VERSION ""

NS_ :

BS_:

BU_: SGW RFHM MPAD IPC GNMM EVCU2 ESL ECM DTCM DMSM BSM BCM AGSM ADCAM

BO_ 145 TELEMATIC_FD_19: 64 SGW
 SG_ Creep_Req : 389|1@0+ (1,0) [0|1] "" IPC
 SG_ PlugAndChargeReq : 385|1@0+ (1,0) [0|1] "" EVCU2
 SG_ StopOnTraffic_Req : 379|2@0+ (1,0) [0|2] "" IPC
 SG_ SpeedAdjust_Req : 380|1@0+ (1,0) [0|1] "" IPC
 SG_ RouteGuidance_Req : 383|1@0+ (1,0) [0|1] "" IPC
 SG_ EmergencyCorridorAssist_Req : 376|1@0+ (1,0) [0|1] "" IPC
 SG_ E_Coasting_Req : 399|3@0+ (1,0) [0|7] "" MPAD,EVCU2

BO_ 2654339283 PDC_INFO_FD_NFCD: 12 RFHM
 SG_ WakeupSource_FD09_NFCD : 23|8@0+ (1,0) [0|255] "" SGW
 SG_ StayActiveSource_FD09_NFCD : 31|64@0+ (1,0) [0|18446744073709551615] "" SGW
 SG_ PreviousCanNMState_FD09_NFCD : 11|4@0+ (1,0) [0|15] "" SGW
 SG_ GenericFailSts_FD09_NFCD : 5|1@0+ (1,0) [0|1] "" SGW,BCM
 SG_ EOL_FD09_NFCD : 7|1@0+ (1,0) [0|1] "-"  SGW,BCM
 SG_ DES_FD09_NFCD : 4|2@0+ (1,0) [0|3] "" SGW
 SG_ CurrentFailSts_FD09_NFCD : 6|1@0+ (1,0) [0|1] "" SGW,BCM
 SG_ CurrentCanNMState_FD09_NFCD : 15|4@0+ (1,0) [0|15] "" SGW

BO_ 2654339245 PDC_INFO_FD_MPAD: 12 MPAD
 SG_ WakeupSource_FD03_MPAD : 23|8@0+ (1,0) [0|255] "-"  SGW
 SG_ StayActiveSource_FD03_MPAD : 31|64@0+ (1,0) [0|18446744073709551615] "-"  SGW
 SG_ PreviousCanNMState_FD03_MPAD : 11|4@0+ (1,0) [0|15] "-"  SGW
 SG_ GenericFailSts_FD03_MPAD : 5|1@0+ (1,0) [0|1] "-"  SGW,BCM
 SG_ EOL_FD03_MPAD : 7|1@0+ (1,0) [0|1] "-"  SGW,BCM
 SG_ DES_FD03_MPAD : 4|2@0+ (1,0) [0|3] "-"  SGW
 SG_ CurrentFailSts_FD03_MPAD : 6|1@0+ (1,0) [0|1] "-"  SGW,BCM
 SG_ CurrentCanNMState_FD03_MPAD : 15|4@0+ (1,0) [0|15] "-"  SGW

BO_ 2654339233 PDC_INFO_FD_ADCAM: 12 ADCAM
 SG_ WakeupSource_FD03_ADCAM : 23|8@0+ (1,0) [0|255] "-"  SGW
 SG_ StayActiveSource_FD03_ADCAM : 31|64@0+ (1,0) [0|18446744073709551615] "-"  SGW
 SG_ PreviousCanNMState_FD03_ADCAM : 11|4@0+ (1,0) [0|15] "-"  SGW
 SG_ GenericFailSts_FD03_ADCAM : 5|1@0+ (1,0) [0|1] "-"  SGW,BCM
 SG_ EOL_FD03_ADCAM : 7|1@0+ (1,0) [0|1] "-"  SGW,BCM
 SG_ DES_FD03_ADCAM : 4|2@0+ (1,0) [0|3] "-"  SGW
 SG_ CurrentFailSts_FD03_ADCAM : 6|1@0+ (1,0) [0|1] "-"  SGW,BCM
 SG_ CurrentCanNMState_FD03_ADCAM : 15|4@0+ (1,0) [0|15] "-"  SGW

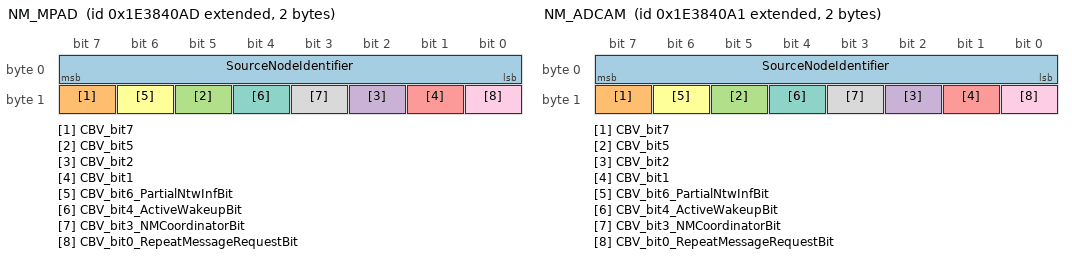
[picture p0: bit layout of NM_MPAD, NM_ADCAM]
BO_ 2654486701 NM_MPAD: 2 MPAD
 SG_ SourceNodeIdentifier : 7|8@0+ (1,0) [0|255] "-"  ADCAM,EVCU2,GNMM,SGW,AGSM,ESL,BCM,BSM,IPC,RFHM,ECM,DTCM
 SG_ CBV_bit7 : 15|1@0+ (1,0) [0|1] "" ADCAM,EVCU2,GNMM,SGW,AGSM,ESL,BCM,BSM,IPC,RFHM,ECM,DTCM
 SG_ CBV_bit5 : 13|1@0+ (1,0) [0|1] "" ADCAM,EVCU2,GNMM,SGW,AGSM,ESL,BCM,BSM,IPC,RFHM,ECM,DTCM
 SG_ CBV_bit2 : 10|1@0+ (1,0) [0|1] "" ADCAM,EVCU2,GNMM,SGW,AGSM,ESL,BCM,BSM,IPC,RFHM,ECM,DTCM
 SG_ CBV_bit1 : 9|1@0+ (1,0) [0|1] "" ADCAM,EVCU2,GNMM,SGW,AGSM,ESL,BCM,BSM,IPC,RFHM,ECM,DTCM
 SG_ CBV_bit6_PartialNtwInfBit : 14|1@0+ (1,0) [0|1] "-"  ADCAM,EVCU2,GNMM,SGW,AGSM,ESL,BCM,BSM,IPC,RFHM,ECM,DTCM
 SG_ CBV_bit4_ActiveWakeupBit : 12|1@0+ (1,0) [0|1] "-"  ADCAM,EVCU2,GNMM,SGW,AGSM,ESL,BCM,BSM,IPC,RFHM,ECM,DTCM
 SG_ CBV_bit3_NMCoordinatorBit : 11|1@0+ (1,0) [0|1] "-"  ADCAM,EVCU2,GNMM,SGW,AGSM,ESL,BCM,BSM,IPC,RFHM,ECM,DTCM
 SG_ CBV_bit0_RepeatMessageRequestBit : 8|1@0+ (1,0) [0|1] "-"  ADCAM,EVCU2,GNMM,SGW,AGSM,ESL,BCM,BSM,IPC,RFHM,ECM,DTCM

BO_ 2654486689 NM_ADCAM: 2 ADCAM
 SG_ SourceNodeIdentifier : 7|8@0+ (1,0) [0|255] "-"  MPAD,EVCU2,GNMM,SGW,AGSM,ESL,BCM,BSM,IPC,RFHM,ECM,DTCM
 SG_ CBV_bit7 : 15|1@0+ (1,0) [0|1] "" MPAD,EVCU2,GNMM,SGW,AGSM,ESL,BCM,BSM,IPC,RFHM,ECM,DTCM
 SG_ CBV_bit5 : 13|1@0+ (1,0) [0|1] "" MPAD,EVCU2,GNMM,SGW,AGSM,ESL,BCM,BSM,IPC,RFHM,ECM,DTCM
 SG_ CBV_bit2 : 10|1@0+ (1,0) [0|1] "" MPAD,EVCU2,GNMM,SGW,AGSM,ESL,BCM,BSM,IPC,RFHM,ECM,DTCM
 SG_ CBV_bit1 : 9|1@0+ (1,0) [0|1] "" MPAD,EVCU2,GNMM,SGW,AGSM,ESL,BCM,BSM,IPC,RFHM,ECM,DTCM
 SG_ CBV_bit6_PartialNtwInfBit : 14|1@0+ (1,0) [0|1] "-"  MPAD,EVCU2,GNMM,SGW,AGSM,ESL,BCM,BSM,IPC,RFHM,ECM,DTCM
 SG_ CBV_bit4_ActiveWakeupBit : 12|1@0+ (1,0) [0|1] "-"  MPAD,EVCU2,GNMM,SGW,AGSM,ESL,BCM,BSM,IPC,RFHM,ECM,DTCM
 SG_ CBV_bit3_NMCoordinatorBit : 11|1@0+ (1,0) [0|1] "-"  MPAD,EVCU2,GNMM,SGW,AGSM,ESL,BCM,BSM,IPC,RFHM,ECM,DTCM
 SG_ CBV_bit0_RepeatMessageRequestBit : 8|1@0+ (1,0) [0|1] "-"  MPAD,EVCU2,GNMM,SGW,AGSM,ESL,BCM,BSM,IPC,RFHM,ECM,DTCM

BO_ 1898 FOTA_RSP_MPAD: 32 MPAD
 SG_ Update_Status_MPAD : 5|2@0+ (1,0) [0|3] "" SGW
 SG_ Download_Status_MPAD : 7|2@0+ (1,0) [0|3] "" SGW
 SG_ Big_ECU_Ready_MPAD : 1|2@0+ (1,0) [0|3] "" SGW

BO_ 1900 FOTA_RSP_ADCAM: 32 ADCAM
 SG_ Update_Status_ADCAM : 5|2@0+ (1,0) [0|3] "" SGW
 SG_ Download_Status_ADCAM : 7|2@0+ (1,0) [0|3] "" SGW
 SG_ Big_ECU_Ready_ADCAM : 1|2@0+ (1,0) [0|3] "" SGW

BO_ 2564682142 DIAGNOSTIC_ROE_NFCD: 8 RFHM
 SG_ N_PDU : 7|64@0+ (1,0) [0|0] "" SGW

BO_ 2564682216 DIAGNOSTIC_ROE_MPAD: 8 MPAD
 SG_ N_PDU : 7|64@0+ (1,0) [0|0] "-"  SGW

BO_ 2564682398 DIAGNOSTIC_ROE_FD_NFCD: 64 RFHM
 SG_ N_PDU : 7|64@0+ (1,0) [0|0] "" SGW

BO_ 2564682472 DIAGNOSTIC_ROE_FD_MPAD: 64 MPAD
 SG_ N_PDU : 7|64@0+ (1,0) [0|0] "-"  SGW

BO_ 2564682306 DIAGNOSTIC_ROE_FD_EVCU2: 64 EVCU2
 SG_ N_PDU : 7|64@0+ (1,0) [0|0] "" SGW

BO_ 2564682279 DIAGNOSTIC_ROE_FD_ADCAM: 64 ADCAM
 SG_ N_PDU : 7|64@0+ (1,0) [0|0] "-"  SGW

BO_ 2564682050 DIAGNOSTIC_ROE_EVCU2: 8 EVCU2
 SG_ N_PDU : 7|64@0+ (1,0) [0|0] "" SGW

BO_ 2564682023 DIAGNOSTIC_ROE_ADCAM: 8 ADCAM
 SG_ N_PDU : 7|64@0+ (1,0) [0|0] "-"  SGW

BO_ 2564485534 DIAGNOSTIC_RESPONSE_NFCD: 8 RFHM
 SG_ N_PDU : 7|64@0+ (1,0) [0|0] "" SGW

BO_ 2564485608 DIAGNOSTIC_RESPONSE_MPAD: 8 MPAD
 SG_ N_PDU : 7|64@0+ (1,0) [0|0] "-"  SGW

BO_ 2564486632 DIAGNOSTIC_RESPONSE_FOTA_MPAD: 64 MPAD
 SG_ N_PDU : 7|64@0+ (1,0) [0|0] "" SGW

BO_ 2564486439 DIAGNOSTIC_RESPONSE_FOTA_ADCAM: 64 ADCAM
 SG_ N_PDU : 7|64@0+ (1,0) [0|0] "-"  SGW

BO_ 2564485790 DIAGNOSTIC_RESPONSE_FD_NFCD: 64 RFHM
 SG_ N_PDU : 7|64@0+ (1,0) [0|0] "" SGW

BO_ 2564485864 DIAGNOSTIC_RESPONSE_FD_MPAD: 64 MPAD
 SG_ N_PDU : 7|64@0+ (1,0) [0|0] "" SGW

BO_ 2564485698 DIAGNOSTIC_RESPONSE_FD_EVCU2: 64 EVCU2
 SG_ N_PDU : 7|64@0+ (1,0) [0|0] "" SGW

BO_ 2564485671 DIAGNOSTIC_RESPONSE_FD_ADCAM: 64 ADCAM
 SG_ N_PDU : 7|64@0+ (1,0) [0|0] "-"  SGW

BO_ 2564485442 DIAGNOSTIC_RESPONSE_EVCU2: 8 EVCU2
 SG_ N_PDU : 7|64@0+ (1,0) [0|0] "" SGW

BO_ 2564485415 DIAGNOSTIC_RESPONSE_ADCAM: 8 ADCAM
 SG_ N_PDU : 7|64@0+ (1,0) [0|0] "-"  SGW

BO_ 2564464369 DIAGNOSTIC_REQUEST_NFCD: 8 SGW
 SG_ N_PDU : 7|64@0+ (1,0) [0|0] "" RFHM

BO_ 2564483313 DIAGNOSTIC_REQUEST_MPAD: 8 SGW
 SG_ N_PDU : 7|64@0+ (1,0) [0|0] "-"  MPAD

BO_ 2564483317 DIAGNOSTIC_REQUEST_FOTA_MPAD: 64 SGW
 SG_ N_PDU : 7|64@0+ (1,0) [0|0] "-"  MPAD

BO_ 2564433909 DIAGNOSTIC_REQUEST_FOTA_ADCAM: 64 SGW
 SG_ N_PDU : 7|64@0+ (1,0) [0|0] "-"  ADCAM

BO_ 2564464370 DIAGNOSTIC_REQUEST_FD_NFCD: 64 SGW
 SG_ N_PDU : 7|64@0+ (1,0) [0|0] "" RFHM

BO_ 2564483314 DIAGNOSTIC_REQUEST_FD_MPAD: 64 SGW
 SG_ N_PDU : 7|64@0+ (1,0) [0|0] "-"  MPAD

BO_ 2564440818 DIAGNOSTIC_REQUEST_FD_EVCU2: 64 SGW
 SG_ N_PDU : 455|64@0+ (1,0) [0|0] "" EVCU2

BO_ 2564433906 DIAGNOSTIC_REQUEST_FD_ADCAM: 64 SGW
 SG_ N_PDU : 7|64@0+ (1,0) [0|0] "-"  ADCAM

BO_ 2564440817 DIAGNOSTIC_REQUEST_EVCU2: 8 SGW
 SG_ N_PDU : 7|64@0+ (1,0) [0|0] "" EVCU2

BO_ 2564433905 DIAGNOSTIC_REQUEST_ADCAM: 8 SGW
 SG_ N_PDU : 7|64@0+ (1,0) [0|0] "-"  ADCAM

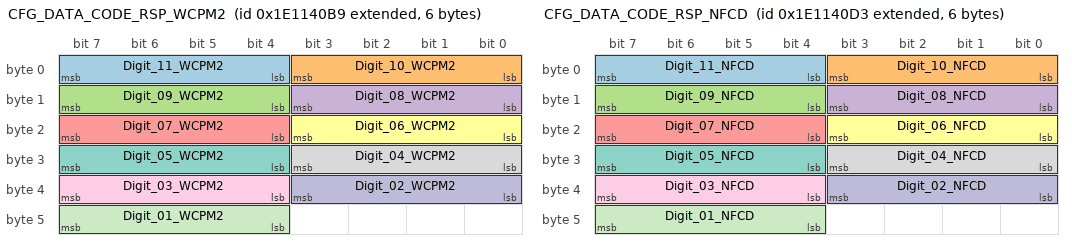
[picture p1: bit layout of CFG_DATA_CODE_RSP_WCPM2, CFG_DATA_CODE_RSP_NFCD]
BO_ 2651930809 CFG_DATA_CODE_RSP_WCPM2: 6 RFHM
 SG_ Digit_11_WCPM2 : 7|4@0+ (1,0) [0|15] "-"  BCM
 SG_ Digit_10_WCPM2 : 3|4@0+ (1,0) [0|15] "-"  BCM
 SG_ Digit_09_WCPM2 : 15|4@0+ (1,0) [0|15] "-"  BCM
 SG_ Digit_08_WCPM2 : 11|4@0+ (1,0) [0|15] "-"  BCM
 SG_ Digit_07_WCPM2 : 23|4@0+ (1,0) [0|15] "-"  BCM
 SG_ Digit_06_WCPM2 : 19|4@0+ (1,0) [0|15] "-"  BCM
 SG_ Digit_05_WCPM2 : 31|4@0+ (1,0) [0|15] "-"  BCM
 SG_ Digit_04_WCPM2 : 27|4@0+ (1,0) [0|15] "-"  BCM
 SG_ Digit_03_WCPM2 : 39|4@0+ (1,0) [0|15] "-"  BCM
 SG_ Digit_02_WCPM2 : 35|4@0+ (1,0) [0|15] "-"  BCM
 SG_ Digit_01_WCPM2 : 47|4@0+ (1,0) [0|15] "-"  BCM

BO_ 2651930835 CFG_DATA_CODE_RSP_NFCD: 6 RFHM
 SG_ Digit_11_NFCD : 7|4@0+ (1,0) [0|15] "-"  BCM
 SG_ Digit_10_NFCD : 3|4@0+ (1,0) [0|15] "-"  BCM
 SG_ Digit_09_NFCD : 15|4@0+ (1,0) [0|15] "-"  BCM
 SG_ Digit_08_NFCD : 11|4@0+ (1,0) [0|15] "-"  BCM
 SG_ Digit_07_NFCD : 23|4@0+ (1,0) [0|15] "-"  BCM
 SG_ Digit_06_NFCD : 19|4@0+ (1,0) [0|15] "-"  BCM
 SG_ Digit_05_NFCD : 31|4@0+ (1,0) [0|15] "-"  BCM
 SG_ Digit_04_NFCD : 27|4@0+ (1,0) [0|15] "-"  BCM
 SG_ Digit_03_NFCD : 39|4@0+ (1,0) [0|15] "-"  BCM
 SG_ Digit_02_NFCD : 35|4@0+ (1,0) [0|15] "-"  BCM
 SG_ Digit_01_NFCD : 47|4@0+ (1,0) [0|15] "-"  BCM

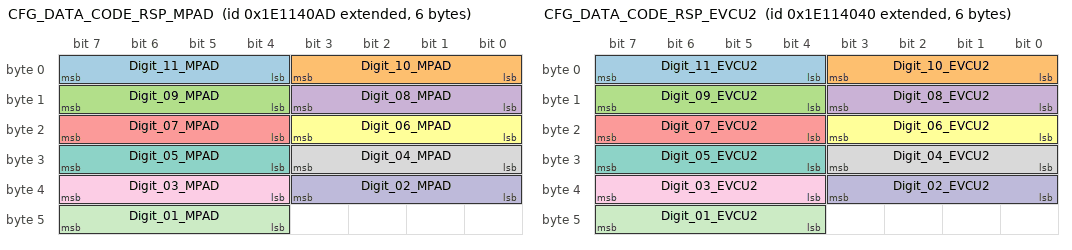
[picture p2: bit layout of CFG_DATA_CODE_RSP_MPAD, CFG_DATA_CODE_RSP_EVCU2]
BO_ 2651930797 CFG_DATA_CODE_RSP_MPAD: 6 MPAD
 SG_ Digit_11_MPAD : 7|4@0+ (1,0) [0|15] "-"  BCM
 SG_ Digit_10_MPAD : 3|4@0+ (1,0) [0|15] "-"  BCM
 SG_ Digit_09_MPAD : 15|4@0+ (1,0) [0|15] "-"  BCM
 SG_ Digit_08_MPAD : 11|4@0+ (1,0) [0|15] "-"  BCM
 SG_ Digit_07_MPAD : 23|4@0+ (1,0) [0|15] "-"  BCM
 SG_ Digit_06_MPAD : 19|4@0+ (1,0) [0|15] "-"  BCM
 SG_ Digit_05_MPAD : 31|4@0+ (1,0) [0|15] "-"  BCM
 SG_ Digit_04_MPAD : 27|4@0+ (1,0) [0|15] "-"  BCM
 SG_ Digit_03_MPAD : 39|4@0+ (1,0) [0|15] "-"  BCM
 SG_ Digit_02_MPAD : 35|4@0+ (1,0) [0|15] "-"  BCM
 SG_ Digit_01_MPAD : 47|4@0+ (1,0) [0|15] "-"  BCM

BO_ 2651930688 CFG_DATA_CODE_RSP_EVCU2: 6 EVCU2
 SG_ Digit_11_EVCU2 : 7|4@0+ (1,0) [0|15] "-"  BCM
 SG_ Digit_10_EVCU2 : 3|4@0+ (1,0) [0|15] "-"  BCM
 SG_ Digit_09_EVCU2 : 15|4@0+ (1,0) [0|15] "-"  BCM
 SG_ Digit_08_EVCU2 : 11|4@0+ (1,0) [0|15] "-"  BCM
 SG_ Digit_07_EVCU2 : 23|4@0+ (1,0) [0|15] "-"  BCM
 SG_ Digit_06_EVCU2 : 19|4@0+ (1,0) [0|15] "-"  BCM
 SG_ Digit_05_EVCU2 : 31|4@0+ (1,0) [0|15] "-"  BCM
 SG_ Digit_04_EVCU2 : 27|4@0+ (1,0) [0|15] "-"  BCM
 SG_ Digit_03_EVCU2 : 39|4@0+ (1,0) [0|15] "-"  BCM
 SG_ Digit_02_EVCU2 : 35|4@0+ (1,0) [0|15] "-"  BCM
 SG_ Digit_01_EVCU2 : 47|4@0+ (1,0) [0|15] "-"  BCM

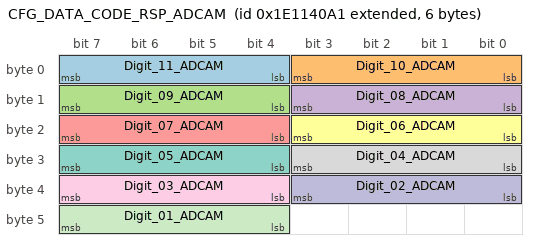
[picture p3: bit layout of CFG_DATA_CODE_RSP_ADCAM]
BO_ 2651930785 CFG_DATA_CODE_RSP_ADCAM: 6 ADCAM
 SG_ Digit_11_ADCAM : 7|4@0+ (1,0) [0|15] "-"  BCM
 SG_ Digit_10_ADCAM : 3|4@0+ (1,0) [0|15] "-"  BCM
 SG_ Digit_09_ADCAM : 15|4@0+ (1,0) [0|15] "-"  BCM
 SG_ Digit_08_ADCAM : 11|4@0+ (1,0) [0|15] "-"  BCM
 SG_ Digit_07_ADCAM : 23|4@0+ (1,0) [0|15] "-"  BCM
 SG_ Digit_06_ADCAM : 19|4@0+ (1,0) [0|15] "-"  BCM
 SG_ Digit_05_ADCAM : 31|4@0+ (1,0) [0|15] "-"  BCM
 SG_ Digit_04_ADCAM : 27|4@0+ (1,0) [0|15] "-"  BCM
 SG_ Digit_03_ADCAM : 39|4@0+ (1,0) [0|15] "-"  BCM
 SG_ Digit_02_ADCAM : 35|4@0+ (1,0) [0|15] "-"  BCM
 SG_ Digit_01_ADCAM : 47|4@0+ (1,0) [0|15] "-"  BCM

BO_ 2654339161 PDC_INFO_FD_MCPB: 32 EVCU2
 SG_ WakeupSource_FD16_MCPB : 95|8@0+ (1,0) [0|255] "" SGW
 SG_ WakeupSource_FD05_MCPB : 23|8@0+ (1,0) [0|255] "" SGW
 SG_ StayActiveSource_FD16_MCPB : 111|64@0+ (1,0) [0|0] "" SGW
 SG_ StayActiveSource_FD05_MCPB : 31|64@0+ (1,0) [0|0] "" SGW
 SG_ PreviousCanNMState_FD16_MCPB : 103|4@0+ (1,0) [0|15] "" SGW
 SG_ PreviousCanNMState_FD05_MCPB : 11|4@0+ (1,0) [0|15] "" SGW
 SG_ GenericFailSts_FD05_MCPB : 5|1@0+ (1,0) [0|1] "" SGW,BCM
 SG_ EOL_FD16_MCPB : 2|1@0+ (1,0) [0|1] "-"  SGW
 SG_ EOL_FD05_MCPB : 7|1@0+ (1,0) [0|1] "-"  SGW,BCM
 SG_ DES_FD05_MCPB : 4|2@0+ (1,0) [0|3] "" SGW
 SG_ CurrentFailSts_FD05_MCPB : 6|1@0+ (1,0) [0|1] "" SGW,BCM
 SG_ CurrentCanNMState_FD16_MCPB : 99|4@0+ (1,0) [0|15] "" SGW
 SG_ CurrentCanNMState_FD05_MCPB : 15|4@0+ (1,0) [0|15] "" SGW
 SG_ GenericFailSts_FD16_MCPB : 172|1@0+ (1,0) [0|1] "" SGW
 SG_ DES_FD16_MCPB : 175|2@0+ (1,0) [0|3] "" SGW
 SG_ CurrentFailSts_FD16_MCPB : 173|1@0+ (1,0) [0|1] "" SGW

BO_ 2654339160 PDC_INFO_FD_MCPA: 32 EVCU2
 SG_ WakeupSource_FD16_MCPA : 95|8@0+ (1,0) [0|255] "" SGW
 SG_ WakeupSource_FD05_MCPA : 23|8@0+ (1,0) [0|255] "" SGW
 SG_ StayActiveSource_FD16_MCPA : 111|64@0+ (1,0) [0|0] "" SGW
 SG_ StayActiveSource_FD05_MCPA : 31|64@0+ (1,0) [0|0] "" SGW
 SG_ PreviousCanNMState_FD16_MCPA : 103|4@0+ (1,0) [0|15] "" SGW
 SG_ PreviousCanNMState_FD05_MCPA : 11|4@0+ (1,0) [0|15] "" SGW
 SG_ GenericFailSts_FD05_MCPA : 5|1@0+ (1,0) [0|1] "" SGW,BCM
 SG_ EOL_FD16_MCPA : 2|1@0+ (1,0) [0|1] "-"  SGW
 SG_ EOL_FD05_MCPA : 7|1@0+ (1,0) [0|1] "-"  SGW,BCM
 SG_ DES_FD05_MCPA : 4|2@0+ (1,0) [0|3] "" SGW
 SG_ CurrentFailSts_FD05_MCPA : 6|1@0+ (1,0) [0|1] "" SGW,BCM
 SG_ CurrentCanNMState_FD16_MCPA : 99|4@0+ (1,0) [0|15] "" SGW
 SG_ CurrentCanNMState_FD05_MCPA : 15|4@0+ (1,0) [0|15] "" SGW
 SG_ GenericFailSts_FD16_MCPA : 172|1@0+ (1,0) [0|1] "" SGW
 SG_ DES_FD16_MCPA : 175|2@0+ (1,0) [0|3] "" SGW
 SG_ CurrentFailSts_FD16_MCPA : 173|1@0+ (1,0) [0|1] "" SGW

CM_ SG_ 145 StopOnTraffic_Req "Customer Setting - Stop on Traffic";
CM_ SG_ 145 SpeedAdjust_Req "Customer Setting - Speed Adjust";
CM_ SG_ 145 RouteGuidance_Req "Customer Setting - Route Guidance";
CM_ SG_ 145 PlugAndChargeReq "HU Activation Request for for Plug & Change";
CM_ SG_ 145 EmergencyCorridorAssist_Req "Customer Setting - Emergency Corridor Assist";
CM_ SG_ 145 E_Coasting_Req "HU request for setting current e-Coasting level";
CM_ SG_ 145 Creep_Req "Customer Setting - Creep feature";
CM_ SG_ 2654339283 CurrentFailSts_FD09_NFCD "Indicates the presence/absence of at least one DTC with DTCStatus = present in the System Memory";
CM_ SG_ 2654339283 DES_FD09_NFCD "Indicates whether the ECU?s CAN cell is in either ErrorActive, or ErrorPassive state OR has just now recovered from a BusOff condition";
CM_ SG_ 2654339283 EOL_FD09_NFCD "Indicates if the ECU requires configuration data at the assembly plant End Of Line";
CM_ SG_ 2654339283 GenericFailSts_FD09_NFCD "Indicates the presence/absent of at least one DTC in the System Memory";
CM_ SG_ 2654339283 PreviousCanNMState_FD09_NFCD "Indicates the last CanNM state that the ECU existed in";
CM_ SG_ 2654339283 StayActiveSource_FD09_NFCD "Indicates the source that requests the ECU to stay active";
CM_ SG_ 2654339283 WakeupSource_FD09_NFCD "Indicates the reason the ECU was most recently awakened";
CM_ SG_ 2654339283 CurrentCanNMState_FD09_NFCD "Indicates that CanNM state the ECU is currently executing";
CM_ SG_ 2654339245 StayActiveSource_FD03_MPAD "Indicates the source that requests the ECU to stay active";
CM_ SG_ 2654339245 PreviousCanNMState_FD03_MPAD "Indicates the last CanNM state that the ECU existed in";
CM_ SG_ 2654339245 GenericFailSts_FD03_MPAD "Indicates the presence/absent of at least one DTC in the System Memory";
CM_ SG_ 2654339245 EOL_FD03_MPAD "Indicates if the ECU requires configuration data at the assembly plant End Of Line";
CM_ SG_ 2654339245 DES_FD03_MPAD "Indicates whether the ECU?s CAN cell is in either ErrorActive, or ErrorPassive state OR has just now recovered from a BusOff condition";
CM_ SG_ 2654339245 CurrentFailSts_FD03_MPAD "Indicates the presence/absence of at least one DTC with DTCStatus = present in the System Memory";
CM_ SG_ 2654339245 WakeupSource_FD03_MPAD "Indicates the reason the ECU was most recently awakened";
CM_ SG_ 2654339245 CurrentCanNMState_FD03_MPAD "Indicates that CanNM state the ECU is currently executing";
CM_ SG_ 2654339233 DES_FD03_ADCAM "Indicates whether the ECU?s CAN cell is in either ErrorActive, or ErrorPassive state OR has just now recovered from a BusOff condition";
CM_ SG_ 2654339233 EOL_FD03_ADCAM "Indicates if the ECU requires configuration data at the assembly plant End Of Line";
CM_ SG_ 2654339233 GenericFailSts_FD03_ADCAM "Indicates the presence/absent of at least one DTC in the System Memory";
CM_ SG_ 2654339233 CurrentCanNMState_FD03_ADCAM "Indicates that CanNM state the ECU is currently executing";
CM_ SG_ 2654339233 CurrentFailSts_FD03_ADCAM "Indicates the presence/absence of at least one DTC with DTCStatus = present in the System Memory";
CM_ SG_ 2654339233 WakeupSource_FD03_ADCAM "Indicates the reason the ECU was most recently awakened";
CM_ SG_ 2654339233 StayActiveSource_FD03_ADCAM "Indicates the source that requests the ECU to stay active";
CM_ SG_ 2654339233 PreviousCanNMState_FD03_ADCAM "Indicates the last CanNM state that the ECU existed in";
CM_ SG_ 2654486701 CBV_bit0_RepeatMessageRequestBit "Repeat Message Request Bit";
CM_ SG_ 2654486701 CBV_bit3_NMCoordinatorBit "NM Coordinator Sleep Bit";
CM_ SG_ 2654486701 CBV_bit4_ActiveWakeupBit "Active Wakeup Bit";
CM_ SG_ 2654486701 CBV_bit6_PartialNtwInfBit "Partial Network Information Bit (PNI)";
CM_ SG_ 2654486701 SourceNodeIdentifier "Source Node Identifier";
CM_ SG_ 2654486689 CBV_bit0_RepeatMessageRequestBit "Repeat Message Request Bit";
CM_ SG_ 2654486689 CBV_bit3_NMCoordinatorBit "NM Coordinator Sleep Bit";
CM_ SG_ 2654486689 CBV_bit4_ActiveWakeupBit "Active Wakeup Bit";
CM_ SG_ 2654486689 CBV_bit6_PartialNtwInfBit "Partial Network Information Bit (PNI)";
CM_ SG_ 2654486689 SourceNodeIdentifier "Source Node Identifier";
CM_ SG_ 1898 Big_ECU_Ready_MPAD "Big_ECU_Ready_TBM";
CM_ SG_ 1898 Download_Status_MPAD "Download_Status_TBM";
CM_ SG_ 1898 Update_Status_MPAD "Update_Status_TBM";
CM_ SG_ 1900 Big_ECU_Ready_ADCAM "Big_ECU_Ready_TBM";
CM_ SG_ 1900 Download_Status_ADCAM "Download_Status_TBM";
CM_ SG_ 1900 Update_Status_ADCAM "Update_Status_TBM";
CM_ SG_ 2564682142 N_PDU "This signal is used for diagnostic purposes";
CM_ SG_ 2564682216 N_PDU "This signal is used for diagnostic purposes";
CM_ SG_ 2564682398 N_PDU "This signal is used for diagnostic purposes";
CM_ SG_ 2564682472 N_PDU "This signal is used for diagnostic purposes";
CM_ SG_ 2564682306 N_PDU "This signal is used for diagnostic purposes";
CM_ SG_ 2564682279 N_PDU "This signal is used for diagnostic purposes";
CM_ SG_ 2564682050 N_PDU "This signal is used for diagnostic purposes";
CM_ SG_ 2564682023 N_PDU "This signal is used for diagnostic purposes";
CM_ SG_ 2564485534 N_PDU "This signal is used for diagnostic purposes";
CM_ SG_ 2564485608 N_PDU "This signal is used for diagnostic purposes";
CM_ SG_ 2564486632 N_PDU "This signal is used for diagnostic purposes";
CM_ SG_ 2564486439 N_PDU "This signal is used for diagnostic purposes";
CM_ SG_ 2564485790 N_PDU "This signal is used for diagnostic purposes";
CM_ SG_ 2564485864 N_PDU "This signal is used for diagnostic purposes";
CM_ SG_ 2564485698 N_PDU "This signal is used for diagnostic purposes";
CM_ SG_ 2564485671 N_PDU "This signal is used for diagnostic purposes";
CM_ SG_ 2564485442 N_PDU "This signal is used for diagnostic purposes";
CM_ SG_ 2564485415 N_PDU "This signal is used for diagnostic purposes";
CM_ SG_ 2564464369 N_PDU "This signal is used for diagnostic purposes";
CM_ SG_ 2564483313 N_PDU "This signal is used for diagnostic purposes";
CM_ SG_ 2564483317 N_PDU "This signal is used for diagnostic purposes";
CM_ SG_ 2564433909 N_PDU "This signal is used for diagnostic purposes";
CM_ SG_ 2564464370 N_PDU "This signal is used for diagnostic purposes";
CM_ SG_ 2564483314 N_PDU "This signal is used for diagnostic purposes";
CM_ SG_ 2564440818 N_PDU "This signal is used for diagnostic purposes";
CM_ SG_ 2564433906 N_PDU "This signal is used for diagnostic purposes";
CM_ SG_ 2564440817 N_PDU "This signal is used for diagnostic purposes";
CM_ SG_ 2564433905 N_PDU "This signal is used for diagnostic purposes";
CM_ SG_ 2654339161 GenericFailSts_FD05_MCPB "Indicates the presence/absent of at least one DTC in the System Memory";
CM_ SG_ 2654339161 GenericFailSts_FD16_MCPB "Indicates the presence/absent of at least one DTC in the System Memory";
CM_ SG_ 2654339161 PreviousCanNMState_FD05_MCPB "Indicates the last CanNM state that the ECU existed in";
CM_ SG_ 2654339161 PreviousCanNMState_FD16_MCPB "Indicates the last CanNM state that the ECU existed in";
CM_ SG_ 2654339161 WakeupSource_FD05_MCPB "Indicates the reason the ECU was most recently awakened";
CM_ SG_ 2654339161 WakeupSource_FD16_MCPB "Indicates the reason the ECU was most recently awakened";
CM_ SG_ 2654339161 StayActiveSource_FD16_MCPB "Indicates the source that requests the ECU to stay active";
CM_ SG_ 2654339161 StayActiveSource_FD05_MCPB "Indicates the source that requests the ECU to stay active";
CM_ SG_ 2654339161 EOL_FD16_MCPB "Indicates if the ECU requires configuration data at the assembly plant End Of Line";
CM_ SG_ 2654339161 DES_FD16_MCPB "Indicates whether the ECU?s CAN cell is in either ErrorActive, or ErrorPassive state OR has just now recovered from a BusOff condition";
CM_ SG_ 2654339161 EOL_FD05_MCPB "Indicates if the ECU requires configuration data at the assembly plant End Of Line";
CM_ SG_ 2654339161 CurrentCanNMState_FD05_MCPB "Indicates that CanNM state the ECU is currently executing";
CM_ SG_ 2654339161 CurrentCanNMState_FD16_MCPB "Indicates that CanNM state the ECU is currently executing";
CM_ SG_ 2654339161 CurrentFailSts_FD05_MCPB "Indicates the presence/absence of at least one DTC with DTCStatus = present in the System Memory";
CM_ SG_ 2654339161 CurrentFailSts_FD16_MCPB "Indicates the presence/absence of at least one DTC with DTCStatus = present in the System Memory";
CM_ SG_ 2654339161 DES_FD05_MCPB "Indicates whether the ECU?s CAN cell is in either ErrorActive, or ErrorPassive state OR has just now recovered from a BusOff condition";
CM_ SG_ 2654339160 DES_FD05_MCPA "Indicates whether the ECU?s CAN cell is in either ErrorActive, or ErrorPassive state OR has just now recovered from a BusOff condition";
CM_ SG_ 2654339160 DES_FD16_MCPA "Indicates whether the ECU?s CAN cell is in either ErrorActive, or ErrorPassive state OR has just now recovered from a BusOff condition";
CM_ SG_ 2654339160 EOL_FD05_MCPA "Indicates if the ECU requires configuration data at the assembly plant End Of Line";
CM_ SG_ 2654339160 EOL_FD16_MCPA "Indicates if the ECU requires configuration data at the assembly plant End Of Line";
CM_ SG_ 2654339160 GenericFailSts_FD05_MCPA "Indicates the presence/absent of at least one DTC in the System Memory";
CM_ SG_ 2654339160 GenericFailSts_FD16_MCPA "Indicates the presence/absent of at least one DTC in the System Memory";
CM_ SG_ 2654339160 PreviousCanNMState_FD05_MCPA "Indicates the last CanNM state that the ECU existed in";
CM_ SG_ 2654339160 StayActiveSource_FD05_MCPA "Indicates the source that requests the ECU to stay active";
CM_ SG_ 2654339160 PreviousCanNMState_FD16_MCPA "Indicates the last CanNM state that the ECU existed in";
CM_ SG_ 2654339160 StayActiveSource_FD16_MCPA "Indicates the source that requests the ECU to stay active";
CM_ SG_ 2654339160 WakeupSource_FD05_MCPA "Indicates the reason the ECU was most recently awakened";
CM_ SG_ 2654339160 WakeupSource_FD16_MCPA "Indicates the reason the ECU was most recently awakened";
CM_ SG_ 2654339160 CurrentCanNMState_FD05_MCPA "Indicates that CanNM state the ECU is currently executing";
CM_ SG_ 2654339160 CurrentCanNMState_FD16_MCPA "Indicates that CanNM state the ECU is currently executing";
CM_ SG_ 2654339160 CurrentFailSts_FD05_MCPA "Indicates the presence/absence of at least one DTC with DTCStatus = present in the System Memory";
CM_ SG_ 2654339160 CurrentFailSts_FD16_MCPA "Indicates the presence/absence of at least one DTC with DTCStatus = present in the System Memory";
BA_DEF_ BO_ "CANFD_BRS" ENUM "0","1";
BA_DEF_ BO_ "VFrameFormat" ENUM "StandardCAN","ExtendedCAN","reserved","reserved","reserved","reserved","reserved","reserved","reserved","reserved","reserved","reserved","reserved","reserved","StandardCAN_FD","ExtendedCAN_FD";
BA_DEF_ BO_ "DiagConnection" HEX 0 65535;
BA_DEF_ BO_ "DiagState" ENUM "No","Yes";
BA_DEF_ BO_ "NmAsrMessage" ENUM "No","Yes";
BA_DEF_ BO_ "GenMsgDelayTime" INT 0 65535;
BA_DEF_ BO_ "GenMsgCycleTime" INT 0 65535;
BA_DEF_ BO_ "GenMsgCycleTimeFast" INT 0 65535;
BA_DEF_ BO_ "GenMsgStartDelayTime" INT 0 65535;
BA_DEF_ BO_ "GenMsgILSupport" ENUM "No","Yes";
BA_DEF_ BO_ "GenMsgNrOfRepetition" INT 0 255;
BA_DEF_ BO_ "GenMsgSendType" ENUM "Cyclic","NotUsed","NotUsed","NotUsed","NotUsed","NotUsed","NotUsed","NotUsed","NoMsgSendType";
BA_DEF_ BO_ "NmMessage" ENUM "No","Yes";
BA_DEF_ BO_ "DiagResponse" ENUM "No","Yes";
BA_DEF_ BO_ "Type" ENUM "P","C","PE","COC","PE_Cntrl","E","E_Cntrl","OC","S","BAF","DC","EM","MM","ISO-TP","-";
BA_DEF_ BO_ "DiagRequest" ENUM "No","Yes";
BA_DEF_ SG_ "GenSigTimeoutTime_SGW" INT 0 65535;
BA_DEF_ SG_ "GenSigTimeoutTime_RFHM" INT 0 65535;
BA_DEF_ SG_ "GenSigTimeoutTime_MPAD" INT 0 65535;
BA_DEF_ SG_ "GenSigTimeoutTime_IPC" INT 0 65535;
BA_DEF_ SG_ "GenSigTimeoutTime_GNMM" INT 0 65535;
BA_DEF_ SG_ "GenSigTimeoutTime_EVCU2" INT 0 65535;
BA_DEF_ SG_ "GenSigTimeoutTime_ESL" INT 0 65535;
BA_DEF_ SG_ "GenSigTimeoutTime_ECM" INT 0 65535;
BA_DEF_ SG_ "GenSigTimeoutTime_DTCM" INT 0 65535;
BA_DEF_ SG_ "GenSigTimeoutTime_DMSM" INT 0 65535;
BA_DEF_ SG_ "GenSigTimeoutTime_BSM" INT 0 65535;
BA_DEF_ SG_ "GenSigTimeoutTime_BCM" INT 0 65535;
BA_DEF_ SG_ "GenSigTimeoutTime_AGSM" INT 0 65535;
BA_DEF_ SG_ "GenSigTimeoutTime_ADCAM" INT 0 65535;
BA_DEF_ SG_ "SystemSignalLongSymbol" STRING ;
BA_DEF_ SG_ "GenSigSendType" ENUM "NotUsed","OnWrite","OnWriteWithRepetition","OnChange","OnChangeWithRepetition","IfActive","IfActiveWithRepetition","NoSigSendType";
BA_DEF_ SG_ "GenSigInactiveValue" INT 0 2147483647;
BA_DEF_ SG_ "GenSigStartValue" INT 0 2147483647;
BA_DEF_DEF_ "CANFD_BRS" "0";
BA_DEF_DEF_ "VFrameFormat" "StandardCAN_FD";
BA_DEF_DEF_ "DiagConnection" 0;
BA_DEF_DEF_ "DiagState" "No";
BA_DEF_DEF_ "NmAsrMessage" "No";
BA_DEF_DEF_ "GenMsgDelayTime" 0;
BA_DEF_DEF_ "GenMsgCycleTime" 0;
BA_DEF_DEF_ "GenMsgCycleTimeFast" 0;
BA_DEF_DEF_ "GenMsgStartDelayTime" 0;
BA_DEF_DEF_ "GenMsgILSupport" "No";
BA_DEF_DEF_ "GenMsgNrOfRepetition" 0;
BA_DEF_DEF_ "GenMsgSendType" "NoMsgSendType";
BA_DEF_DEF_ "NmMessage" "No";
BA_DEF_DEF_ "DiagResponse" "No";
BA_DEF_DEF_ "Type" "-";
BA_DEF_DEF_ "DiagRequest" "No";
BA_DEF_DEF_ "GenSigTimeoutTime_SGW" 2500;
BA_DEF_DEF_ "GenSigTimeoutTime_RFHM" 2500;
BA_DEF_DEF_ "GenSigTimeoutTime_MPAD" 2500;
BA_DEF_DEF_ "GenSigTimeoutTime_IPC" 2500;
BA_DEF_DEF_ "GenSigTimeoutTime_GNMM" 2500;
BA_DEF_DEF_ "GenSigTimeoutTime_EVCU2" 2500;
BA_DEF_DEF_ "GenSigTimeoutTime_ESL" 2500;
BA_DEF_DEF_ "GenSigTimeoutTime_ECM" 2500;
BA_DEF_DEF_ "GenSigTimeoutTime_DTCM" 2500;
BA_DEF_DEF_ "GenSigTimeoutTime_DMSM" 2500;
BA_DEF_DEF_ "GenSigTimeoutTime_BSM" 2500;
BA_DEF_DEF_ "GenSigTimeoutTime_BCM" 2500;
BA_DEF_DEF_ "GenSigTimeoutTime_AGSM" 2500;
BA_DEF_DEF_ "GenSigTimeoutTime_ADCAM" 2500;
BA_DEF_DEF_ "SystemSignalLongSymbol" "";
BA_DEF_DEF_ "GenSigSendType" "NoSigSendType";
BA_DEF_DEF_ "GenSigInactiveValue" 0;
BA_DEF_DEF_ "GenSigStartValue" 0;
BA_ "CANFD_BRS" BO_ 145 1;
BA_ "GenMsgCycleTime" BO_ 145 1000;
BA_ "GenMsgILSupport" BO_ 145 1;
BA_ "GenMsgSendType" BO_ 145 0;
BA_ "Type" BO_ 145 3;
BA_ "CANFD_BRS" BO_ 2654339283 1;
BA_ "VFrameFormat" BO_ 2654339283 15;
BA_ "GenMsgCycleTime" BO_ 2654339283 1000;
BA_ "GenMsgILSupport" BO_ 2654339283 1;
BA_ "GenMsgSendType" BO_ 2654339283 0;
BA_ "Type" BO_ 2654339283 1;
BA_ "CANFD_BRS" BO_ 2654339245 1;
BA_ "VFrameFormat" BO_ 2654339245 15;
BA_ "GenMsgCycleTime" BO_ 2654339245 1000;
BA_ "GenMsgILSupport" BO_ 2654339245 1;
BA_ "GenMsgSendType" BO_ 2654339245 0;
BA_ "Type" BO_ 2654339245 1;
BA_ "CANFD_BRS" BO_ 2654339233 1;
BA_ "VFrameFormat" BO_ 2654339233 15;
BA_ "GenMsgCycleTime" BO_ 2654339233 1000;
BA_ "GenMsgILSupport" BO_ 2654339233 1;
BA_ "GenMsgSendType" BO_ 2654339233 0;
BA_ "Type" BO_ 2654339233 1;
BA_ "CANFD_BRS" BO_ 2654486701 1;
BA_ "VFrameFormat" BO_ 2654486701 15;
BA_ "NmAsrMessage" BO_ 2654486701 1;
BA_ "NmMessage" BO_ 2654486701 1;
BA_ "Type" BO_ 2654486701 8;
BA_ "CANFD_BRS" BO_ 2654486689 1;
BA_ "VFrameFormat" BO_ 2654486689 15;
BA_ "NmAsrMessage" BO_ 2654486689 1;
BA_ "NmMessage" BO_ 2654486689 1;
BA_ "Type" BO_ 2654486689 8;
BA_ "CANFD_BRS" BO_ 1898 1;
BA_ "GenMsgDelayTime" BO_ 1898 20;
BA_ "GenMsgCycleTime" BO_ 1898 1000;
BA_ "GenMsgCycleTimeFast" BO_ 1898 20;
BA_ "GenMsgILSupport" BO_ 1898 1;
BA_ "GenMsgNrOfRepetition" BO_ 1898 2;
BA_ "GenMsgSendType" BO_ 1898 0;
BA_ "Type" BO_ 1898 1;
BA_ "CANFD_BRS" BO_ 1900 1;
BA_ "GenMsgDelayTime" BO_ 1900 20;
BA_ "GenMsgCycleTime" BO_ 1900 1000;
BA_ "GenMsgCycleTimeFast" BO_ 1900 20;
BA_ "GenMsgILSupport" BO_ 1900 1;
BA_ "GenMsgNrOfRepetition" BO_ 1900 2;
BA_ "GenMsgSendType" BO_ 1900 0;
BA_ "Type" BO_ 1900 1;
BA_ "VFrameFormat" BO_ 2564682142 1;
BA_ "DiagConnection" BO_ 2564682142 61854;
BA_ "DiagResponse" BO_ 2564682142 1;
BA_ "Type" BO_ 2564682142 8;
BA_ "VFrameFormat" BO_ 2564682216 1;
BA_ "DiagConnection" BO_ 2564682216 61928;
BA_ "DiagResponse" BO_ 2564682216 1;
BA_ "Type" BO_ 2564682216 8;
BA_ "CANFD_BRS" BO_ 2564682398 1;
BA_ "VFrameFormat" BO_ 2564682398 15;
BA_ "DiagConnection" BO_ 2564682398 62110;
BA_ "DiagResponse" BO_ 2564682398 1;
BA_ "Type" BO_ 2564682398 8;
BA_ "CANFD_BRS" BO_ 2564682472 1;
BA_ "VFrameFormat" BO_ 2564682472 15;
BA_ "DiagConnection" BO_ 2564682472 62184;
BA_ "DiagResponse" BO_ 2564682472 1;
BA_ "Type" BO_ 2564682472 8;
BA_ "CANFD_BRS" BO_ 2564682306 1;
BA_ "VFrameFormat" BO_ 2564682306 15;
BA_ "DiagConnection" BO_ 2564682306 62018;
BA_ "DiagResponse" BO_ 2564682306 1;
BA_ "Type" BO_ 2564682306 8;
BA_ "CANFD_BRS" BO_ 2564682279 1;
BA_ "VFrameFormat" BO_ 2564682279 15;
BA_ "DiagConnection" BO_ 2564682279 61991;
BA_ "DiagResponse" BO_ 2564682279 1;
BA_ "Type" BO_ 2564682279 8;
BA_ "VFrameFormat" BO_ 2564682050 1;
BA_ "DiagConnection" BO_ 2564682050 61762;
BA_ "DiagResponse" BO_ 2564682050 1;
BA_ "Type" BO_ 2564682050 8;
BA_ "VFrameFormat" BO_ 2564682023 1;
BA_ "DiagConnection" BO_ 2564682023 61735;
BA_ "DiagResponse" BO_ 2564682023 1;
BA_ "Type" BO_ 2564682023 8;
BA_ "VFrameFormat" BO_ 2564485534 1;
BA_ "DiagConnection" BO_ 2564485534 61854;
BA_ "DiagResponse" BO_ 2564485534 1;
BA_ "Type" BO_ 2564485534 8;
BA_ "VFrameFormat" BO_ 2564485608 1;
BA_ "DiagConnection" BO_ 2564485608 61928;
BA_ "DiagResponse" BO_ 2564485608 1;
BA_ "Type" BO_ 2564485608 8;
BA_ "DiagResponse" BO_ 2564486632 1;
BA_ "Type" BO_ 2564486632 8;
BA_ "CANFD_BRS" BO_ 2564486632 1;
BA_ "VFrameFormat" BO_ 2564486632 15;
BA_ "DiagConnection" BO_ 2564486632 62952;
BA_ "CANFD_BRS" BO_ 2564486439 1;
BA_ "VFrameFormat" BO_ 2564486439 15;
BA_ "DiagConnection" BO_ 2564486439 62759;
BA_ "DiagResponse" BO_ 2564486439 1;
BA_ "Type" BO_ 2564486439 8;
BA_ "CANFD_BRS" BO_ 2564485790 1;
BA_ "VFrameFormat" BO_ 2564485790 15;
BA_ "DiagConnection" BO_ 2564485790 62110;
BA_ "DiagResponse" BO_ 2564485790 1;
BA_ "Type" BO_ 2564485790 8;
BA_ "CANFD_BRS" BO_ 2564485864 1;
BA_ "VFrameFormat" BO_ 2564485864 15;
BA_ "DiagConnection" BO_ 2564485864 62184;
BA_ "DiagResponse" BO_ 2564485864 1;
BA_ "Type" BO_ 2564485864 8;
BA_ "CANFD_BRS" BO_ 2564485698 1;
BA_ "VFrameFormat" BO_ 2564485698 15;
BA_ "DiagConnection" BO_ 2564485698 62018;
BA_ "DiagResponse" BO_ 2564485698 1;
BA_ "Type" BO_ 2564485698 8;
BA_ "CANFD_BRS" BO_ 2564485671 1;
BA_ "VFrameFormat" BO_ 2564485671 15;
BA_ "DiagConnection" BO_ 2564485671 61991;
BA_ "DiagResponse" BO_ 2564485671 1;
BA_ "Type" BO_ 2564485671 8;
BA_ "DiagResponse" BO_ 2564485442 1;
BA_ "Type" BO_ 2564485442 8;
BA_ "VFrameFormat" BO_ 2564485442 1;
BA_ "DiagConnection" BO_ 2564485442 61762;
BA_ "VFrameFormat" BO_ 2564485415 1;
BA_ "DiagConnection" BO_ 2564485415 61735;
BA_ "DiagResponse" BO_ 2564485415 1;
BA_ "Type" BO_ 2564485415 8;
BA_ "VFrameFormat" BO_ 2564464369 1;
BA_ "DiagConnection" BO_ 2564464369 61854;
BA_ "Type" BO_ 2564464369 8;
BA_ "DiagRequest" BO_ 2564464369 1;
BA_ "VFrameFormat" BO_ 2564483313 1;
BA_ "DiagConnection" BO_ 2564483313 61928;
BA_ "Type" BO_ 2564483313 8;
BA_ "DiagRequest" BO_ 2564483313 1;
BA_ "CANFD_BRS" BO_ 2564483317 1;
BA_ "VFrameFormat" BO_ 2564483317 15;
BA_ "DiagConnection" BO_ 2564483317 62952;
BA_ "Type" BO_ 2564483317 8;
BA_ "DiagRequest" BO_ 2564483317 1;
BA_ "CANFD_BRS" BO_ 2564433909 1;
BA_ "VFrameFormat" BO_ 2564433909 15;
BA_ "DiagConnection" BO_ 2564433909 62759;
BA_ "Type" BO_ 2564433909 8;
BA_ "DiagRequest" BO_ 2564433909 1;
BA_ "CANFD_BRS" BO_ 2564464370 1;
BA_ "VFrameFormat" BO_ 2564464370 15;
BA_ "DiagConnection" BO_ 2564464370 62110;
BA_ "Type" BO_ 2564464370 8;
BA_ "DiagRequest" BO_ 2564464370 1;
BA_ "CANFD_BRS" BO_ 2564483314 1;
BA_ "VFrameFormat" BO_ 2564483314 15;
BA_ "DiagConnection" BO_ 2564483314 62184;
BA_ "Type" BO_ 2564483314 8;
BA_ "DiagRequest" BO_ 2564483314 1;
BA_ "CANFD_BRS" BO_ 2564440818 1;
BA_ "VFrameFormat" BO_ 2564440818 15;
BA_ "DiagConnection" BO_ 2564440818 62018;
BA_ "Type" BO_ 2564440818 8;
BA_ "DiagRequest" BO_ 2564440818 1;
BA_ "CANFD_BRS" BO_ 2564433906 1;
BA_ "VFrameFormat" BO_ 2564433906 15;
BA_ "DiagConnection" BO_ 2564433906 61991;
BA_ "Type" BO_ 2564433906 8;
BA_ "DiagRequest" BO_ 2564433906 1;
BA_ "VFrameFormat" BO_ 2564440817 1;
BA_ "DiagConnection" BO_ 2564440817 61762;
BA_ "Type" BO_ 2564440817 8;
BA_ "DiagRequest" BO_ 2564440817 1;
BA_ "Type" BO_ 2564433905 8;
BA_ "DiagRequest" BO_ 2564433905 1;
BA_ "VFrameFormat" BO_ 2564433905 1;
BA_ "DiagConnection" BO_ 2564433905 61735;
BA_ "CANFD_BRS" BO_ 2651930809 1;
BA_ "VFrameFormat" BO_ 2651930809 15;
BA_ "GenMsgILSupport" BO_ 2651930809 1;
BA_ "Type" BO_ 2651930809 11;
BA_ "CANFD_BRS" BO_ 2651930835 1;
BA_ "VFrameFormat" BO_ 2651930835 15;
BA_ "GenMsgILSupport" BO_ 2651930835 1;
BA_ "Type" BO_ 2651930835 11;
BA_ "CANFD_BRS" BO_ 2651930797 1;
BA_ "VFrameFormat" BO_ 2651930797 15;
BA_ "GenMsgILSupport" BO_ 2651930797 1;
BA_ "Type" BO_ 2651930797 11;
BA_ "CANFD_BRS" BO_ 2651930688 1;
BA_ "VFrameFormat" BO_ 2651930688 15;
BA_ "GenMsgILSupport" BO_ 2651930688 1;
BA_ "Type" BO_ 2651930688 11;
BA_ "CANFD_BRS" BO_ 2651930785 1;
BA_ "VFrameFormat" BO_ 2651930785 15;
BA_ "GenMsgILSupport" BO_ 2651930785 1;
BA_ "Type" BO_ 2651930785 11;
BA_ "CANFD_BRS" BO_ 2654339161 1;
BA_ "VFrameFormat" BO_ 2654339161 15;
BA_ "GenMsgCycleTime" BO_ 2654339161 1000;
BA_ "GenMsgILSupport" BO_ 2654339161 1;
BA_ "GenMsgSendType" BO_ 2654339161 0;
BA_ "Type" BO_ 2654339161 1;
BA_ "CANFD_BRS" BO_ 2654339160 1;
BA_ "VFrameFormat" BO_ 2654339160 15;
BA_ "GenMsgCycleTime" BO_ 2654339160 1000;
BA_ "GenMsgILSupport" BO_ 2654339160 1;
BA_ "GenMsgSendType" BO_ 2654339160 0;
BA_ "Type" BO_ 2654339160 1;
BA_ "GenSigTimeoutTime_SGW" SG_ 2564682142 N_PDU 0;
BA_ "GenSigTimeoutTime_RFHM" SG_ 2564682142 N_PDU 0;
BA_ "GenSigTimeoutTime_MPAD" SG_ 2564682142 N_PDU 0;
BA_ "GenSigTimeoutTime_IPC" SG_ 2564682142 N_PDU 0;
BA_ "GenSigTimeoutTime_GNMM" SG_ 2564682142 N_PDU 0;
BA_ "GenSigTimeoutTime_EVCU2" SG_ 2564682142 N_PDU 0;
BA_ "GenSigTimeoutTime_ESL" SG_ 2564682142 N_PDU 0;
BA_ "GenSigTimeoutTime_ECM" SG_ 2564682142 N_PDU 0;
BA_ "GenSigTimeoutTime_DTCM" SG_ 2564682142 N_PDU 0;
BA_ "GenSigTimeoutTime_DMSM" SG_ 2564682142 N_PDU 0;
BA_ "GenSigTimeoutTime_BSM" SG_ 2564682142 N_PDU 0;
BA_ "GenSigTimeoutTime_BCM" SG_ 2564682142 N_PDU 0;
BA_ "GenSigTimeoutTime_AGSM" SG_ 2564682142 N_PDU 0;
BA_ "GenSigTimeoutTime_ADCAM" SG_ 2564682142 N_PDU 0;
BA_ "GenSigTimeoutTime_SGW" SG_ 2564682398 N_PDU 0;
BA_ "GenSigTimeoutTime_RFHM" SG_ 2564682398 N_PDU 0;
BA_ "GenSigTimeoutTime_MPAD" SG_ 2564682398 N_PDU 0;
BA_ "GenSigTimeoutTime_IPC" SG_ 2564682398 N_PDU 0;
BA_ "GenSigTimeoutTime_GNMM" SG_ 2564682398 N_PDU 0;
BA_ "GenSigTimeoutTime_EVCU2" SG_ 2564682398 N_PDU 0;
BA_ "GenSigTimeoutTime_ESL" SG_ 2564682398 N_PDU 0;
BA_ "GenSigTimeoutTime_ECM" SG_ 2564682398 N_PDU 0;
BA_ "GenSigTimeoutTime_DTCM" SG_ 2564682398 N_PDU 0;
BA_ "GenSigTimeoutTime_DMSM" SG_ 2564682398 N_PDU 0;
BA_ "GenSigTimeoutTime_BSM" SG_ 2564682398 N_PDU 0;
BA_ "GenSigTimeoutTime_BCM" SG_ 2564682398 N_PDU 0;
BA_ "GenSigTimeoutTime_AGSM" SG_ 2564682398 N_PDU 0;
BA_ "GenSigTimeoutTime_ADCAM" SG_ 2564682398 N_PDU 0;
BA_ "GenSigTimeoutTime_SGW" SG_ 2564682306 N_PDU 0;
BA_ "GenSigTimeoutTime_RFHM" SG_ 2564682306 N_PDU 0;
BA_ "GenSigTimeoutTime_MPAD" SG_ 2564682306 N_PDU 0;
BA_ "GenSigTimeoutTime_IPC" SG_ 2564682306 N_PDU 0;
BA_ "GenSigTimeoutTime_GNMM" SG_ 2564682306 N_PDU 0;
BA_ "GenSigTimeoutTime_EVCU2" SG_ 2564682306 N_PDU 0;
BA_ "GenSigTimeoutTime_ESL" SG_ 2564682306 N_PDU 0;
BA_ "GenSigTimeoutTime_ECM" SG_ 2564682306 N_PDU 0;
BA_ "GenSigTimeoutTime_DTCM" SG_ 2564682306 N_PDU 0;
BA_ "GenSigTimeoutTime_DMSM" SG_ 2564682306 N_PDU 0;
BA_ "GenSigTimeoutTime_BSM" SG_ 2564682306 N_PDU 0;
BA_ "GenSigTimeoutTime_BCM" SG_ 2564682306 N_PDU 0;
BA_ "GenSigTimeoutTime_AGSM" SG_ 2564682306 N_PDU 0;
BA_ "GenSigTimeoutTime_ADCAM" SG_ 2564682306 N_PDU 0;
BA_ "GenSigTimeoutTime_SGW" SG_ 2564682216 N_PDU 0;
BA_ "GenSigTimeoutTime_RFHM" SG_ 2564682216 N_PDU 0;
BA_ "GenSigTimeoutTime_MPAD" SG_ 2564682216 N_PDU 0;
BA_ "GenSigTimeoutTime_IPC" SG_ 2564682216 N_PDU 0;
BA_ "GenSigTimeoutTime_GNMM" SG_ 2564682216 N_PDU 0;
BA_ "GenSigTimeoutTime_EVCU2" SG_ 2564682216 N_PDU 0;
BA_ "GenSigTimeoutTime_ESL" SG_ 2564682216 N_PDU 0;
BA_ "GenSigTimeoutTime_ECM" SG_ 2564682216 N_PDU 0;
BA_ "GenSigTimeoutTime_DTCM" SG_ 2564682216 N_PDU 0;
BA_ "GenSigTimeoutTime_DMSM" SG_ 2564682216 N_PDU 0;
BA_ "GenSigTimeoutTime_BSM" SG_ 2564682216 N_PDU 0;
BA_ "GenSigTimeoutTime_BCM" SG_ 2564682216 N_PDU 0;
BA_ "GenSigTimeoutTime_AGSM" SG_ 2564682216 N_PDU 0;
BA_ "GenSigTimeoutTime_ADCAM" SG_ 2564682216 N_PDU 0;
BA_ "GenSigTimeoutTime_SGW" SG_ 2564682472 N_PDU 0;
BA_ "GenSigTimeoutTime_RFHM" SG_ 2564682472 N_PDU 0;
BA_ "GenSigTimeoutTime_MPAD" SG_ 2564682472 N_PDU 0;
BA_ "GenSigTimeoutTime_IPC" SG_ 2564682472 N_PDU 0;
BA_ "GenSigTimeoutTime_GNMM" SG_ 2564682472 N_PDU 0;
BA_ "GenSigTimeoutTime_EVCU2" SG_ 2564682472 N_PDU 0;
BA_ "GenSigTimeoutTime_ESL" SG_ 2564682472 N_PDU 0;
BA_ "GenSigTimeoutTime_ECM" SG_ 2564682472 N_PDU 0;
BA_ "GenSigTimeoutTime_DTCM" SG_ 2564682472 N_PDU 0;
BA_ "GenSigTimeoutTime_DMSM" SG_ 2564682472 N_PDU 0;
BA_ "GenSigTimeoutTime_BSM" SG_ 2564682472 N_PDU 0;
BA_ "GenSigTimeoutTime_BCM" SG_ 2564682472 N_PDU 0;
BA_ "GenSigTimeoutTime_AGSM" SG_ 2564682472 N_PDU 0;
BA_ "GenSigTimeoutTime_ADCAM" SG_ 2564682472 N_PDU 0;
BA_ "GenSigTimeoutTime_SGW" SG_ 2564682279 N_PDU 0;
BA_ "GenSigTimeoutTime_RFHM" SG_ 2564682279 N_PDU 0;
BA_ "GenSigTimeoutTime_MPAD" SG_ 2564682279 N_PDU 0;
BA_ "GenSigTimeoutTime_IPC" SG_ 2564682279 N_PDU 0;
BA_ "GenSigTimeoutTime_GNMM" SG_ 2564682279 N_PDU 0;
BA_ "GenSigTimeoutTime_EVCU2" SG_ 2564682279 N_PDU 0;
BA_ "GenSigTimeoutTime_ESL" SG_ 2564682279 N_PDU 0;
BA_ "GenSigTimeoutTime_ECM" SG_ 2564682279 N_PDU 0;
BA_ "GenSigTimeoutTime_DTCM" SG_ 2564682279 N_PDU 0;
BA_ "GenSigTimeoutTime_DMSM" SG_ 2564682279 N_PDU 0;
BA_ "GenSigTimeoutTime_BSM" SG_ 2564682279 N_PDU 0;
BA_ "GenSigTimeoutTime_BCM" SG_ 2564682279 N_PDU 0;
BA_ "GenSigTimeoutTime_AGSM" SG_ 2564682279 N_PDU 0;
BA_ "GenSigTimeoutTime_ADCAM" SG_ 2564682279 N_PDU 0;
BA_ "GenSigTimeoutTime_SGW" SG_ 2564682023 N_PDU 0;
BA_ "GenSigTimeoutTime_RFHM" SG_ 2564682023 N_PDU 0;
BA_ "GenSigTimeoutTime_MPAD" SG_ 2564682023 N_PDU 0;
BA_ "GenSigTimeoutTime_IPC" SG_ 2564682023 N_PDU 0;
BA_ "GenSigTimeoutTime_GNMM" SG_ 2564682023 N_PDU 0;
BA_ "GenSigTimeoutTime_EVCU2" SG_ 2564682023 N_PDU 0;
BA_ "GenSigTimeoutTime_ESL" SG_ 2564682023 N_PDU 0;
BA_ "GenSigTimeoutTime_ECM" SG_ 2564682023 N_PDU 0;
BA_ "GenSigTimeoutTime_DTCM" SG_ 2564682023 N_PDU 0;
BA_ "GenSigTimeoutTime_DMSM" SG_ 2564682023 N_PDU 0;
BA_ "GenSigTimeoutTime_BSM" SG_ 2564682023 N_PDU 0;
BA_ "GenSigTimeoutTime_BCM" SG_ 2564682023 N_PDU 0;
BA_ "GenSigTimeoutTime_AGSM" SG_ 2564682023 N_PDU 0;
BA_ "GenSigTimeoutTime_ADCAM" SG_ 2564682023 N_PDU 0;
BA_ "GenSigTimeoutTime_SGW" SG_ 2564682050 N_PDU 0;
BA_ "GenSigTimeoutTime_RFHM" SG_ 2564682050 N_PDU 0;
BA_ "GenSigTimeoutTime_MPAD" SG_ 2564682050 N_PDU 0;
BA_ "GenSigTimeoutTime_IPC" SG_ 2564682050 N_PDU 0;
BA_ "GenSigTimeoutTime_GNMM" SG_ 2564682050 N_PDU 0;
BA_ "GenSigTimeoutTime_EVCU2" SG_ 2564682050 N_PDU 0;
BA_ "GenSigTimeoutTime_ESL" SG_ 2564682050 N_PDU 0;
BA_ "GenSigTimeoutTime_ECM" SG_ 2564682050 N_PDU 0;
BA_ "GenSigTimeoutTime_DTCM" SG_ 2564682050 N_PDU 0;
BA_ "GenSigTimeoutTime_DMSM" SG_ 2564682050 N_PDU 0;
BA_ "GenSigTimeoutTime_BSM" SG_ 2564682050 N_PDU 0;
BA_ "GenSigTimeoutTime_BCM" SG_ 2564682050 N_PDU 0;
BA_ "GenSigTimeoutTime_AGSM" SG_ 2564682050 N_PDU 0;
BA_ "GenSigTimeoutTime_ADCAM" SG_ 2564682050 N_PDU 0;
BA_ "GenSigTimeoutTime_SGW" SG_ 2564485534 N_PDU 0;
BA_ "GenSigTimeoutTime_RFHM" SG_ 2564485534 N_PDU 0;
BA_ "GenSigTimeoutTime_MPAD" SG_ 2564485534 N_PDU 0;
BA_ "GenSigTimeoutTime_IPC" SG_ 2564485534 N_PDU 0;
BA_ "GenSigTimeoutTime_GNMM" SG_ 2564485534 N_PDU 0;
BA_ "GenSigTimeoutTime_EVCU2" SG_ 2564485534 N_PDU 0;
BA_ "GenSigTimeoutTime_ESL" SG_ 2564485534 N_PDU 0;
BA_ "GenSigTimeoutTime_ECM" SG_ 2564485534 N_PDU 0;
BA_ "GenSigTimeoutTime_DTCM" SG_ 2564485534 N_PDU 0;
BA_ "GenSigTimeoutTime_DMSM" SG_ 2564485534 N_PDU 0;
BA_ "GenSigTimeoutTime_BSM" SG_ 2564485534 N_PDU 0;
BA_ "GenSigTimeoutTime_BCM" SG_ 2564485534 N_PDU 0;
BA_ "GenSigTimeoutTime_AGSM" SG_ 2564485534 N_PDU 0;
BA_ "GenSigTimeoutTime_ADCAM" SG_ 2564485534 N_PDU 0;
BA_ "GenSigTimeoutTime_SGW" SG_ 2564486632 N_PDU 0;
BA_ "GenSigTimeoutTime_RFHM" SG_ 2564486632 N_PDU 0;
BA_ "GenSigTimeoutTime_MPAD" SG_ 2564486632 N_PDU 0;
BA_ "GenSigTimeoutTime_IPC" SG_ 2564486632 N_PDU 0;
BA_ "GenSigTimeoutTime_GNMM" SG_ 2564486632 N_PDU 0;
BA_ "GenSigTimeoutTime_EVCU2" SG_ 2564486632 N_PDU 0;
BA_ "GenSigTimeoutTime_ESL" SG_ 2564486632 N_PDU 0;
BA_ "GenSigTimeoutTime_ECM" SG_ 2564486632 N_PDU 0;
BA_ "GenSigTimeoutTime_DTCM" SG_ 2564486632 N_PDU 0;
BA_ "GenSigTimeoutTime_DMSM" SG_ 2564486632 N_PDU 0;
BA_ "GenSigTimeoutTime_BSM" SG_ 2564486632 N_PDU 0;
BA_ "GenSigTimeoutTime_BCM" SG_ 2564486632 N_PDU 0;
BA_ "GenSigTimeoutTime_AGSM" SG_ 2564486632 N_PDU 0;
BA_ "GenSigTimeoutTime_ADCAM" SG_ 2564486632 N_PDU 0;
BA_ "GenSigTimeoutTime_SGW" SG_ 2564485790 N_PDU 0;
BA_ "GenSigTimeoutTime_RFHM" SG_ 2564485790 N_PDU 0;
BA_ "GenSigTimeoutTime_MPAD" SG_ 2564485790 N_PDU 0;
BA_ "GenSigTimeoutTime_IPC" SG_ 2564485790 N_PDU 0;
BA_ "GenSigTimeoutTime_GNMM" SG_ 2564485790 N_PDU 0;
BA_ "GenSigTimeoutTime_EVCU2" SG_ 2564485790 N_PDU 0;
BA_ "GenSigTimeoutTime_ESL" SG_ 2564485790 N_PDU 0;
BA_ "GenSigTimeoutTime_ECM" SG_ 2564485790 N_PDU 0;
BA_ "GenSigTimeoutTime_DTCM" SG_ 2564485790 N_PDU 0;
BA_ "GenSigTimeoutTime_DMSM" SG_ 2564485790 N_PDU 0;
BA_ "GenSigTimeoutTime_BSM" SG_ 2564485790 N_PDU 0;
BA_ "GenSigTimeoutTime_BCM" SG_ 2564485790 N_PDU 0;
BA_ "GenSigTimeoutTime_AGSM" SG_ 2564485790 N_PDU 0;
BA_ "GenSigTimeoutTime_ADCAM" SG_ 2564485790 N_PDU 0;
BA_ "GenSigTimeoutTime_SGW" SG_ 2564485864 N_PDU 0;
BA_ "GenSigTimeoutTime_RFHM" SG_ 2564485864 N_PDU 0;
BA_ "GenSigTimeoutTime_MPAD" SG_ 2564485864 N_PDU 0;
BA_ "GenSigTimeoutTime_IPC" SG_ 2564485864 N_PDU 0;
BA_ "GenSigTimeoutTime_SGW" SG_ 2564485608 N_PDU 0;
BA_ "GenSigTimeoutTime_RFHM" SG_ 2564485608 N_PDU 0;
BA_ "GenSigTimeoutTime_MPAD" SG_ 2564485608 N_PDU 0;
BA_ "GenSigTimeoutTime_IPC" SG_ 2564485608 N_PDU 0;
BA_ "GenSigTimeoutTime_GNMM" SG_ 2564485608 N_PDU 0;
BA_ "GenSigTimeoutTime_EVCU2" SG_ 2564485608 N_PDU 0;
BA_ "GenSigTimeoutTime_ESL" SG_ 2564485608 N_PDU 0;
BA_ "GenSigTimeoutTime_ECM" SG_ 2564485608 N_PDU 0;
BA_ "GenSigTimeoutTime_DTCM" SG_ 2564485608 N_PDU 0;
BA_ "GenSigTimeoutTime_DMSM" SG_ 2564485608 N_PDU 0;
BA_ "GenSigTimeoutTime_BSM" SG_ 2564485608 N_PDU 0;
BA_ "GenSigTimeoutTime_BCM" SG_ 2564485608 N_PDU 0;
BA_ "GenSigTimeoutTime_AGSM" SG_ 2564485608 N_PDU 0;
BA_ "GenSigTimeoutTime_ADCAM" SG_ 2564485608 N_PDU 0;
BA_ "GenSigTimeoutTime_SGW" SG_ 2564486439 N_PDU 0;
BA_ "GenSigTimeoutTime_RFHM" SG_ 2564486439 N_PDU 0;
BA_ "GenSigTimeoutTime_MPAD" SG_ 2564486439 N_PDU 0;
BA_ "GenSigTimeoutTime_IPC" SG_ 2564486439 N_PDU 0;
BA_ "GenSigTimeoutTime_GNMM" SG_ 2564486439 N_PDU 0;
BA_ "GenSigTimeoutTime_EVCU2" SG_ 2564486439 N_PDU 0;
BA_ "GenSigTimeoutTime_ESL" SG_ 2564486439 N_PDU 0;
BA_ "GenSigTimeoutTime_ECM" SG_ 2564486439 N_PDU 0;
BA_ "GenSigTimeoutTime_DTCM" SG_ 2564486439 N_PDU 0;
BA_ "GenSigTimeoutTime_DMSM" SG_ 2564486439 N_PDU 0;
BA_ "GenSigTimeoutTime_BSM" SG_ 2564486439 N_PDU 0;
BA_ "GenSigTimeoutTime_BCM" SG_ 2564486439 N_PDU 0;
BA_ "GenSigTimeoutTime_AGSM" SG_ 2564486439 N_PDU 0;
BA_ "GenSigTimeoutTime_ADCAM" SG_ 2564486439 N_PDU 0;
BA_ "GenSigTimeoutTime_SGW" SG_ 2564464369 N_PDU 0;
BA_ "GenSigTimeoutTime_RFHM" SG_ 2564464369 N_PDU 0;
BA_ "GenSigTimeoutTime_MPAD" SG_ 2564464369 N_PDU 0;
BA_ "GenSigTimeoutTime_IPC" SG_ 2564464369 N_PDU 0;
BA_ "GenSigTimeoutTime_GNMM" SG_ 2564464369 N_PDU 0;
BA_ "GenSigTimeoutTime_EVCU2" SG_ 2564464369 N_PDU 0;
BA_ "GenSigTimeoutTime_ESL" SG_ 2564464369 N_PDU 0;
BA_ "GenSigTimeoutTime_ECM" SG_ 2564464369 N_PDU 0;
BA_ "GenSigTimeoutTime_DTCM" SG_ 2564464369 N_PDU 0;
BA_ "GenSigTimeoutTime_DMSM" SG_ 2564464369 N_PDU 0;
BA_ "GenSigTimeoutTime_BSM" SG_ 2564464369 N_PDU 0;
BA_ "GenSigTimeoutTime_BCM" SG_ 2564464369 N_PDU 0;
BA_ "GenSigTimeoutTime_AGSM" SG_ 2564464369 N_PDU 0;
BA_ "GenSigTimeoutTime_ADCAM" SG_ 2564464369 N_PDU 0;
BA_ "GenSigTimeoutTime_SGW" SG_ 2564483313 N_PDU 0;
BA_ "GenSigTimeoutTime_RFHM" SG_ 2564483313 N_PDU 0;
BA_ "GenSigTimeoutTime_MPAD" SG_ 2564483313 N_PDU 0;
BA_ "GenSigTimeoutTime_IPC" SG_ 2564483313 N_PDU 0;
BA_ "GenSigTimeoutTime_GNMM" SG_ 2564483313 N_PDU 0;
BA_ "GenSigTimeoutTime_EVCU2" SG_ 2564483313 N_PDU 0;
BA_ "GenSigTimeoutTime_ESL" SG_ 2564483313 N_PDU 0;
BA_ "GenSigTimeoutTime_ECM" SG_ 2564483313 N_PDU 0;
BA_ "GenSigTimeoutTime_DTCM" SG_ 2564483313 N_PDU 0;
BA_ "GenSigTimeoutTime_DMSM" SG_ 2564483313 N_PDU 0;
BA_ "GenSigTimeoutTime_BSM" SG_ 2564483313 N_PDU 0;
BA_ "GenSigTimeoutTime_BCM" SG_ 2564483313 N_PDU 0;
BA_ "GenSigTimeoutTime_AGSM" SG_ 2564483313 N_PDU 0;
BA_ "GenSigTimeoutTime_ADCAM" SG_ 2564483313 N_PDU 0;
BA_ "GenSigTimeoutTime_SGW" SG_ 2564485415 N_PDU 0;
BA_ "GenSigTimeoutTime_RFHM" SG_ 2564485415 N_PDU 0;
BA_ "GenSigTimeoutTime_MPAD" SG_ 2564485415 N_PDU 0;
BA_ "GenSigTimeoutTime_IPC" SG_ 2564485415 N_PDU 0;
BA_ "GenSigTimeoutTime_GNMM" SG_ 2564485415 N_PDU 0;
BA_ "GenSigTimeoutTime_EVCU2" SG_ 2564485415 N_PDU 0;
BA_ "GenSigTimeoutTime_ESL" SG_ 2564485415 N_PDU 0;
BA_ "GenSigTimeoutTime_ECM" SG_ 2564485415 N_PDU 0;
BA_ "GenSigTimeoutTime_DTCM" SG_ 2564485415 N_PDU 0;
BA_ "GenSigTimeoutTime_DMSM" SG_ 2564485415 N_PDU 0;
BA_ "GenSigTimeoutTime_BSM" SG_ 2564485415 N_PDU 0;
BA_ "GenSigTimeoutTime_BCM" SG_ 2564485415 N_PDU 0;
BA_ "GenSigTimeoutTime_AGSM" SG_ 2564485415 N_PDU 0;
BA_ "GenSigTimeoutTime_ADCAM" SG_ 2564485415 N_PDU 0;
BA_ "GenSigTimeoutTime_SGW" SG_ 2564483317 N_PDU 0;
BA_ "GenSigTimeoutTime_RFHM" SG_ 2564483317 N_PDU 0;
BA_ "GenSigTimeoutTime_MPAD" SG_ 2564483317 N_PDU 0;
BA_ "GenSigTimeoutTime_IPC" SG_ 2564483317 N_PDU 0;
BA_ "GenSigTimeoutTime_GNMM" SG_ 2564483317 N_PDU 0;
BA_ "GenSigTimeoutTime_EVCU2" SG_ 2564483317 N_PDU 0;
BA_ "GenSigTimeoutTime_ESL" SG_ 2564483317 N_PDU 0;
BA_ "GenSigTimeoutTime_ECM" SG_ 2564483317 N_PDU 0;
BA_ "GenSigTimeoutTime_DTCM" SG_ 2564483317 N_PDU 0;
BA_ "GenSigTimeoutTime_DMSM" SG_ 2564483317 N_PDU 0;
BA_ "GenSigTimeoutTime_BSM" SG_ 2564483317 N_PDU 0;
BA_ "GenSigTimeoutTime_BCM" SG_ 2564483317 N_PDU 0;
BA_ "GenSigTimeoutTime_AGSM" SG_ 2564483317 N_PDU 0;
BA_ "GenSigTimeoutTime_ADCAM" SG_ 2564483317 N_PDU 0;
BA_ "GenSigTimeoutTime_SGW" SG_ 2564433909 N_PDU 0;
BA_ "GenSigTimeoutTime_RFHM" SG_ 2564433909 N_PDU 0;
BA_ "GenSigTimeoutTime_MPAD" SG_ 2564433909 N_PDU 0;
BA_ "GenSigTimeoutTime_IPC" SG_ 2564433909 N_PDU 0;
BA_ "GenSigTimeoutTime_GNMM" SG_ 2564433909 N_PDU 0;
BA_ "GenSigTimeoutTime_EVCU2" SG_ 2564433909 N_PDU 0;
BA_ "GenSigTimeoutTime_ESL" SG_ 2564433909 N_PDU 0;
BA_ "GenSigTimeoutTime_ECM" SG_ 2564433909 N_PDU 0;
BA_ "GenSigTimeoutTime_DTCM" SG_ 2564433909 N_PDU 0;
BA_ "GenSigTimeoutTime_DMSM" SG_ 2564433909 N_PDU 0;
BA_ "GenSigTimeoutTime_BSM" SG_ 2564433909 N_PDU 0;
BA_ "GenSigTimeoutTime_BCM" SG_ 2564433909 N_PDU 0;
BA_ "GenSigTimeoutTime_AGSM" SG_ 2564433909 N_PDU 0;
BA_ "GenSigTimeoutTime_ADCAM" SG_ 2564433909 N_PDU 0;
BA_ "GenSigTimeoutTime_SGW" SG_ 2564483314 N_PDU 0;
BA_ "GenSigTimeoutTime_RFHM" SG_ 2564483314 N_PDU 0;
BA_ "GenSigTimeoutTime_MPAD" SG_ 2564483314 N_PDU 0;
BA_ "GenSigTimeoutTime_IPC" SG_ 2564483314 N_PDU 0;
BA_ "GenSigTimeoutTime_GNMM" SG_ 2564483314 N_PDU 0;
BA_ "GenSigTimeoutTime_EVCU2" SG_ 2564483314 N_PDU 0;
BA_ "GenSigTimeoutTime_ESL" SG_ 2564483314 N_PDU 0;
BA_ "GenSigTimeoutTime_ECM" SG_ 2564483314 N_PDU 0;
BA_ "GenSigTimeoutTime_DTCM" SG_ 2564483314 N_PDU 0;
BA_ "GenSigTimeoutTime_DMSM" SG_ 2564483314 N_PDU 0;
BA_ "GenSigTimeoutTime_BSM" SG_ 2564483314 N_PDU 0;
BA_ "GenSigTimeoutTime_BCM" SG_ 2564483314 N_PDU 0;
BA_ "GenSigTimeoutTime_AGSM" SG_ 2564483314 N_PDU 0;
BA_ "GenSigTimeoutTime_ADCAM" SG_ 2564483314 N_PDU 0;
BA_ "GenSigTimeoutTime_SGW" SG_ 2564464370 N_PDU 0;
BA_ "GenSigTimeoutTime_RFHM" SG_ 2564464370 N_PDU 0;
BA_ "GenSigTimeoutTime_MPAD" SG_ 2564464370 N_PDU 0;
BA_ "GenSigTimeoutTime_IPC" SG_ 2564464370 N_PDU 0;
BA_ "GenSigTimeoutTime_GNMM" SG_ 2564464370 N_PDU 0;
BA_ "GenSigTimeoutTime_EVCU2" SG_ 2564464370 N_PDU 0;
BA_ "GenSigTimeoutTime_ESL" SG_ 2564464370 N_PDU 0;
BA_ "GenSigTimeoutTime_ECM" SG_ 2564464370 N_PDU 0;
BA_ "GenSigTimeoutTime_DTCM" SG_ 2564464370 N_PDU 0;
BA_ "GenSigTimeoutTime_DMSM" SG_ 2564464370 N_PDU 0;
BA_ "GenSigTimeoutTime_BSM" SG_ 2564464370 N_PDU 0;
BA_ "GenSigTimeoutTime_BCM" SG_ 2564464370 N_PDU 0;
BA_ "GenSigTimeoutTime_AGSM" SG_ 2564464370 N_PDU 0;
BA_ "GenSigTimeoutTime_ADCAM" SG_ 2564464370 N_PDU 0;
BA_ "GenSigTimeoutTime_SGW" SG_ 2564440818 N_PDU 0;
BA_ "GenSigTimeoutTime_RFHM" SG_ 2564440818 N_PDU 0;
BA_ "GenSigTimeoutTime_MPAD" SG_ 2564440818 N_PDU 0;
BA_ "GenSigTimeoutTime_IPC" SG_ 2564440818 N_PDU 0;
BA_ "GenSigTimeoutTime_GNMM" SG_ 2564440818 N_PDU 0;
BA_ "GenSigTimeoutTime_EVCU2" SG_ 2564440818 N_PDU 0;
BA_ "GenSigTimeoutTime_ESL" SG_ 2564440818 N_PDU 0;
BA_ "GenSigTimeoutTime_ECM" SG_ 2564440818 N_PDU 0;
BA_ "GenSigTimeoutTime_DTCM" SG_ 2564440818 N_PDU 0;
BA_ "GenSigTimeoutTime_DMSM" SG_ 2564440818 N_PDU 0;
BA_ "GenSigTimeoutTime_BSM" SG_ 2564440818 N_PDU 0;
BA_ "GenSigTimeoutTime_BCM" SG_ 2564440818 N_PDU 0;
BA_ "GenSigTimeoutTime_AGSM" SG_ 2564440818 N_PDU 0;
BA_ "GenSigTimeoutTime_ADCAM" SG_ 2564440818 N_PDU 0;
BA_ "GenSigTimeoutTime_SGW" SG_ 2654486689 CBV_bit3_NMCoordinatorBit 0;
BA_ "GenSigTimeoutTime_RFHM" SG_ 2654486689 CBV_bit3_NMCoordinatorBit 0;
BA_ "GenSigTimeoutTime_MPAD" SG_ 2654486689 CBV_bit3_NMCoordinatorBit 0;
BA_ "GenSigTimeoutTime_IPC" SG_ 2654486689 CBV_bit3_NMCoordinatorBit 0;
BA_ "GenSigTimeoutTime_GNMM" SG_ 2654486689 CBV_bit3_NMCoordinatorBit 0;
BA_ "GenSigTimeoutTime_EVCU2" SG_ 2654486689 CBV_bit3_NMCoordinatorBit 0;
BA_ "GenSigTimeoutTime_ESL" SG_ 2654486689 CBV_bit3_NMCoordinatorBit 0;
BA_ "GenSigTimeoutTime_ECM" SG_ 2654486689 CBV_bit3_NMCoordinatorBit 0;
BA_ "GenSigTimeoutTime_DTCM" SG_ 2654486689 CBV_bit3_NMCoordinatorBit 0;
BA_ "GenSigTimeoutTime_DMSM" SG_ 2654486689 CBV_bit3_NMCoordinatorBit 0;
BA_ "GenSigTimeoutTime_BSM" SG_ 2654486689 CBV_bit3_NMCoordinatorBit 0;
BA_ "GenSigTimeoutTime_BCM" SG_ 2654486689 CBV_bit3_NMCoordinatorBit 0;
BA_ "GenSigTimeoutTime_AGSM" SG_ 2654486689 CBV_bit3_NMCoordinatorBit 0;
BA_ "GenSigTimeoutTime_ADCAM" SG_ 2654486689 CBV_bit3_NMCoordinatorBit 0;
BA_ "GenSigTimeoutTime_SGW" SG_ 2654486689 CBV_bit0_RepeatMessageRequestBit 0;
BA_ "GenSigTimeoutTime_RFHM" SG_ 2654486689 CBV_bit0_RepeatMessageRequestBit 0;
BA_ "GenSigTimeoutTime_MPAD" SG_ 2654486689 CBV_bit0_RepeatMessageRequestBit 0;
BA_ "GenSigTimeoutTime_IPC" SG_ 2654486689 CBV_bit0_RepeatMessageRequestBit 0;
BA_ "GenSigTimeoutTime_GNMM" SG_ 2654486689 CBV_bit0_RepeatMessageRequestBit 0;
BA_ "GenSigTimeoutTime_EVCU2" SG_ 2654486689 CBV_bit0_RepeatMessageRequestBit 0;
BA_ "GenSigTimeoutTime_ESL" SG_ 2654486689 CBV_bit0_RepeatMessageRequestBit 0;
BA_ "GenSigTimeoutTime_ECM" SG_ 2654486689 CBV_bit0_RepeatMessageRequestBit 0;
BA_ "GenSigTimeoutTime_DTCM" SG_ 2654486689 CBV_bit0_RepeatMessageRequestBit 0;
BA_ "GenSigTimeoutTime_DMSM" SG_ 2654486689 CBV_bit0_RepeatMessageRequestBit 0;
BA_ "GenSigTimeoutTime_BSM" SG_ 2654486689 CBV_bit0_RepeatMessageRequestBit 0;
BA_ "GenSigTimeoutTime_BCM" SG_ 2654486689 CBV_bit0_RepeatMessageRequestBit 0;
BA_ "GenSigTimeoutTime_AGSM" SG_ 2654486689 CBV_bit0_RepeatMessageRequestBit 0;
BA_ "GenSigTimeoutTime_ADCAM" SG_ 2654486689 CBV_bit0_RepeatMessageRequestBit 0;
BA_ "GenSigTimeoutTime_SGW" SG_ 2654486689 CBV_bit6_PartialNtwInfBit 0;
BA_ "GenSigTimeoutTime_RFHM" SG_ 2654486689 CBV_bit6_PartialNtwInfBit 0;
BA_ "GenSigTimeoutTime_MPAD" SG_ 2654486689 CBV_bit6_PartialNtwInfBit 0;
BA_ "GenSigTimeoutTime_IPC" SG_ 2654486689 CBV_bit6_PartialNtwInfBit 0;
BA_ "GenSigTimeoutTime_GNMM" SG_ 2654486689 CBV_bit6_PartialNtwInfBit 0;
BA_ "GenSigTimeoutTime_EVCU2" SG_ 2654486689 CBV_bit6_PartialNtwInfBit 0;
BA_ "GenSigTimeoutTime_ESL" SG_ 2654486689 CBV_bit6_PartialNtwInfBit 0;
BA_ "GenSigTimeoutTime_ECM" SG_ 2654486689 CBV_bit6_PartialNtwInfBit 0;
BA_ "GenSigTimeoutTime_DTCM" SG_ 2654486689 CBV_bit6_PartialNtwInfBit 0;
BA_ "GenSigTimeoutTime_DMSM" SG_ 2654486689 CBV_bit6_PartialNtwInfBit 0;
BA_ "GenSigTimeoutTime_BSM" SG_ 2654486689 CBV_bit6_PartialNtwInfBit 0;
BA_ "GenSigTimeoutTime_BCM" SG_ 2654486689 CBV_bit6_PartialNtwInfBit 0;
BA_ "GenSigTimeoutTime_AGSM" SG_ 2654486689 CBV_bit6_PartialNtwInfBit 0;
BA_ "GenSigTimeoutTime_ADCAM" SG_ 2654486689 CBV_bit6_PartialNtwInfBit 0;
BA_ "GenSigTimeoutTime_SGW" SG_ 2654486689 CBV_bit4_ActiveWakeupBit 0;
BA_ "GenSigTimeoutTime_RFHM" SG_ 2654486689 CBV_bit4_ActiveWakeupBit 0;
BA_ "GenSigTimeoutTime_MPAD" SG_ 2654486689 CBV_bit4_ActiveWakeupBit 0;
BA_ "GenSigTimeoutTime_IPC" SG_ 2654486689 CBV_bit4_ActiveWakeupBit 0;
BA_ "GenSigTimeoutTime_GNMM" SG_ 2654486689 CBV_bit4_ActiveWakeupBit 0;
BA_ "GenSigTimeoutTime_EVCU2" SG_ 2654486689 CBV_bit4_ActiveWakeupBit 0;
BA_ "GenSigTimeoutTime_ESL" SG_ 2654486689 CBV_bit4_ActiveWakeupBit 0;
BA_ "GenSigTimeoutTime_ECM" SG_ 2654486689 CBV_bit4_ActiveWakeupBit 0;
BA_ "GenSigTimeoutTime_DTCM" SG_ 2654486689 CBV_bit4_ActiveWakeupBit 0;
BA_ "GenSigTimeoutTime_DMSM" SG_ 2654486689 CBV_bit4_ActiveWakeupBit 0;
BA_ "GenSigTimeoutTime_BSM" SG_ 2654486689 CBV_bit4_ActiveWakeupBit 0;
BA_ "GenSigTimeoutTime_BCM" SG_ 2654486689 CBV_bit4_ActiveWakeupBit 0;
BA_ "GenSigTimeoutTime_AGSM" SG_ 2654486689 CBV_bit4_ActiveWakeupBit 0;
BA_ "GenSigTimeoutTime_ADCAM" SG_ 2654486689 CBV_bit4_ActiveWakeupBit 0;
BA_ "GenSigTimeoutTime_SGW" SG_ 2654486689 SourceNodeIdentifier 0;
BA_ "GenSigTimeoutTime_RFHM" SG_ 2654486689 SourceNodeIdentifier 0;
BA_ "GenSigTimeoutTime_MPAD" SG_ 2654486689 SourceNodeIdentifier 0;
BA_ "GenSigTimeoutTime_IPC" SG_ 2654486689 SourceNodeIdentifier 0;
BA_ "GenSigTimeoutTime_GNMM" SG_ 2654486689 SourceNodeIdentifier 0;
BA_ "GenSigTimeoutTime_EVCU2" SG_ 2654486689 SourceNodeIdentifier 0;
BA_ "GenSigTimeoutTime_ESL" SG_ 2654486689 SourceNodeIdentifier 0;
BA_ "GenSigTimeoutTime_ECM" SG_ 2654486689 SourceNodeIdentifier 0;
BA_ "GenSigTimeoutTime_DTCM" SG_ 2654486689 SourceNodeIdentifier 0;
BA_ "GenSigTimeoutTime_DMSM" SG_ 2654486689 SourceNodeIdentifier 0;
BA_ "GenSigTimeoutTime_BSM" SG_ 2654486689 SourceNodeIdentifier 0;
BA_ "GenSigTimeoutTime_BCM" SG_ 2654486689 SourceNodeIdentifier 0;
BA_ "GenSigTimeoutTime_AGSM" SG_ 2654486689 SourceNodeIdentifier 0;
BA_ "GenSigTimeoutTime_ADCAM" SG_ 2654486689 SourceNodeIdentifier 0;
BA_ "GenSigTimeoutTime_SGW" SG_ 2654486689 CBV_bit7 0;
BA_ "GenSigTimeoutTime_RFHM" SG_ 2654486689 CBV_bit7 0;
BA_ "GenSigTimeoutTime_MPAD" SG_ 2654486689 CBV_bit7 0;
BA_ "GenSigTimeoutTime_IPC" SG_ 2654486689 CBV_bit7 0;
BA_ "GenSigTimeoutTime_GNMM" SG_ 2654486689 CBV_bit7 0;
BA_ "GenSigTimeoutTime_EVCU2" SG_ 2654486689 CBV_bit7 0;
BA_ "GenSigTimeoutTime_ESL" SG_ 2654486689 CBV_bit7 0;
BA_ "GenSigTimeoutTime_ECM" SG_ 2654486689 CBV_bit7 0;
BA_ "GenSigTimeoutTime_DTCM" SG_ 2654486689 CBV_bit7 0;
BA_ "GenSigTimeoutTime_DMSM" SG_ 2654486689 CBV_bit7 0;
BA_ "GenSigTimeoutTime_BSM" SG_ 2654486689 CBV_bit7 0;
BA_ "GenSigTimeoutTime_BCM" SG_ 2654486689 CBV_bit7 0;
BA_ "GenSigTimeoutTime_AGSM" SG_ 2654486689 CBV_bit7 0;
BA_ "GenSigTimeoutTime_ADCAM" SG_ 2654486689 CBV_bit7 0;
BA_ "GenSigTimeoutTime_SGW" SG_ 2654486689 CBV_bit5 0;
BA_ "GenSigTimeoutTime_RFHM" SG_ 2654486689 CBV_bit5 0;
BA_ "GenSigTimeoutTime_MPAD" SG_ 2654486689 CBV_bit5 0;
BA_ "GenSigTimeoutTime_IPC" SG_ 2654486689 CBV_bit5 0;
BA_ "GenSigTimeoutTime_GNMM" SG_ 2654486689 CBV_bit5 0;
BA_ "GenSigTimeoutTime_EVCU2" SG_ 2654486689 CBV_bit5 0;
BA_ "GenSigTimeoutTime_ESL" SG_ 2654486689 CBV_bit5 0;
BA_ "GenSigTimeoutTime_ECM" SG_ 2654486689 CBV_bit5 0;
BA_ "GenSigTimeoutTime_DTCM" SG_ 2654486689 CBV_bit5 0;
BA_ "GenSigTimeoutTime_DMSM" SG_ 2654486689 CBV_bit5 0;
BA_ "GenSigTimeoutTime_BSM" SG_ 2654486689 CBV_bit5 0;
BA_ "GenSigTimeoutTime_BCM" SG_ 2654486689 CBV_bit5 0;
BA_ "GenSigTimeoutTime_AGSM" SG_ 2654486689 CBV_bit5 0;
BA_ "GenSigTimeoutTime_ADCAM" SG_ 2654486689 CBV_bit5 0;
BA_ "GenSigTimeoutTime_SGW" SG_ 2654486689 CBV_bit1 0;
BA_ "GenSigTimeoutTime_RFHM" SG_ 2654486689 CBV_bit1 0;
BA_ "GenSigTimeoutTime_MPAD" SG_ 2654486689 CBV_bit1 0;
BA_ "GenSigTimeoutTime_IPC" SG_ 2654486689 CBV_bit1 0;
BA_ "GenSigTimeoutTime_GNMM" SG_ 2654486689 CBV_bit1 0;
BA_ "GenSigTimeoutTime_EVCU2" SG_ 2654486689 CBV_bit1 0;
BA_ "GenSigTimeoutTime_ESL" SG_ 2654486689 CBV_bit1 0;
BA_ "GenSigTimeoutTime_ECM" SG_ 2654486689 CBV_bit1 0;
BA_ "GenSigTimeoutTime_DTCM" SG_ 2654486689 CBV_bit1 0;
BA_ "GenSigTimeoutTime_DMSM" SG_ 2654486689 CBV_bit1 0;
BA_ "GenSigTimeoutTime_BSM" SG_ 2654486689 CBV_bit1 0;
BA_ "GenSigTimeoutTime_BCM" SG_ 2654486689 CBV_bit1 0;
BA_ "GenSigTimeoutTime_AGSM" SG_ 2654486689 CBV_bit1 0;
BA_ "GenSigTimeoutTime_ADCAM" SG_ 2654486689 CBV_bit1 0;
BA_ "GenSigTimeoutTime_SGW" SG_ 2654486689 CBV_bit2 0;
BA_ "GenSigTimeoutTime_RFHM" SG_ 2654486689 CBV_bit2 0;
BA_ "GenSigTimeoutTime_MPAD" SG_ 2654486689 CBV_bit2 0;
BA_ "GenSigTimeoutTime_IPC" SG_ 2654486689 CBV_bit2 0;
BA_ "GenSigTimeoutTime_GNMM" SG_ 2654486689 CBV_bit2 0;
BA_ "GenSigTimeoutTime_EVCU2" SG_ 2654486689 CBV_bit2 0;
BA_ "GenSigTimeoutTime_ESL" SG_ 2654486689 CBV_bit2 0;
BA_ "GenSigTimeoutTime_ECM" SG_ 2654486689 CBV_bit2 0;
BA_ "GenSigTimeoutTime_DTCM" SG_ 2654486689 CBV_bit2 0;
BA_ "GenSigTimeoutTime_DMSM" SG_ 2654486689 CBV_bit2 0;
BA_ "GenSigTimeoutTime_BSM" SG_ 2654486689 CBV_bit2 0;
BA_ "GenSigTimeoutTime_BCM" SG_ 2654486689 CBV_bit2 0;
BA_ "GenSigTimeoutTime_AGSM" SG_ 2654486689 CBV_bit2 0;
BA_ "GenSigTimeoutTime_ADCAM" SG_ 2654486689 CBV_bit2 0;
BA_ "GenSigTimeoutTime_SGW" SG_ 2564440817 N_PDU 0;
BA_ "GenSigTimeoutTime_RFHM" SG_ 2564440817 N_PDU 0;
BA_ "GenSigTimeoutTime_MPAD" SG_ 2564440817 N_PDU 0;
BA_ "GenSigTimeoutTime_IPC" SG_ 2564440817 N_PDU 0;
BA_ "GenSigTimeoutTime_GNMM" SG_ 2564440817 N_PDU 0;
BA_ "GenSigTimeoutTime_EVCU2" SG_ 2564440817 N_PDU 0;
BA_ "GenSigTimeoutTime_ESL" SG_ 2564440817 N_PDU 0;
BA_ "GenSigTimeoutTime_ECM" SG_ 2564440817 N_PDU 0;
BA_ "GenSigTimeoutTime_DTCM" SG_ 2564440817 N_PDU 0;
BA_ "GenSigTimeoutTime_DMSM" SG_ 2564440817 N_PDU 0;
BA_ "GenSigTimeoutTime_BSM" SG_ 2564440817 N_PDU 0;
BA_ "GenSigTimeoutTime_BCM" SG_ 2564440817 N_PDU 0;
BA_ "GenSigTimeoutTime_AGSM" SG_ 2564440817 N_PDU 0;
BA_ "GenSigTimeoutTime_ADCAM" SG_ 2564440817 N_PDU 0;
BA_ "GenSigTimeoutTime_SGW" SG_ 2564433905 N_PDU 0;
BA_ "GenSigTimeoutTime_RFHM" SG_ 2564433905 N_PDU 0;
BA_ "GenSigTimeoutTime_MPAD" SG_ 2564433905 N_PDU 0;
BA_ "GenSigTimeoutTime_IPC" SG_ 2564433905 N_PDU 0;
BA_ "GenSigTimeoutTime_GNMM" SG_ 2564433905 N_PDU 0;
BA_ "GenSigTimeoutTime_EVCU2" SG_ 2564433905 N_PDU 0;
BA_ "GenSigTimeoutTime_ESL" SG_ 2564433905 N_PDU 0;
BA_ "GenSigTimeoutTime_ECM" SG_ 2564433905 N_PDU 0;
BA_ "GenSigTimeoutTime_DTCM" SG_ 2564433905 N_PDU 0;
BA_ "GenSigTimeoutTime_DMSM" SG_ 2564433905 N_PDU 0;
BA_ "GenSigTimeoutTime_BSM" SG_ 2564433905 N_PDU 0;
BA_ "GenSigTimeoutTime_BCM" SG_ 2564433905 N_PDU 0;
BA_ "GenSigTimeoutTime_AGSM" SG_ 2564433905 N_PDU 0;
BA_ "GenSigTimeoutTime_ADCAM" SG_ 2564433905 N_PDU 0;
BA_ "GenSigTimeoutTime_SGW" SG_ 2564433906 N_PDU 0;
BA_ "GenSigTimeoutTime_RFHM" SG_ 2564433906 N_PDU 0;
BA_ "GenSigTimeoutTime_MPAD" SG_ 2564433906 N_PDU 0;
BA_ "GenSigTimeoutTime_IPC" SG_ 2564433906 N_PDU 0;
BA_ "GenSigTimeoutTime_GNMM" SG_ 2564433906 N_PDU 0;
BA_ "GenSigTimeoutTime_EVCU2" SG_ 2564433906 N_PDU 0;
BA_ "GenSigTimeoutTime_ESL" SG_ 2564433906 N_PDU 0;
BA_ "GenSigTimeoutTime_ECM" SG_ 2564433906 N_PDU 0;
BA_ "GenSigTimeoutTime_DTCM" SG_ 2564433906 N_PDU 0;
BA_ "GenSigTimeoutTime_DMSM" SG_ 2564433906 N_PDU 0;
BA_ "GenSigTimeoutTime_BSM" SG_ 2564433906 N_PDU 0;
BA_ "GenSigTimeoutTime_BCM" SG_ 2564433906 N_PDU 0;
BA_ "GenSigTimeoutTime_AGSM" SG_ 2564433906 N_PDU 0;
BA_ "GenSigTimeoutTime_ADCAM" SG_ 2564433906 N_PDU 0;
BA_ "GenSigTimeoutTime_RFHM" SG_ 2654339233 PreviousCanNMState_FD03_ADCAM 0;
BA_ "GenSigTimeoutTime_MPAD" SG_ 2654339233 PreviousCanNMState_FD03_ADCAM 0;
BA_ "GenSigTimeoutTime_IPC" SG_ 2654339233 PreviousCanNMState_FD03_ADCAM 0;
BA_ "GenSigTimeoutTime_GNMM" SG_ 2654339233 PreviousCanNMState_FD03_ADCAM 0;
BA_ "GenSigTimeoutTime_EVCU2" SG_ 2654339233 PreviousCanNMState_FD03_ADCAM 0;
BA_ "GenSigTimeoutTime_ESL" SG_ 2654339233 PreviousCanNMState_FD03_ADCAM 0;
BA_ "GenSigTimeoutTime_ECM" SG_ 2654339233 PreviousCanNMState_FD03_ADCAM 0;
BA_ "GenSigTimeoutTime_DTCM" SG_ 2654339233 PreviousCanNMState_FD03_ADCAM 0;
BA_ "GenSigTimeoutTime_DMSM" SG_ 2654339233 PreviousCanNMState_FD03_ADCAM 0;
BA_ "GenSigTimeoutTime_BSM" SG_ 2654339233 PreviousCanNMState_FD03_ADCAM 0;
BA_ "GenSigTimeoutTime_BCM" SG_ 2654339233 PreviousCanNMState_FD03_ADCAM 0;
BA_ "GenSigTimeoutTime_AGSM" SG_ 2654339233 PreviousCanNMState_FD03_ADCAM 0;
BA_ "GenSigTimeoutTime_ADCAM" SG_ 2654339233 PreviousCanNMState_FD03_ADCAM 0;
BA_ "GenSigTimeoutTime_RFHM" SG_ 2654339233 StayActiveSource_FD03_ADCAM 0;
BA_ "GenSigTimeoutTime_MPAD" SG_ 2654339233 StayActiveSource_FD03_ADCAM 0;
BA_ "GenSigTimeoutTime_IPC" SG_ 2654339233 StayActiveSource_FD03_ADCAM 0;
BA_ "GenSigTimeoutTime_GNMM" SG_ 2654339233 StayActiveSource_FD03_ADCAM 0;
BA_ "GenSigTimeoutTime_EVCU2" SG_ 2654339233 StayActiveSource_FD03_ADCAM 0;
BA_ "GenSigTimeoutTime_ESL" SG_ 2654339233 StayActiveSource_FD03_ADCAM 0;
BA_ "GenSigTimeoutTime_ECM" SG_ 2654339233 StayActiveSource_FD03_ADCAM 0;
BA_ "GenSigTimeoutTime_DTCM" SG_ 2654339233 StayActiveSource_FD03_ADCAM 0;
BA_ "GenSigTimeoutTime_DMSM" SG_ 2654339233 StayActiveSource_FD03_ADCAM 0;
BA_ "GenSigTimeoutTime_BSM" SG_ 2654339233 StayActiveSource_FD03_ADCAM 0;
BA_ "GenSigTimeoutTime_BCM" SG_ 2654339233 StayActiveSource_FD03_ADCAM 0;
BA_ "GenSigTimeoutTime_AGSM" SG_ 2654339233 StayActiveSource_FD03_ADCAM 0;
BA_ "GenSigTimeoutTime_ADCAM" SG_ 2654339233 StayActiveSource_FD03_ADCAM 0;
BA_ "GenSigTimeoutTime_RFHM" SG_ 2654339233 GenericFailSts_FD03_ADCAM 0;
BA_ "GenSigTimeoutTime_MPAD" SG_ 2654339233 GenericFailSts_FD03_ADCAM 0;
BA_ "GenSigTimeoutTime_IPC" SG_ 2654339233 GenericFailSts_FD03_ADCAM 0;
BA_ "GenSigTimeoutTime_GNMM" SG_ 2654339233 GenericFailSts_FD03_ADCAM 0;
BA_ "GenSigTimeoutTime_EVCU2" SG_ 2654339233 GenericFailSts_FD03_ADCAM 0;
BA_ "GenSigTimeoutTime_ESL" SG_ 2654339233 GenericFailSts_FD03_ADCAM 0;
BA_ "GenSigTimeoutTime_ECM" SG_ 2654339233 GenericFailSts_FD03_ADCAM 0;
BA_ "GenSigTimeoutTime_DTCM" SG_ 2654339233 GenericFailSts_FD03_ADCAM 0;
BA_ "GenSigTimeoutTime_DMSM" SG_ 2654339233 GenericFailSts_FD03_ADCAM 0;
BA_ "GenSigTimeoutTime_BSM" SG_ 2654339233 GenericFailSts_FD03_ADCAM 0;
BA_ "GenSigTimeoutTime_AGSM" SG_ 2654339233 GenericFailSts_FD03_ADCAM 0;
BA_ "GenSigTimeoutTime_ADCAM" SG_ 2654339233 GenericFailSts_FD03_ADCAM 0;
BA_ "GenSigTimeoutTime_RFHM" SG_ 2654339233 EOL_FD03_ADCAM 0;
BA_ "GenSigTimeoutTime_MPAD" SG_ 2654339233 EOL_FD03_ADCAM 0;
BA_ "GenSigTimeoutTime_IPC" SG_ 2654339233 EOL_FD03_ADCAM 0;
BA_ "GenSigTimeoutTime_GNMM" SG_ 2654339233 EOL_FD03_ADCAM 0;
BA_ "GenSigTimeoutTime_EVCU2" SG_ 2654339233 EOL_FD03_ADCAM 0;
BA_ "GenSigTimeoutTime_ESL" SG_ 2654339233 EOL_FD03_ADCAM 0;
BA_ "GenSigTimeoutTime_ECM" SG_ 2654339233 EOL_FD03_ADCAM 0;
BA_ "GenSigTimeoutTime_DTCM" SG_ 2654339233 EOL_FD03_ADCAM 0;
BA_ "GenSigTimeoutTime_DMSM" SG_ 2654339233 EOL_FD03_ADCAM 0;
BA_ "GenSigTimeoutTime_BSM" SG_ 2654339233 EOL_FD03_ADCAM 0;
BA_ "GenSigTimeoutTime_AGSM" SG_ 2654339233 EOL_FD03_ADCAM 0;
BA_ "GenSigTimeoutTime_ADCAM" SG_ 2654339233 EOL_FD03_ADCAM 0;
BA_ "GenSigTimeoutTime_RFHM" SG_ 2654339233 WakeupSource_FD03_ADCAM 0;
BA_ "GenSigTimeoutTime_MPAD" SG_ 2654339233 WakeupSource_FD03_ADCAM 0;
BA_ "GenSigTimeoutTime_IPC" SG_ 2654339233 WakeupSource_FD03_ADCAM 0;
BA_ "GenSigTimeoutTime_GNMM" SG_ 2654339233 WakeupSource_FD03_ADCAM 0;
BA_ "GenSigTimeoutTime_EVCU2" SG_ 2654339233 WakeupSource_FD03_ADCAM 0;
BA_ "GenSigTimeoutTime_ESL" SG_ 2654339233 WakeupSource_FD03_ADCAM 0;
BA_ "GenSigTimeoutTime_ECM" SG_ 2654339233 WakeupSource_FD03_ADCAM 0;
BA_ "GenSigTimeoutTime_DTCM" SG_ 2654339233 WakeupSource_FD03_ADCAM 0;
BA_ "GenSigTimeoutTime_DMSM" SG_ 2654339233 WakeupSource_FD03_ADCAM 0;
BA_ "GenSigTimeoutTime_BSM" SG_ 2654339233 WakeupSource_FD03_ADCAM 0;
BA_ "GenSigTimeoutTime_BCM" SG_ 2654339233 WakeupSource_FD03_ADCAM 0;
BA_ "GenSigTimeoutTime_AGSM" SG_ 2654339233 WakeupSource_FD03_ADCAM 0;
BA_ "GenSigTimeoutTime_ADCAM" SG_ 2654339233 WakeupSource_FD03_ADCAM 0;
BA_ "GenSigTimeoutTime_SGW" SG_ 2564485698 N_PDU 0;
BA_ "GenSigTimeoutTime_RFHM" SG_ 2564485698 N_PDU 0;
BA_ "GenSigTimeoutTime_MPAD" SG_ 2564485698 N_PDU 0;
BA_ "GenSigTimeoutTime_IPC" SG_ 2564485698 N_PDU 0;
BA_ "GenSigTimeoutTime_GNMM" SG_ 2564485698 N_PDU 0;
BA_ "GenSigTimeoutTime_EVCU2" SG_ 2564485698 N_PDU 0;
BA_ "GenSigTimeoutTime_ESL" SG_ 2564485698 N_PDU 0;
BA_ "GenSigTimeoutTime_ECM" SG_ 2564485698 N_PDU 0;
BA_ "GenSigTimeoutTime_DTCM" SG_ 2564485698 N_PDU 0;
BA_ "GenSigTimeoutTime_DMSM" SG_ 2564485698 N_PDU 0;
BA_ "GenSigTimeoutTime_BSM" SG_ 2564485698 N_PDU 0;
BA_ "GenSigTimeoutTime_BCM" SG_ 2564485698 N_PDU 0;
BA_ "GenSigTimeoutTime_AGSM" SG_ 2564485698 N_PDU 0;
BA_ "GenSigTimeoutTime_ADCAM" SG_ 2564485698 N_PDU 0;
BA_ "GenSigTimeoutTime_GNMM" SG_ 2564485864 N_PDU 0;
BA_ "GenSigTimeoutTime_EVCU2" SG_ 2564485864 N_PDU 0;
BA_ "GenSigTimeoutTime_ESL" SG_ 2564485864 N_PDU 0;
BA_ "GenSigTimeoutTime_ECM" SG_ 2564485864 N_PDU 0;
BA_ "GenSigTimeoutTime_DTCM" SG_ 2564485864 N_PDU 0;
BA_ "GenSigTimeoutTime_DMSM" SG_ 2564485864 N_PDU 0;
BA_ "GenSigTimeoutTime_BSM" SG_ 2564485864 N_PDU 0;
BA_ "GenSigTimeoutTime_BCM" SG_ 2564485864 N_PDU 0;
BA_ "GenSigTimeoutTime_AGSM" SG_ 2564485864 N_PDU 0;
BA_ "GenSigTimeoutTime_ADCAM" SG_ 2564485864 N_PDU 0;
BA_ "GenSigTimeoutTime_SGW" SG_ 2564485671 N_PDU 0;
BA_ "GenSigTimeoutTime_RFHM" SG_ 2564485671 N_PDU 0;
BA_ "GenSigTimeoutTime_MPAD" SG_ 2564485671 N_PDU 0;
BA_ "GenSigTimeoutTime_IPC" SG_ 2564485671 N_PDU 0;
BA_ "GenSigTimeoutTime_GNMM" SG_ 2564485671 N_PDU 0;
BA_ "GenSigTimeoutTime_EVCU2" SG_ 2564485671 N_PDU 0;
BA_ "GenSigTimeoutTime_ESL" SG_ 2564485671 N_PDU 0;
BA_ "GenSigTimeoutTime_ECM" SG_ 2564485671 N_PDU 0;
BA_ "GenSigTimeoutTime_DTCM" SG_ 2564485671 N_PDU 0;
BA_ "GenSigTimeoutTime_DMSM" SG_ 2564485671 N_PDU 0;
BA_ "GenSigTimeoutTime_BSM" SG_ 2564485671 N_PDU 0;
BA_ "GenSigTimeoutTime_BCM" SG_ 2564485671 N_PDU 0;
BA_ "GenSigTimeoutTime_AGSM" SG_ 2564485671 N_PDU 0;
BA_ "GenSigTimeoutTime_ADCAM" SG_ 2564485671 N_PDU 0;
BA_ "GenSigTimeoutTime_SGW" SG_ 2564485442 N_PDU 0;
BA_ "GenSigTimeoutTime_RFHM" SG_ 2564485442 N_PDU 0;
BA_ "GenSigTimeoutTime_MPAD" SG_ 2564485442 N_PDU 0;
BA_ "GenSigTimeoutTime_IPC" SG_ 2564485442 N_PDU 0;
BA_ "GenSigTimeoutTime_GNMM" SG_ 2564485442 N_PDU 0;
BA_ "GenSigTimeoutTime_EVCU2" SG_ 2564485442 N_PDU 0;
BA_ "GenSigTimeoutTime_ESL" SG_ 2564485442 N_PDU 0;
BA_ "GenSigTimeoutTime_ECM" SG_ 2564485442 N_PDU 0;
BA_ "GenSigTimeoutTime_DTCM" SG_ 2564485442 N_PDU 0;
BA_ "GenSigTimeoutTime_DMSM" SG_ 2564485442 N_PDU 0;
BA_ "GenSigTimeoutTime_BSM" SG_ 2564485442 N_PDU 0;
BA_ "GenSigTimeoutTime_BCM" SG_ 2564485442 N_PDU 0;
BA_ "GenSigTimeoutTime_AGSM" SG_ 2564485442 N_PDU 0;
BA_ "GenSigTimeoutTime_ADCAM" SG_ 2564485442 N_PDU 0;
BA_ "GenSigTimeoutTime_ADCAM" SG_ 2654339161 WakeupSource_FD05_MCPB 0;
BA_ "GenSigTimeoutTime_RFHM" SG_ 2654339161 StayActiveSource_FD16_MCPB 0;
BA_ "GenSigTimeoutTime_MPAD" SG_ 2654339161 StayActiveSource_FD16_MCPB 0;
BA_ "GenSigTimeoutTime_IPC" SG_ 2654339161 StayActiveSource_FD16_MCPB 0;
BA_ "GenSigTimeoutTime_GNMM" SG_ 2654339161 StayActiveSource_FD16_MCPB 0;
BA_ "GenSigTimeoutTime_EVCU2" SG_ 2654339161 StayActiveSource_FD16_MCPB 0;
BA_ "GenSigTimeoutTime_ESL" SG_ 2654339161 StayActiveSource_FD16_MCPB 0;
BA_ "GenSigTimeoutTime_ECM" SG_ 2654339161 StayActiveSource_FD16_MCPB 0;
BA_ "GenSigTimeoutTime_DTCM" SG_ 2654339161 StayActiveSource_FD16_MCPB 0;
BA_ "GenSigTimeoutTime_DMSM" SG_ 2654339161 StayActiveSource_FD16_MCPB 0;
BA_ "GenSigTimeoutTime_BSM" SG_ 2654339161 StayActiveSource_FD16_MCPB 0;
BA_ "GenSigTimeoutTime_BCM" SG_ 2654339161 StayActiveSource_FD16_MCPB 0;
BA_ "GenSigTimeoutTime_AGSM" SG_ 2654339161 StayActiveSource_FD16_MCPB 0;
BA_ "GenSigTimeoutTime_ADCAM" SG_ 2654339161 StayActiveSource_FD16_MCPB 0;
BA_ "GenSigTimeoutTime_RFHM" SG_ 2654339161 StayActiveSource_FD05_MCPB 0;
BA_ "GenSigTimeoutTime_MPAD" SG_ 2654339161 StayActiveSource_FD05_MCPB 0;
BA_ "GenSigTimeoutTime_IPC" SG_ 2654339161 StayActiveSource_FD05_MCPB 0;
BA_ "GenSigTimeoutTime_GNMM" SG_ 2654339161 StayActiveSource_FD05_MCPB 0;
BA_ "GenSigTimeoutTime_EVCU2" SG_ 2654339161 StayActiveSource_FD05_MCPB 0;
BA_ "GenSigTimeoutTime_ESL" SG_ 2654339161 StayActiveSource_FD05_MCPB 0;
BA_ "GenSigTimeoutTime_ECM" SG_ 2654339161 StayActiveSource_FD05_MCPB 0;
BA_ "GenSigTimeoutTime_DTCM" SG_ 2654339161 StayActiveSource_FD05_MCPB 0;
BA_ "GenSigTimeoutTime_DMSM" SG_ 2654339161 StayActiveSource_FD05_MCPB 0;
BA_ "GenSigTimeoutTime_BSM" SG_ 2654339161 StayActiveSource_FD05_MCPB 0;
BA_ "GenSigTimeoutTime_BCM" SG_ 2654339161 StayActiveSource_FD05_MCPB 0;
BA_ "GenSigTimeoutTime_AGSM" SG_ 2654339161 StayActiveSource_FD05_MCPB 0;
BA_ "GenSigTimeoutTime_ADCAM" SG_ 2654339161 StayActiveSource_FD05_MCPB 0;
BA_ "GenSigTimeoutTime_RFHM" SG_ 2654339161 PreviousCanNMState_FD16_MCPB 0;
BA_ "GenSigTimeoutTime_MPAD" SG_ 2654339161 PreviousCanNMState_FD16_MCPB 0;
BA_ "GenSigTimeoutTime_IPC" SG_ 2654339161 PreviousCanNMState_FD16_MCPB 0;
BA_ "GenSigTimeoutTime_GNMM" SG_ 2654339161 PreviousCanNMState_FD16_MCPB 0;
BA_ "GenSigTimeoutTime_EVCU2" SG_ 2654339161 PreviousCanNMState_FD16_MCPB 0;
BA_ "GenSigTimeoutTime_ESL" SG_ 2654339161 PreviousCanNMState_FD16_MCPB 0;
BA_ "GenSigTimeoutTime_ECM" SG_ 2654339161 PreviousCanNMState_FD16_MCPB 0;
BA_ "GenSigTimeoutTime_DTCM" SG_ 2654339161 PreviousCanNMState_FD16_MCPB 0;
BA_ "GenSigTimeoutTime_DMSM" SG_ 2654339161 PreviousCanNMState_FD16_MCPB 0;
BA_ "GenSigTimeoutTime_BSM" SG_ 2654339161 PreviousCanNMState_FD16_MCPB 0;
BA_ "GenSigTimeoutTime_BCM" SG_ 2654339161 PreviousCanNMState_FD16_MCPB 0;
BA_ "GenSigTimeoutTime_AGSM" SG_ 2654339161 PreviousCanNMState_FD16_MCPB 0;
BA_ "GenSigTimeoutTime_ADCAM" SG_ 2654339161 PreviousCanNMState_FD16_MCPB 0;
BA_ "GenSigTimeoutTime_RFHM" SG_ 2654339161 PreviousCanNMState_FD05_MCPB 0;
BA_ "GenSigTimeoutTime_MPAD" SG_ 2654339161 PreviousCanNMState_FD05_MCPB 0;
BA_ "GenSigTimeoutTime_IPC" SG_ 2654339161 PreviousCanNMState_FD05_MCPB 0;
BA_ "GenSigTimeoutTime_GNMM" SG_ 2654339161 PreviousCanNMState_FD05_MCPB 0;
BA_ "GenSigTimeoutTime_EVCU2" SG_ 2654339161 PreviousCanNMState_FD05_MCPB 0;
BA_ "GenSigTimeoutTime_ESL" SG_ 2654339161 PreviousCanNMState_FD05_MCPB 0;
BA_ "GenSigTimeoutTime_ECM" SG_ 2654339161 PreviousCanNMState_FD05_MCPB 0;
BA_ "GenSigTimeoutTime_DTCM" SG_ 2654339161 PreviousCanNMState_FD05_MCPB 0;
BA_ "GenSigTimeoutTime_DMSM" SG_ 2654339161 PreviousCanNMState_FD05_MCPB 0;
BA_ "GenSigTimeoutTime_BSM" SG_ 2654339161 PreviousCanNMState_FD05_MCPB 0;
BA_ "GenSigTimeoutTime_BCM" SG_ 2654339161 PreviousCanNMState_FD05_MCPB 0;
BA_ "GenSigTimeoutTime_AGSM" SG_ 2654339161 PreviousCanNMState_FD05_MCPB 0;
BA_ "GenSigTimeoutTime_ADCAM" SG_ 2654339161 PreviousCanNMState_FD05_MCPB 0;
BA_ "GenSigTimeoutTime_RFHM" SG_ 2654339161 GenericFailSts_FD16_MCPB 0;
BA_ "GenSigTimeoutTime_MPAD" SG_ 2654339161 GenericFailSts_FD16_MCPB 0;
BA_ "GenSigTimeoutTime_IPC" SG_ 2654339161 GenericFailSts_FD16_MCPB 0;
BA_ "GenSigTimeoutTime_GNMM" SG_ 2654339161 GenericFailSts_FD16_MCPB 0;
BA_ "GenSigTimeoutTime_EVCU2" SG_ 2654339161 GenericFailSts_FD16_MCPB 0;
BA_ "GenSigTimeoutTime_ESL" SG_ 2654339161 GenericFailSts_FD16_MCPB 0;
BA_ "GenSigTimeoutTime_ECM" SG_ 2654339161 GenericFailSts_FD16_MCPB 0;
BA_ "GenSigTimeoutTime_DTCM" SG_ 2654339161 GenericFailSts_FD16_MCPB 0;
BA_ "GenSigTimeoutTime_DMSM" SG_ 2654339161 GenericFailSts_FD16_MCPB 0;
BA_ "GenSigTimeoutTime_BSM" SG_ 2654339161 GenericFailSts_FD16_MCPB 0;
BA_ "GenSigTimeoutTime_BCM" SG_ 2654339161 GenericFailSts_FD16_MCPB 0;
BA_ "GenSigTimeoutTime_AGSM" SG_ 2654339161 GenericFailSts_FD16_MCPB 0;
BA_ "GenSigTimeoutTime_ADCAM" SG_ 2654339161 GenericFailSts_FD16_MCPB 0;
BA_ "GenSigTimeoutTime_RFHM" SG_ 2654339161 GenericFailSts_FD05_MCPB 0;
BA_ "GenSigTimeoutTime_MPAD" SG_ 2654339161 GenericFailSts_FD05_MCPB 0;
BA_ "GenSigTimeoutTime_IPC" SG_ 2654339161 GenericFailSts_FD05_MCPB 0;
BA_ "GenSigTimeoutTime_GNMM" SG_ 2654339161 GenericFailSts_FD05_MCPB 0;
BA_ "GenSigTimeoutTime_EVCU2" SG_ 2654339161 GenericFailSts_FD05_MCPB 0;
BA_ "GenSigTimeoutTime_ESL" SG_ 2654339161 GenericFailSts_FD05_MCPB 0;
BA_ "GenSigTimeoutTime_ECM" SG_ 2654339161 GenericFailSts_FD05_MCPB 0;
BA_ "GenSigTimeoutTime_DTCM" SG_ 2654339161 GenericFailSts_FD05_MCPB 0;
BA_ "GenSigTimeoutTime_DMSM" SG_ 2654339161 GenericFailSts_FD05_MCPB 0;
BA_ "GenSigTimeoutTime_BSM" SG_ 2654339161 GenericFailSts_FD05_MCPB 0;
BA_ "GenSigTimeoutTime_AGSM" SG_ 2654339161 GenericFailSts_FD05_MCPB 0;
BA_ "GenSigTimeoutTime_ADCAM" SG_ 2654339161 GenericFailSts_FD05_MCPB 0;
BA_ "GenSigTimeoutTime_RFHM" SG_ 2654339161 EOL_FD16_MCPB 0;
BA_ "GenSigTimeoutTime_MPAD" SG_ 2654339161 EOL_FD16_MCPB 0;
BA_ "GenSigTimeoutTime_IPC" SG_ 2654339161 EOL_FD16_MCPB 0;
BA_ "GenSigTimeoutTime_GNMM" SG_ 2654339161 EOL_FD16_MCPB 0;
BA_ "GenSigTimeoutTime_EVCU2" SG_ 2654339161 EOL_FD16_MCPB 0;
BA_ "GenSigTimeoutTime_ESL" SG_ 2654339161 EOL_FD16_MCPB 0;
BA_ "GenSigTimeoutTime_ECM" SG_ 2654339161 EOL_FD16_MCPB 0;
BA_ "GenSigTimeoutTime_DTCM" SG_ 2654339161 EOL_FD16_MCPB 0;
BA_ "GenSigTimeoutTime_DMSM" SG_ 2654339161 EOL_FD16_MCPB 0;
BA_ "GenSigTimeoutTime_BSM" SG_ 2654339161 EOL_FD16_MCPB 0;
BA_ "GenSigTimeoutTime_BCM" SG_ 2654339161 EOL_FD16_MCPB 0;
BA_ "GenSigTimeoutTime_AGSM" SG_ 2654339161 EOL_FD16_MCPB 0;
BA_ "GenSigTimeoutTime_ADCAM" SG_ 2654339161 EOL_FD16_MCPB 0;
BA_ "GenSigTimeoutTime_RFHM" SG_ 2654339161 EOL_FD05_MCPB 0;
BA_ "GenSigTimeoutTime_MPAD" SG_ 2654339161 EOL_FD05_MCPB 0;
BA_ "GenSigTimeoutTime_IPC" SG_ 2654339161 EOL_FD05_MCPB 0;
BA_ "GenSigTimeoutTime_GNMM" SG_ 2654339161 EOL_FD05_MCPB 0;
BA_ "GenSigTimeoutTime_EVCU2" SG_ 2654339161 EOL_FD05_MCPB 0;
BA_ "GenSigTimeoutTime_ESL" SG_ 2654339161 EOL_FD05_MCPB 0;
BA_ "GenSigTimeoutTime_ECM" SG_ 2654339161 EOL_FD05_MCPB 0;
BA_ "GenSigTimeoutTime_DTCM" SG_ 2654339161 EOL_FD05_MCPB 0;
BA_ "GenSigTimeoutTime_DMSM" SG_ 2654339161 EOL_FD05_MCPB 0;
BA_ "GenSigTimeoutTime_BSM" SG_ 2654339161 EOL_FD05_MCPB 0;
BA_ "GenSigTimeoutTime_AGSM" SG_ 2654339161 EOL_FD05_MCPB 0;
BA_ "GenSigTimeoutTime_ADCAM" SG_ 2654339161 EOL_FD05_MCPB 0;
BA_ "GenSigTimeoutTime_RFHM" SG_ 2654339161 DES_FD16_MCPB 0;
BA_ "GenSigTimeoutTime_MPAD" SG_ 2654339161 DES_FD16_MCPB 0;
BA_ "GenSigTimeoutTime_IPC" SG_ 2654339161 DES_FD16_MCPB 0;
BA_ "GenSigTimeoutTime_GNMM" SG_ 2654339161 DES_FD16_MCPB 0;
BA_ "GenSigTimeoutTime_EVCU2" SG_ 2654339161 DES_FD16_MCPB 0;
BA_ "GenSigTimeoutTime_ESL" SG_ 2654339161 DES_FD16_MCPB 0;
BA_ "GenSigTimeoutTime_ECM" SG_ 2654339161 DES_FD16_MCPB 0;
BA_ "GenSigTimeoutTime_DTCM" SG_ 2654339161 DES_FD16_MCPB 0;
BA_ "GenSigTimeoutTime_DMSM" SG_ 2654339161 DES_FD16_MCPB 0;
BA_ "GenSigTimeoutTime_BSM" SG_ 2654339161 DES_FD16_MCPB 0;
BA_ "GenSigTimeoutTime_BCM" SG_ 2654339161 DES_FD16_MCPB 0;
BA_ "GenSigTimeoutTime_AGSM" SG_ 2654339161 DES_FD16_MCPB 0;
BA_ "GenSigTimeoutTime_ADCAM" SG_ 2654339161 DES_FD16_MCPB 0;
BA_ "GenSigTimeoutTime_RFHM" SG_ 2654339161 DES_FD05_MCPB 0;
BA_ "GenSigTimeoutTime_MPAD" SG_ 2654339161 DES_FD05_MCPB 0;
BA_ "GenSigTimeoutTime_IPC" SG_ 2654339161 DES_FD05_MCPB 0;
BA_ "GenSigTimeoutTime_GNMM" SG_ 2654339161 DES_FD05_MCPB 0;
BA_ "GenSigTimeoutTime_EVCU2" SG_ 2654339161 DES_FD05_MCPB 0;
BA_ "GenSigTimeoutTime_ESL" SG_ 2654339161 DES_FD05_MCPB 0;
BA_ "GenSigTimeoutTime_ECM" SG_ 2654339161 DES_FD05_MCPB 0;
BA_ "GenSigTimeoutTime_DTCM" SG_ 2654339161 DES_FD05_MCPB 0;
BA_ "GenSigTimeoutTime_DMSM" SG_ 2654339161 DES_FD05_MCPB 0;
BA_ "GenSigTimeoutTime_BSM" SG_ 2654339161 DES_FD05_MCPB 0;
BA_ "GenSigTimeoutTime_BCM" SG_ 2654339161 DES_FD05_MCPB 0;
BA_ "GenSigTimeoutTime_AGSM" SG_ 2654339161 DES_FD05_MCPB 0;
BA_ "GenSigTimeoutTime_ADCAM" SG_ 2654339161 DES_FD05_MCPB 0;
BA_ "GenSigTimeoutTime_RFHM" SG_ 2654339161 CurrentFailSts_FD16_MCPB 0;
BA_ "GenSigTimeoutTime_MPAD" SG_ 2654339161 CurrentFailSts_FD16_MCPB 0;
BA_ "GenSigTimeoutTime_IPC" SG_ 2654339161 CurrentFailSts_FD16_MCPB 0;
BA_ "GenSigTimeoutTime_GNMM" SG_ 2654339161 CurrentFailSts_FD16_MCPB 0;
BA_ "GenSigTimeoutTime_EVCU2" SG_ 2654339161 CurrentFailSts_FD16_MCPB 0;
BA_ "GenSigTimeoutTime_ESL" SG_ 2654339161 CurrentFailSts_FD16_MCPB 0;
BA_ "GenSigTimeoutTime_ECM" SG_ 2654339161 CurrentFailSts_FD16_MCPB 0;
BA_ "GenSigTimeoutTime_DTCM" SG_ 2654339161 CurrentFailSts_FD16_MCPB 0;
BA_ "GenSigTimeoutTime_DMSM" SG_ 2654339161 CurrentFailSts_FD16_MCPB 0;
BA_ "GenSigTimeoutTime_BSM" SG_ 2654339161 CurrentFailSts_FD16_MCPB 0;
BA_ "GenSigTimeoutTime_BCM" SG_ 2654339161 CurrentFailSts_FD16_MCPB 0;
BA_ "GenSigTimeoutTime_AGSM" SG_ 2654339161 CurrentFailSts_FD16_MCPB 0;
BA_ "GenSigTimeoutTime_ADCAM" SG_ 2654339161 CurrentFailSts_FD16_MCPB 0;
BA_ "GenSigTimeoutTime_RFHM" SG_ 2654339161 CurrentFailSts_FD05_MCPB 0;
BA_ "GenSigTimeoutTime_MPAD" SG_ 2654339161 CurrentFailSts_FD05_MCPB 0;
BA_ "GenSigTimeoutTime_IPC" SG_ 2654339161 CurrentFailSts_FD05_MCPB 0;
BA_ "GenSigTimeoutTime_GNMM" SG_ 2654339161 CurrentFailSts_FD05_MCPB 0;
BA_ "GenSigTimeoutTime_EVCU2" SG_ 2654339161 CurrentFailSts_FD05_MCPB 0;
BA_ "GenSigTimeoutTime_ESL" SG_ 2654339161 CurrentFailSts_FD05_MCPB 0;
BA_ "GenSigTimeoutTime_ECM" SG_ 2654339161 CurrentFailSts_FD05_MCPB 0;
BA_ "GenSigTimeoutTime_DTCM" SG_ 2654339161 CurrentFailSts_FD05_MCPB 0;
BA_ "GenSigTimeoutTime_DMSM" SG_ 2654339161 CurrentFailSts_FD05_MCPB 0;
BA_ "GenSigTimeoutTime_BSM" SG_ 2654339161 CurrentFailSts_FD05_MCPB 0;
BA_ "GenSigTimeoutTime_AGSM" SG_ 2654339161 CurrentFailSts_FD05_MCPB 0;
BA_ "GenSigTimeoutTime_ADCAM" SG_ 2654339161 CurrentFailSts_FD05_MCPB 0;
BA_ "GenSigTimeoutTime_RFHM" SG_ 2654339161 CurrentCanNMState_FD16_MCPB 0;
BA_ "GenSigTimeoutTime_MPAD" SG_ 2654339161 CurrentCanNMState_FD16_MCPB 0;
BA_ "GenSigTimeoutTime_IPC" SG_ 2654339161 CurrentCanNMState_FD16_MCPB 0;
BA_ "GenSigTimeoutTime_GNMM" SG_ 2654339161 CurrentCanNMState_FD16_MCPB 0;
BA_ "GenSigTimeoutTime_EVCU2" SG_ 2654339161 CurrentCanNMState_FD16_MCPB 0;
BA_ "GenSigTimeoutTime_ESL" SG_ 2654339161 CurrentCanNMState_FD16_MCPB 0;
BA_ "GenSigTimeoutTime_ECM" SG_ 2654339161 CurrentCanNMState_FD16_MCPB 0;
BA_ "GenSigTimeoutTime_DTCM" SG_ 2654339161 CurrentCanNMState_FD16_MCPB 0;
BA_ "GenSigTimeoutTime_DMSM" SG_ 2654339161 CurrentCanNMState_FD16_MCPB 0;
BA_ "GenSigTimeoutTime_BSM" SG_ 2654339161 CurrentCanNMState_FD16_MCPB 0;
BA_ "GenSigTimeoutTime_BCM" SG_ 2654339161 CurrentCanNMState_FD16_MCPB 0;
BA_ "GenSigTimeoutTime_AGSM" SG_ 2654339161 CurrentCanNMState_FD16_MCPB 0;
BA_ "GenSigTimeoutTime_ADCAM" SG_ 2654339161 CurrentCanNMState_FD16_MCPB 0;
BA_ "GenSigTimeoutTime_RFHM" SG_ 2654339161 CurrentCanNMState_FD05_MCPB 0;
BA_ "GenSigTimeoutTime_MPAD" SG_ 2654339161 CurrentCanNMState_FD05_MCPB 0;
BA_ "GenSigTimeoutTime_IPC" SG_ 2654339161 CurrentCanNMState_FD05_MCPB 0;
BA_ "GenSigTimeoutTime_GNMM" SG_ 2654339161 CurrentCanNMState_FD05_MCPB 0;
BA_ "GenSigTimeoutTime_EVCU2" SG_ 2654339161 CurrentCanNMState_FD05_MCPB 0;
BA_ "GenSigTimeoutTime_ESL" SG_ 2654339161 CurrentCanNMState_FD05_MCPB 0;
BA_ "GenSigTimeoutTime_ECM" SG_ 2654339161 CurrentCanNMState_FD05_MCPB 0;
BA_ "GenSigTimeoutTime_DTCM" SG_ 2654339161 CurrentCanNMState_FD05_MCPB 0;
BA_ "GenSigTimeoutTime_DMSM" SG_ 2654339161 CurrentCanNMState_FD05_MCPB 0;
BA_ "GenSigTimeoutTime_BSM" SG_ 2654339161 CurrentCanNMState_FD05_MCPB 0;
BA_ "GenSigTimeoutTime_BCM" SG_ 2654339161 CurrentCanNMState_FD05_MCPB 0;
BA_ "GenSigTimeoutTime_AGSM" SG_ 2654339161 CurrentCanNMState_FD05_MCPB 0;
BA_ "GenSigTimeoutTime_ADCAM" SG_ 2654339161 CurrentCanNMState_FD05_MCPB 0;
BA_ "GenSigTimeoutTime_RFHM" SG_ 2654339160 WakeupSource_FD16_MCPA 0;
BA_ "GenSigTimeoutTime_MPAD" SG_ 2654339160 WakeupSource_FD16_MCPA 0;
BA_ "GenSigTimeoutTime_IPC" SG_ 2654339160 WakeupSource_FD16_MCPA 0;
BA_ "GenSigTimeoutTime_GNMM" SG_ 2654339160 WakeupSource_FD16_MCPA 0;
BA_ "GenSigTimeoutTime_EVCU2" SG_ 2654339160 WakeupSource_FD16_MCPA 0;
BA_ "GenSigTimeoutTime_ESL" SG_ 2654339160 WakeupSource_FD16_MCPA 0;
BA_ "GenSigTimeoutTime_ECM" SG_ 2654339160 WakeupSource_FD16_MCPA 0;
BA_ "GenSigTimeoutTime_DTCM" SG_ 2654339160 WakeupSource_FD16_MCPA 0;
BA_ "GenSigTimeoutTime_DMSM" SG_ 2654339160 WakeupSource_FD16_MCPA 0;
BA_ "GenSigTimeoutTime_BSM" SG_ 2654339160 WakeupSource_FD16_MCPA 0;
BA_ "GenSigTimeoutTime_BCM" SG_ 2654339160 WakeupSource_FD16_MCPA 0;
BA_ "GenSigTimeoutTime_AGSM" SG_ 2654339160 WakeupSource_FD16_MCPA 0;
BA_ "GenSigTimeoutTime_ADCAM" SG_ 2654339160 WakeupSource_FD16_MCPA 0;
BA_ "GenSigTimeoutTime_DTCM" SG_ 2654339160 WakeupSource_FD05_MCPA 0;
BA_ "GenSigTimeoutTime_DMSM" SG_ 2654339160 WakeupSource_FD05_MCPA 0;
BA_ "GenSigTimeoutTime_BSM" SG_ 2654339160 WakeupSource_FD05_MCPA 0;
BA_ "GenSigTimeoutTime_BCM" SG_ 2654339160 WakeupSource_FD05_MCPA 0;
BA_ "GenSigTimeoutTime_AGSM" SG_ 2654339160 WakeupSource_FD05_MCPA 0;
BA_ "GenSigTimeoutTime_ADCAM" SG_ 2654339160 WakeupSource_FD05_MCPA 0;
BA_ "GenSigTimeoutTime_RFHM" SG_ 2654339160 WakeupSource_FD05_MCPA 0;
BA_ "GenSigTimeoutTime_MPAD" SG_ 2654339160 WakeupSource_FD05_MCPA 0;
BA_ "GenSigTimeoutTime_IPC" SG_ 2654339160 WakeupSource_FD05_MCPA 0;
BA_ "GenSigTimeoutTime_GNMM" SG_ 2654339160 WakeupSource_FD05_MCPA 0;
BA_ "GenSigTimeoutTime_EVCU2" SG_ 2654339160 WakeupSource_FD05_MCPA 0;
BA_ "GenSigTimeoutTime_ESL" SG_ 2654339160 WakeupSource_FD05_MCPA 0;
BA_ "GenSigTimeoutTime_ECM" SG_ 2654339160 WakeupSource_FD05_MCPA 0;
BA_ "GenSigTimeoutTime_RFHM" SG_ 2654339160 StayActiveSource_FD16_MCPA 0;
BA_ "GenSigTimeoutTime_MPAD" SG_ 2654339160 StayActiveSource_FD16_MCPA 0;
BA_ "GenSigTimeoutTime_IPC" SG_ 2654339160 StayActiveSource_FD16_MCPA 0;
BA_ "GenSigTimeoutTime_GNMM" SG_ 2654339160 StayActiveSource_FD16_MCPA 0;
BA_ "GenSigTimeoutTime_EVCU2" SG_ 2654339160 StayActiveSource_FD16_MCPA 0;
BA_ "GenSigTimeoutTime_ESL" SG_ 2654339160 StayActiveSource_FD16_MCPA 0;
BA_ "GenSigTimeoutTime_ECM" SG_ 2654339160 StayActiveSource_FD16_MCPA 0;
BA_ "GenSigTimeoutTime_DTCM" SG_ 2654339160 StayActiveSource_FD16_MCPA 0;
BA_ "GenSigTimeoutTime_DMSM" SG_ 2654339160 StayActiveSource_FD16_MCPA 0;
BA_ "GenSigTimeoutTime_BSM" SG_ 2654339160 StayActiveSource_FD16_MCPA 0;
BA_ "GenSigTimeoutTime_BCM" SG_ 2654339160 StayActiveSource_FD16_MCPA 0;
BA_ "GenSigTimeoutTime_AGSM" SG_ 2654339160 StayActiveSource_FD16_MCPA 0;
BA_ "GenSigTimeoutTime_ADCAM" SG_ 2654339160 StayActiveSource_FD16_MCPA 0;
BA_ "GenSigTimeoutTime_SGW" SG_ 2651930809 Digit_11_WCPM2 0;
BA_ "GenSigTimeoutTime_RFHM" SG_ 2651930809 Digit_11_WCPM2 0;
BA_ "GenSigTimeoutTime_MPAD" SG_ 2651930809 Digit_11_WCPM2 0;
BA_ "GenSigTimeoutTime_IPC" SG_ 2651930809 Digit_11_WCPM2 0;
BA_ "GenSigTimeoutTime_GNMM" SG_ 2651930809 Digit_11_WCPM2 0;
BA_ "GenSigTimeoutTime_EVCU2" SG_ 2651930809 Digit_11_WCPM2 0;
BA_ "GenSigTimeoutTime_ESL" SG_ 2651930809 Digit_11_WCPM2 0;
BA_ "GenSigTimeoutTime_ECM" SG_ 2651930809 Digit_11_WCPM2 0;
BA_ "GenSigTimeoutTime_DTCM" SG_ 2651930809 Digit_11_WCPM2 0;
BA_ "GenSigTimeoutTime_DMSM" SG_ 2651930809 Digit_11_WCPM2 0;
BA_ "GenSigTimeoutTime_BSM" SG_ 2651930809 Digit_11_WCPM2 0;
BA_ "GenSigTimeoutTime_AGSM" SG_ 2651930809 Digit_11_WCPM2 0;
BA_ "GenSigTimeoutTime_ADCAM" SG_ 2651930809 Digit_11_WCPM2 0;
BA_ "GenSigTimeoutTime_SGW" SG_ 2651930809 Digit_10_WCPM2 0;
BA_ "GenSigTimeoutTime_RFHM" SG_ 2651930809 Digit_10_WCPM2 0;
BA_ "GenSigTimeoutTime_MPAD" SG_ 2651930809 Digit_10_WCPM2 0;
BA_ "GenSigTimeoutTime_IPC" SG_ 2651930809 Digit_10_WCPM2 0;
BA_ "GenSigTimeoutTime_GNMM" SG_ 2651930809 Digit_10_WCPM2 0;
BA_ "GenSigTimeoutTime_EVCU2" SG_ 2651930809 Digit_10_WCPM2 0;
BA_ "GenSigTimeoutTime_ESL" SG_ 2651930809 Digit_10_WCPM2 0;
BA_ "GenSigTimeoutTime_ECM" SG_ 2651930809 Digit_10_WCPM2 0;
BA_ "GenSigTimeoutTime_DTCM" SG_ 2651930809 Digit_10_WCPM2 0;
BA_ "GenSigTimeoutTime_DMSM" SG_ 2651930809 Digit_10_WCPM2 0;
BA_ "GenSigTimeoutTime_BSM" SG_ 2651930809 Digit_10_WCPM2 0;
BA_ "GenSigTimeoutTime_AGSM" SG_ 2651930809 Digit_10_WCPM2 0;
BA_ "GenSigTimeoutTime_ADCAM" SG_ 2651930809 Digit_10_WCPM2 0;
BA_ "GenSigTimeoutTime_SGW" SG_ 2651930809 Digit_09_WCPM2 0;
BA_ "GenSigTimeoutTime_RFHM" SG_ 2651930809 Digit_09_WCPM2 0;
BA_ "GenSigTimeoutTime_MPAD" SG_ 2651930809 Digit_09_WCPM2 0;
BA_ "GenSigTimeoutTime_IPC" SG_ 2651930809 Digit_09_WCPM2 0;
BA_ "GenSigTimeoutTime_GNMM" SG_ 2651930809 Digit_09_WCPM2 0;
BA_ "GenSigTimeoutTime_EVCU2" SG_ 2651930809 Digit_09_WCPM2 0;
BA_ "GenSigTimeoutTime_ESL" SG_ 2651930809 Digit_09_WCPM2 0;
BA_ "GenSigTimeoutTime_ECM" SG_ 2651930809 Digit_09_WCPM2 0;
BA_ "GenSigTimeoutTime_DTCM" SG_ 2651930809 Digit_09_WCPM2 0;
BA_ "GenSigTimeoutTime_DMSM" SG_ 2651930809 Digit_09_WCPM2 0;
BA_ "GenSigTimeoutTime_BSM" SG_ 2651930809 Digit_09_WCPM2 0;
BA_ "GenSigTimeoutTime_AGSM" SG_ 2651930809 Digit_09_WCPM2 0;
BA_ "GenSigTimeoutTime_ADCAM" SG_ 2651930809 Digit_09_WCPM2 0;
BA_ "GenSigTimeoutTime_ADCAM" SG_ 2651930809 Digit_08_WCPM2 0;
BA_ "GenSigTimeoutTime_SGW" SG_ 2651930809 Digit_08_WCPM2 0;
BA_ "GenSigTimeoutTime_RFHM" SG_ 2651930809 Digit_08_WCPM2 0;
BA_ "GenSigTimeoutTime_MPAD" SG_ 2651930809 Digit_08_WCPM2 0;
BA_ "GenSigTimeoutTime_IPC" SG_ 2651930809 Digit_08_WCPM2 0;
BA_ "GenSigTimeoutTime_GNMM" SG_ 2651930809 Digit_08_WCPM2 0;
BA_ "GenSigTimeoutTime_EVCU2" SG_ 2651930809 Digit_08_WCPM2 0;
BA_ "GenSigTimeoutTime_ESL" SG_ 2651930809 Digit_08_WCPM2 0;
BA_ "GenSigTimeoutTime_ECM" SG_ 2651930809 Digit_08_WCPM2 0;
BA_ "GenSigTimeoutTime_DTCM" SG_ 2651930809 Digit_08_WCPM2 0;
BA_ "GenSigTimeoutTime_DMSM" SG_ 2651930809 Digit_08_WCPM2 0;
BA_ "GenSigTimeoutTime_BSM" SG_ 2651930809 Digit_08_WCPM2 0;
BA_ "GenSigTimeoutTime_AGSM" SG_ 2651930809 Digit_08_WCPM2 0;
BA_ "GenSigTimeoutTime_SGW" SG_ 2651930809 Digit_07_WCPM2 0;
BA_ "GenSigTimeoutTime_RFHM" SG_ 2651930809 Digit_07_WCPM2 0;
BA_ "GenSigTimeoutTime_MPAD" SG_ 2651930809 Digit_07_WCPM2 0;
BA_ "GenSigTimeoutTime_IPC" SG_ 2651930809 Digit_07_WCPM2 0;
BA_ "GenSigTimeoutTime_GNMM" SG_ 2651930809 Digit_07_WCPM2 0;
BA_ "GenSigTimeoutTime_EVCU2" SG_ 2651930809 Digit_07_WCPM2 0;
BA_ "GenSigTimeoutTime_ESL" SG_ 2651930809 Digit_07_WCPM2 0;
BA_ "GenSigTimeoutTime_ECM" SG_ 2651930809 Digit_07_WCPM2 0;
BA_ "GenSigTimeoutTime_DTCM" SG_ 2651930809 Digit_07_WCPM2 0;
BA_ "GenSigTimeoutTime_DMSM" SG_ 2651930809 Digit_07_WCPM2 0;
BA_ "GenSigTimeoutTime_BSM" SG_ 2651930809 Digit_07_WCPM2 0;
BA_ "GenSigTimeoutTime_AGSM" SG_ 2651930809 Digit_07_WCPM2 0;
BA_ "GenSigTimeoutTime_ADCAM" SG_ 2651930809 Digit_07_WCPM2 0;
BA_ "GenSigTimeoutTime_SGW" SG_ 2651930809 Digit_06_WCPM2 0;
BA_ "GenSigTimeoutTime_RFHM" SG_ 2651930809 Digit_06_WCPM2 0;
BA_ "GenSigTimeoutTime_MPAD" SG_ 2651930809 Digit_06_WCPM2 0;
BA_ "GenSigTimeoutTime_IPC" SG_ 2651930809 Digit_06_WCPM2 0;
BA_ "GenSigTimeoutTime_GNMM" SG_ 2651930809 Digit_06_WCPM2 0;
BA_ "GenSigTimeoutTime_EVCU2" SG_ 2651930809 Digit_06_WCPM2 0;
BA_ "GenSigTimeoutTime_ESL" SG_ 2651930809 Digit_06_WCPM2 0;
BA_ "GenSigTimeoutTime_ECM" SG_ 2651930809 Digit_06_WCPM2 0;
BA_ "GenSigTimeoutTime_DTCM" SG_ 2651930809 Digit_06_WCPM2 0;
BA_ "GenSigTimeoutTime_DMSM" SG_ 2651930809 Digit_06_WCPM2 0;
BA_ "GenSigTimeoutTime_BSM" SG_ 2651930809 Digit_06_WCPM2 0;
BA_ "GenSigTimeoutTime_AGSM" SG_ 2651930809 Digit_06_WCPM2 0;
BA_ "GenSigTimeoutTime_ADCAM" SG_ 2651930809 Digit_06_WCPM2 0;
BA_ "GenSigTimeoutTime_SGW" SG_ 2651930809 Digit_05_WCPM2 0;
BA_ "GenSigTimeoutTime_RFHM" SG_ 2651930809 Digit_05_WCPM2 0;
BA_ "GenSigTimeoutTime_MPAD" SG_ 2651930809 Digit_05_WCPM2 0;
BA_ "GenSigTimeoutTime_IPC" SG_ 2651930809 Digit_05_WCPM2 0;
BA_ "GenSigTimeoutTime_GNMM" SG_ 2651930809 Digit_05_WCPM2 0;
BA_ "GenSigTimeoutTime_EVCU2" SG_ 2651930809 Digit_05_WCPM2 0;
BA_ "GenSigTimeoutTime_ESL" SG_ 2651930809 Digit_05_WCPM2 0;
BA_ "GenSigTimeoutTime_ECM" SG_ 2651930809 Digit_05_WCPM2 0;
BA_ "GenSigTimeoutTime_DTCM" SG_ 2651930809 Digit_05_WCPM2 0;
BA_ "GenSigTimeoutTime_DMSM" SG_ 2651930809 Digit_05_WCPM2 0;
BA_ "GenSigTimeoutTime_BSM" SG_ 2651930809 Digit_05_WCPM2 0;
BA_ "GenSigTimeoutTime_AGSM" SG_ 2651930809 Digit_05_WCPM2 0;
BA_ "GenSigTimeoutTime_ADCAM" SG_ 2651930809 Digit_05_WCPM2 0;
BA_ "GenSigTimeoutTime_SGW" SG_ 2651930809 Digit_04_WCPM2 0;
BA_ "GenSigTimeoutTime_RFHM" SG_ 2651930809 Digit_04_WCPM2 0;
BA_ "GenSigTimeoutTime_MPAD" SG_ 2651930809 Digit_04_WCPM2 0;
BA_ "GenSigTimeoutTime_IPC" SG_ 2651930809 Digit_04_WCPM2 0;
BA_ "GenSigTimeoutTime_GNMM" SG_ 2651930809 Digit_04_WCPM2 0;
BA_ "GenSigTimeoutTime_EVCU2" SG_ 2651930809 Digit_04_WCPM2 0;
BA_ "GenSigTimeoutTime_ESL" SG_ 2651930809 Digit_04_WCPM2 0;
BA_ "GenSigTimeoutTime_ECM" SG_ 2651930809 Digit_04_WCPM2 0;
BA_ "GenSigTimeoutTime_DTCM" SG_ 2651930809 Digit_04_WCPM2 0;
BA_ "GenSigTimeoutTime_DMSM" SG_ 2651930809 Digit_04_WCPM2 0;
BA_ "GenSigTimeoutTime_BSM" SG_ 2651930809 Digit_04_WCPM2 0;
BA_ "GenSigTimeoutTime_AGSM" SG_ 2651930809 Digit_04_WCPM2 0;
BA_ "GenSigTimeoutTime_ADCAM" SG_ 2651930809 Digit_04_WCPM2 0;
BA_ "GenSigTimeoutTime_SGW" SG_ 2651930809 Digit_03_WCPM2 0;
BA_ "GenSigTimeoutTime_RFHM" SG_ 2651930809 Digit_03_WCPM2 0;
BA_ "GenSigTimeoutTime_MPAD" SG_ 2651930809 Digit_03_WCPM2 0;
BA_ "GenSigTimeoutTime_IPC" SG_ 2651930809 Digit_03_WCPM2 0;
BA_ "GenSigTimeoutTime_GNMM" SG_ 2651930809 Digit_03_WCPM2 0;
BA_ "GenSigTimeoutTime_EVCU2" SG_ 2651930809 Digit_03_WCPM2 0;
BA_ "GenSigTimeoutTime_ESL" SG_ 2651930809 Digit_03_WCPM2 0;
BA_ "GenSigTimeoutTime_ECM" SG_ 2651930809 Digit_03_WCPM2 0;
BA_ "GenSigTimeoutTime_DTCM" SG_ 2651930809 Digit_03_WCPM2 0;
BA_ "GenSigTimeoutTime_DMSM" SG_ 2651930809 Digit_03_WCPM2 0;
BA_ "GenSigTimeoutTime_BSM" SG_ 2651930809 Digit_03_WCPM2 0;
BA_ "GenSigTimeoutTime_AGSM" SG_ 2651930809 Digit_03_WCPM2 0;
BA_ "GenSigTimeoutTime_ADCAM" SG_ 2651930809 Digit_03_WCPM2 0;
BA_ "GenSigTimeoutTime_SGW" SG_ 2651930809 Digit_02_WCPM2 0;
BA_ "GenSigTimeoutTime_RFHM" SG_ 2651930809 Digit_02_WCPM2 0;
BA_ "GenSigTimeoutTime_MPAD" SG_ 2651930809 Digit_02_WCPM2 0;
BA_ "GenSigTimeoutTime_IPC" SG_ 2651930809 Digit_02_WCPM2 0;
BA_ "GenSigTimeoutTime_GNMM" SG_ 2651930809 Digit_02_WCPM2 0;
BA_ "GenSigTimeoutTime_EVCU2" SG_ 2651930809 Digit_02_WCPM2 0;
BA_ "GenSigTimeoutTime_ESL" SG_ 2651930809 Digit_02_WCPM2 0;
BA_ "GenSigTimeoutTime_ECM" SG_ 2651930809 Digit_02_WCPM2 0;
BA_ "GenSigTimeoutTime_DTCM" SG_ 2651930809 Digit_02_WCPM2 0;
BA_ "GenSigTimeoutTime_DMSM" SG_ 2651930809 Digit_02_WCPM2 0;
BA_ "GenSigTimeoutTime_BSM" SG_ 2651930809 Digit_02_WCPM2 0;
BA_ "GenSigTimeoutTime_AGSM" SG_ 2651930809 Digit_02_WCPM2 0;
BA_ "GenSigTimeoutTime_ADCAM" SG_ 2651930809 Digit_02_WCPM2 0;
BA_ "GenSigTimeoutTime_SGW" SG_ 2651930809 Digit_01_WCPM2 0;
BA_ "GenSigTimeoutTime_RFHM" SG_ 2651930809 Digit_01_WCPM2 0;
BA_ "GenSigTimeoutTime_MPAD" SG_ 2651930809 Digit_01_WCPM2 0;
BA_ "GenSigTimeoutTime_IPC" SG_ 2651930809 Digit_01_WCPM2 0;
BA_ "GenSigTimeoutTime_GNMM" SG_ 2651930809 Digit_01_WCPM2 0;
BA_ "GenSigTimeoutTime_EVCU2" SG_ 2651930809 Digit_01_WCPM2 0;
BA_ "GenSigTimeoutTime_ESL" SG_ 2651930809 Digit_01_WCPM2 0;
BA_ "GenSigTimeoutTime_ECM" SG_ 2651930809 Digit_01_WCPM2 0;
BA_ "GenSigTimeoutTime_DTCM" SG_ 2651930809 Digit_01_WCPM2 0;
BA_ "GenSigTimeoutTime_DMSM" SG_ 2651930809 Digit_01_WCPM2 0;
BA_ "GenSigTimeoutTime_BSM" SG_ 2651930809 Digit_01_WCPM2 0;
BA_ "GenSigTimeoutTime_AGSM" SG_ 2651930809 Digit_01_WCPM2 0;
BA_ "GenSigTimeoutTime_ADCAM" SG_ 2651930809 Digit_01_WCPM2 0;
BA_ "GenSigSendType" SG_ 2651930809 Digit_01_WCPM2 1;
BA_ "GenSigTimeoutTime_ADCAM" SG_ 2651930835 Digit_05_NFCD 0;
BA_ "GenSigTimeoutTime_SGW" SG_ 2651930835 Digit_04_NFCD 0;
BA_ "GenSigTimeoutTime_RFHM" SG_ 2651930835 Digit_04_NFCD 0;
BA_ "GenSigTimeoutTime_MPAD" SG_ 2651930835 Digit_04_NFCD 0;
BA_ "GenSigTimeoutTime_IPC" SG_ 2651930835 Digit_04_NFCD 0;
BA_ "GenSigTimeoutTime_GNMM" SG_ 2651930835 Digit_04_NFCD 0;
BA_ "GenSigTimeoutTime_EVCU2" SG_ 2651930835 Digit_04_NFCD 0;
BA_ "GenSigTimeoutTime_ESL" SG_ 2651930835 Digit_04_NFCD 0;
BA_ "GenSigTimeoutTime_ECM" SG_ 2651930835 Digit_04_NFCD 0;
BA_ "GenSigTimeoutTime_DTCM" SG_ 2651930835 Digit_04_NFCD 0;
BA_ "GenSigTimeoutTime_DMSM" SG_ 2651930835 Digit_04_NFCD 0;
BA_ "GenSigTimeoutTime_BSM" SG_ 2651930835 Digit_04_NFCD 0;
BA_ "GenSigTimeoutTime_AGSM" SG_ 2651930835 Digit_04_NFCD 0;
BA_ "GenSigTimeoutTime_ADCAM" SG_ 2651930835 Digit_04_NFCD 0;
BA_ "GenSigTimeoutTime_SGW" SG_ 2651930835 Digit_02_NFCD 0;
BA_ "GenSigTimeoutTime_RFHM" SG_ 2651930835 Digit_02_NFCD 0;
BA_ "GenSigTimeoutTime_MPAD" SG_ 2651930835 Digit_02_NFCD 0;
BA_ "GenSigTimeoutTime_IPC" SG_ 2651930835 Digit_02_NFCD 0;
BA_ "GenSigTimeoutTime_GNMM" SG_ 2651930835 Digit_02_NFCD 0;
BA_ "GenSigTimeoutTime_EVCU2" SG_ 2651930835 Digit_02_NFCD 0;
BA_ "GenSigTimeoutTime_ESL" SG_ 2651930835 Digit_02_NFCD 0;
BA_ "GenSigTimeoutTime_ECM" SG_ 2651930835 Digit_02_NFCD 0;
BA_ "GenSigTimeoutTime_DTCM" SG_ 2651930835 Digit_02_NFCD 0;
BA_ "GenSigTimeoutTime_DMSM" SG_ 2651930835 Digit_02_NFCD 0;
BA_ "GenSigTimeoutTime_BSM" SG_ 2651930835 Digit_02_NFCD 0;
BA_ "GenSigTimeoutTime_AGSM" SG_ 2651930835 Digit_02_NFCD 0;
BA_ "GenSigTimeoutTime_ADCAM" SG_ 2651930835 Digit_02_NFCD 0;
BA_ "GenSigTimeoutTime_SGW" SG_ 2651930835 Digit_03_NFCD 0;
BA_ "GenSigTimeoutTime_RFHM" SG_ 2651930835 Digit_03_NFCD 0;
BA_ "GenSigTimeoutTime_MPAD" SG_ 2651930835 Digit_03_NFCD 0;
BA_ "GenSigTimeoutTime_IPC" SG_ 2651930835 Digit_03_NFCD 0;
BA_ "GenSigTimeoutTime_GNMM" SG_ 2651930835 Digit_03_NFCD 0;
BA_ "GenSigTimeoutTime_EVCU2" SG_ 2651930835 Digit_03_NFCD 0;
BA_ "GenSigTimeoutTime_ESL" SG_ 2651930835 Digit_03_NFCD 0;
BA_ "GenSigTimeoutTime_ECM" SG_ 2651930835 Digit_03_NFCD 0;
BA_ "GenSigTimeoutTime_DTCM" SG_ 2651930835 Digit_03_NFCD 0;
BA_ "GenSigTimeoutTime_DMSM" SG_ 2651930835 Digit_03_NFCD 0;
BA_ "GenSigTimeoutTime_BSM" SG_ 2651930835 Digit_03_NFCD 0;
BA_ "GenSigTimeoutTime_AGSM" SG_ 2651930835 Digit_03_NFCD 0;
BA_ "GenSigTimeoutTime_ADCAM" SG_ 2651930835 Digit_03_NFCD 0;
BA_ "GenSigTimeoutTime_SGW" SG_ 2651930797 Digit_01_MPAD 0;
BA_ "GenSigTimeoutTime_RFHM" SG_ 2651930797 Digit_01_MPAD 0;
BA_ "GenSigTimeoutTime_MPAD" SG_ 2651930797 Digit_01_MPAD 0;
BA_ "GenSigTimeoutTime_IPC" SG_ 2651930797 Digit_01_MPAD 0;
BA_ "GenSigTimeoutTime_GNMM" SG_ 2651930797 Digit_01_MPAD 0;
BA_ "GenSigTimeoutTime_EVCU2" SG_ 2651930797 Digit_01_MPAD 0;
BA_ "GenSigTimeoutTime_ESL" SG_ 2651930797 Digit_01_MPAD 0;
BA_ "GenSigTimeoutTime_ECM" SG_ 2651930797 Digit_01_MPAD 0;
BA_ "GenSigTimeoutTime_DTCM" SG_ 2651930797 Digit_01_MPAD 0;
BA_ "GenSigTimeoutTime_DMSM" SG_ 2651930797 Digit_01_MPAD 0;
BA_ "GenSigTimeoutTime_BSM" SG_ 2651930797 Digit_01_MPAD 0;
BA_ "GenSigTimeoutTime_AGSM" SG_ 2651930797 Digit_01_MPAD 0;
BA_ "GenSigTimeoutTime_ADCAM" SG_ 2651930797 Digit_01_MPAD 0;
BA_ "GenSigSendType" SG_ 2651930797 Digit_01_MPAD 1;
BA_ "GenSigTimeoutTime_SGW" SG_ 2651930797 Digit_02_MPAD 0;
BA_ "GenSigTimeoutTime_RFHM" SG_ 2651930797 Digit_02_MPAD 0;
BA_ "GenSigTimeoutTime_MPAD" SG_ 2651930797 Digit_02_MPAD 0;
BA_ "GenSigTimeoutTime_IPC" SG_ 2651930797 Digit_02_MPAD 0;
BA_ "GenSigTimeoutTime_GNMM" SG_ 2651930797 Digit_02_MPAD 0;
BA_ "GenSigTimeoutTime_EVCU2" SG_ 2651930797 Digit_02_MPAD 0;
BA_ "GenSigTimeoutTime_ESL" SG_ 2651930797 Digit_02_MPAD 0;
BA_ "GenSigTimeoutTime_ECM" SG_ 2651930797 Digit_02_MPAD 0;
BA_ "GenSigTimeoutTime_DTCM" SG_ 2651930797 Digit_02_MPAD 0;
BA_ "GenSigTimeoutTime_DMSM" SG_ 2651930797 Digit_02_MPAD 0;
BA_ "GenSigTimeoutTime_BSM" SG_ 2651930797 Digit_02_MPAD 0;
BA_ "GenSigTimeoutTime_AGSM" SG_ 2651930797 Digit_02_MPAD 0;
BA_ "GenSigTimeoutTime_ADCAM" SG_ 2651930797 Digit_02_MPAD 0;
BA_ "GenSigTimeoutTime_SGW" SG_ 2651930797 Digit_03_MPAD 0;
BA_ "GenSigTimeoutTime_RFHM" SG_ 2651930797 Digit_03_MPAD 0;
BA_ "GenSigTimeoutTime_MPAD" SG_ 2651930797 Digit_03_MPAD 0;
BA_ "GenSigTimeoutTime_IPC" SG_ 2651930797 Digit_03_MPAD 0;
BA_ "GenSigTimeoutTime_GNMM" SG_ 2651930797 Digit_03_MPAD 0;
BA_ "GenSigTimeoutTime_EVCU2" SG_ 2651930797 Digit_03_MPAD 0;
BA_ "GenSigTimeoutTime_ESL" SG_ 2651930797 Digit_03_MPAD 0;
BA_ "GenSigTimeoutTime_ECM" SG_ 2651930797 Digit_03_MPAD 0;
BA_ "GenSigTimeoutTime_DTCM" SG_ 2651930797 Digit_03_MPAD 0;
BA_ "GenSigTimeoutTime_DMSM" SG_ 2651930797 Digit_03_MPAD 0;
BA_ "GenSigTimeoutTime_BSM" SG_ 2651930797 Digit_03_MPAD 0;
BA_ "GenSigTimeoutTime_AGSM" SG_ 2651930797 Digit_03_MPAD 0;
BA_ "GenSigTimeoutTime_ADCAM" SG_ 2651930797 Digit_03_MPAD 0;
BA_ "GenSigTimeoutTime_SGW" SG_ 2651930797 Digit_04_MPAD 0;
BA_ "GenSigTimeoutTime_RFHM" SG_ 2651930797 Digit_04_MPAD 0;
BA_ "GenSigTimeoutTime_MPAD" SG_ 2651930797 Digit_04_MPAD 0;
BA_ "GenSigTimeoutTime_IPC" SG_ 2651930797 Digit_04_MPAD 0;
BA_ "GenSigTimeoutTime_GNMM" SG_ 2651930797 Digit_04_MPAD 0;
BA_ "GenSigTimeoutTime_EVCU2" SG_ 2651930797 Digit_04_MPAD 0;
BA_ "GenSigTimeoutTime_ESL" SG_ 2651930797 Digit_04_MPAD 0;
BA_ "GenSigTimeoutTime_ECM" SG_ 2651930797 Digit_04_MPAD 0;
BA_ "GenSigTimeoutTime_DTCM" SG_ 2651930797 Digit_04_MPAD 0;
BA_ "GenSigTimeoutTime_DMSM" SG_ 2651930797 Digit_04_MPAD 0;
BA_ "GenSigTimeoutTime_BSM" SG_ 2651930797 Digit_04_MPAD 0;
BA_ "GenSigTimeoutTime_AGSM" SG_ 2651930797 Digit_04_MPAD 0;
BA_ "GenSigTimeoutTime_ADCAM" SG_ 2651930797 Digit_04_MPAD 0;
BA_ "GenSigTimeoutTime_SGW" SG_ 2651930797 Digit_05_MPAD 0;
BA_ "GenSigTimeoutTime_RFHM" SG_ 2651930797 Digit_05_MPAD 0;
BA_ "GenSigTimeoutTime_MPAD" SG_ 2651930797 Digit_05_MPAD 0;
BA_ "GenSigTimeoutTime_IPC" SG_ 2651930797 Digit_05_MPAD 0;
BA_ "GenSigTimeoutTime_GNMM" SG_ 2651930797 Digit_05_MPAD 0;
BA_ "GenSigTimeoutTime_EVCU2" SG_ 2651930797 Digit_05_MPAD 0;
BA_ "GenSigTimeoutTime_ESL" SG_ 2651930797 Digit_05_MPAD 0;
BA_ "GenSigTimeoutTime_ECM" SG_ 2651930797 Digit_05_MPAD 0;
BA_ "GenSigTimeoutTime_DTCM" SG_ 2651930797 Digit_05_MPAD 0;
BA_ "GenSigTimeoutTime_DMSM" SG_ 2651930797 Digit_05_MPAD 0;
BA_ "GenSigTimeoutTime_BSM" SG_ 2651930797 Digit_05_MPAD 0;
BA_ "GenSigTimeoutTime_AGSM" SG_ 2651930797 Digit_05_MPAD 0;
BA_ "GenSigTimeoutTime_ADCAM" SG_ 2651930797 Digit_05_MPAD 0;
BA_ "GenSigTimeoutTime_SGW" SG_ 2651930797 Digit_06_MPAD 0;
BA_ "GenSigTimeoutTime_RFHM" SG_ 2651930797 Digit_06_MPAD 0;
BA_ "GenSigTimeoutTime_MPAD" SG_ 2651930797 Digit_06_MPAD 0;
BA_ "GenSigTimeoutTime_IPC" SG_ 2651930797 Digit_06_MPAD 0;
BA_ "GenSigTimeoutTime_GNMM" SG_ 2651930797 Digit_06_MPAD 0;
BA_ "GenSigTimeoutTime_EVCU2" SG_ 2651930797 Digit_06_MPAD 0;
BA_ "GenSigTimeoutTime_ESL" SG_ 2651930797 Digit_06_MPAD 0;
BA_ "GenSigTimeoutTime_ECM" SG_ 2651930797 Digit_06_MPAD 0;
BA_ "GenSigTimeoutTime_DTCM" SG_ 2651930797 Digit_06_MPAD 0;
BA_ "GenSigTimeoutTime_DMSM" SG_ 2651930797 Digit_06_MPAD 0;
BA_ "GenSigTimeoutTime_BSM" SG_ 2651930797 Digit_06_MPAD 0;
BA_ "GenSigTimeoutTime_AGSM" SG_ 2651930797 Digit_06_MPAD 0;
BA_ "GenSigTimeoutTime_ADCAM" SG_ 2651930797 Digit_06_MPAD 0;
BA_ "GenSigTimeoutTime_SGW" SG_ 2651930797 Digit_07_MPAD 0;
BA_ "GenSigTimeoutTime_RFHM" SG_ 2651930797 Digit_07_MPAD 0;
BA_ "GenSigTimeoutTime_MPAD" SG_ 2651930797 Digit_07_MPAD 0;
BA_ "GenSigTimeoutTime_IPC" SG_ 2651930797 Digit_07_MPAD 0;
BA_ "GenSigTimeoutTime_GNMM" SG_ 2651930797 Digit_07_MPAD 0;
BA_ "GenSigTimeoutTime_EVCU2" SG_ 2651930797 Digit_07_MPAD 0;
BA_ "GenSigTimeoutTime_ESL" SG_ 2651930797 Digit_07_MPAD 0;
BA_ "GenSigTimeoutTime_ECM" SG_ 2651930797 Digit_07_MPAD 0;
BA_ "GenSigTimeoutTime_DTCM" SG_ 2651930797 Digit_07_MPAD 0;
BA_ "GenSigTimeoutTime_DMSM" SG_ 2651930797 Digit_07_MPAD 0;
BA_ "GenSigTimeoutTime_BSM" SG_ 2651930797 Digit_07_MPAD 0;
BA_ "GenSigTimeoutTime_AGSM" SG_ 2651930797 Digit_07_MPAD 0;
BA_ "GenSigTimeoutTime_ADCAM" SG_ 2651930797 Digit_07_MPAD 0;
BA_ "GenSigTimeoutTime_SGW" SG_ 2651930797 Digit_08_MPAD 0;
BA_ "GenSigTimeoutTime_RFHM" SG_ 2651930797 Digit_08_MPAD 0;
BA_ "GenSigTimeoutTime_MPAD" SG_ 2651930797 Digit_08_MPAD 0;
BA_ "GenSigTimeoutTime_IPC" SG_ 2651930797 Digit_08_MPAD 0;
BA_ "GenSigTimeoutTime_GNMM" SG_ 2651930797 Digit_08_MPAD 0;
BA_ "GenSigTimeoutTime_EVCU2" SG_ 2651930797 Digit_08_MPAD 0;
BA_ "GenSigTimeoutTime_ESL" SG_ 2651930797 Digit_08_MPAD 0;
BA_ "GenSigTimeoutTime_ECM" SG_ 2651930797 Digit_08_MPAD 0;
BA_ "GenSigTimeoutTime_DTCM" SG_ 2651930797 Digit_08_MPAD 0;
BA_ "GenSigTimeoutTime_DMSM" SG_ 2651930797 Digit_08_MPAD 0;
BA_ "GenSigTimeoutTime_BSM" SG_ 2651930797 Digit_08_MPAD 0;
BA_ "GenSigTimeoutTime_AGSM" SG_ 2651930797 Digit_08_MPAD 0;
BA_ "GenSigTimeoutTime_ADCAM" SG_ 2651930797 Digit_08_MPAD 0;
BA_ "GenSigTimeoutTime_SGW" SG_ 2651930797 Digit_09_MPAD 0;
BA_ "GenSigTimeoutTime_RFHM" SG_ 2651930797 Digit_09_MPAD 0;
BA_ "GenSigTimeoutTime_MPAD" SG_ 2651930797 Digit_09_MPAD 0;
BA_ "GenSigTimeoutTime_IPC" SG_ 2651930797 Digit_09_MPAD 0;
BA_ "GenSigTimeoutTime_GNMM" SG_ 2651930797 Digit_09_MPAD 0;
BA_ "GenSigTimeoutTime_EVCU2" SG_ 2651930797 Digit_09_MPAD 0;
BA_ "GenSigTimeoutTime_ESL" SG_ 2651930797 Digit_09_MPAD 0;
BA_ "GenSigTimeoutTime_ECM" SG_ 2651930797 Digit_09_MPAD 0;
BA_ "GenSigTimeoutTime_DTCM" SG_ 2651930797 Digit_09_MPAD 0;
BA_ "GenSigTimeoutTime_DMSM" SG_ 2651930797 Digit_09_MPAD 0;
BA_ "GenSigTimeoutTime_BSM" SG_ 2651930797 Digit_09_MPAD 0;
BA_ "GenSigTimeoutTime_AGSM" SG_ 2651930797 Digit_09_MPAD 0;
BA_ "GenSigTimeoutTime_ADCAM" SG_ 2651930797 Digit_09_MPAD 0;
BA_ "GenSigTimeoutTime_SGW" SG_ 2651930797 Digit_10_MPAD 0;
BA_ "GenSigTimeoutTime_RFHM" SG_ 2651930797 Digit_10_MPAD 0;
BA_ "GenSigTimeoutTime_MPAD" SG_ 2651930797 Digit_10_MPAD 0;
BA_ "GenSigTimeoutTime_IPC" SG_ 2651930797 Digit_10_MPAD 0;
BA_ "GenSigTimeoutTime_GNMM" SG_ 2651930797 Digit_10_MPAD 0;
BA_ "GenSigTimeoutTime_EVCU2" SG_ 2651930797 Digit_10_MPAD 0;
BA_ "GenSigTimeoutTime_ESL" SG_ 2651930797 Digit_10_MPAD 0;
BA_ "GenSigTimeoutTime_ECM" SG_ 2651930797 Digit_10_MPAD 0;
BA_ "GenSigTimeoutTime_DTCM" SG_ 2651930797 Digit_10_MPAD 0;
BA_ "GenSigTimeoutTime_DMSM" SG_ 2651930797 Digit_10_MPAD 0;
BA_ "GenSigTimeoutTime_BSM" SG_ 2651930797 Digit_10_MPAD 0;
BA_ "GenSigTimeoutTime_AGSM" SG_ 2651930797 Digit_10_MPAD 0;
BA_ "GenSigTimeoutTime_ADCAM" SG_ 2651930797 Digit_10_MPAD 0;
BA_ "GenSigTimeoutTime_SGW" SG_ 2651930797 Digit_11_MPAD 0;
BA_ "GenSigTimeoutTime_RFHM" SG_ 2651930797 Digit_11_MPAD 0;
BA_ "GenSigTimeoutTime_MPAD" SG_ 2651930797 Digit_11_MPAD 0;
BA_ "GenSigTimeoutTime_IPC" SG_ 2651930797 Digit_11_MPAD 0;
BA_ "GenSigTimeoutTime_GNMM" SG_ 2651930797 Digit_11_MPAD 0;
BA_ "GenSigTimeoutTime_EVCU2" SG_ 2651930797 Digit_11_MPAD 0;
BA_ "GenSigTimeoutTime_ESL" SG_ 2651930797 Digit_11_MPAD 0;
BA_ "GenSigTimeoutTime_ECM" SG_ 2651930797 Digit_11_MPAD 0;
BA_ "GenSigTimeoutTime_DTCM" SG_ 2651930797 Digit_11_MPAD 0;
BA_ "GenSigTimeoutTime_DMSM" SG_ 2651930797 Digit_11_MPAD 0;
BA_ "GenSigTimeoutTime_BSM" SG_ 2651930797 Digit_11_MPAD 0;
BA_ "GenSigTimeoutTime_AGSM" SG_ 2651930797 Digit_11_MPAD 0;
BA_ "GenSigTimeoutTime_ADCAM" SG_ 2651930797 Digit_11_MPAD 0;
BA_ "GenSigTimeoutTime_SGW" SG_ 2651930835 Digit_01_NFCD 0;
BA_ "GenSigTimeoutTime_RFHM" SG_ 2651930835 Digit_01_NFCD 0;
BA_ "GenSigTimeoutTime_MPAD" SG_ 2651930835 Digit_01_NFCD 0;
BA_ "GenSigTimeoutTime_IPC" SG_ 2651930835 Digit_01_NFCD 0;
BA_ "GenSigTimeoutTime_GNMM" SG_ 2651930835 Digit_01_NFCD 0;
BA_ "GenSigTimeoutTime_EVCU2" SG_ 2651930835 Digit_01_NFCD 0;
BA_ "GenSigTimeoutTime_ESL" SG_ 2651930835 Digit_01_NFCD 0;
BA_ "GenSigTimeoutTime_ECM" SG_ 2651930835 Digit_01_NFCD 0;
BA_ "GenSigTimeoutTime_DTCM" SG_ 2651930835 Digit_01_NFCD 0;
BA_ "GenSigTimeoutTime_DMSM" SG_ 2651930835 Digit_01_NFCD 0;
BA_ "GenSigTimeoutTime_BSM" SG_ 2651930835 Digit_01_NFCD 0;
BA_ "GenSigTimeoutTime_AGSM" SG_ 2651930835 Digit_01_NFCD 0;
BA_ "GenSigTimeoutTime_ADCAM" SG_ 2651930835 Digit_01_NFCD 0;
BA_ "GenSigSendType" SG_ 2651930835 Digit_01_NFCD 1;
BA_ "GenSigTimeoutTime_SGW" SG_ 2651930688 Digit_08_EVCU2 0;
BA_ "GenSigTimeoutTime_RFHM" SG_ 2651930688 Digit_08_EVCU2 0;
BA_ "GenSigTimeoutTime_MPAD" SG_ 2651930688 Digit_08_EVCU2 0;
BA_ "GenSigTimeoutTime_IPC" SG_ 2651930688 Digit_08_EVCU2 0;
BA_ "GenSigTimeoutTime_GNMM" SG_ 2651930688 Digit_08_EVCU2 0;
BA_ "GenSigTimeoutTime_EVCU2" SG_ 2651930688 Digit_08_EVCU2 0;
BA_ "GenSigTimeoutTime_ESL" SG_ 2651930688 Digit_08_EVCU2 0;
BA_ "GenSigTimeoutTime_ECM" SG_ 2651930688 Digit_08_EVCU2 0;
BA_ "GenSigTimeoutTime_DTCM" SG_ 2651930688 Digit_08_EVCU2 0;
BA_ "GenSigTimeoutTime_DMSM" SG_ 2651930688 Digit_08_EVCU2 0;
BA_ "GenSigTimeoutTime_BSM" SG_ 2651930688 Digit_08_EVCU2 0;
BA_ "GenSigTimeoutTime_AGSM" SG_ 2651930688 Digit_08_EVCU2 0;
BA_ "GenSigTimeoutTime_SGW" SG_ 2651930688 Digit_09_EVCU2 0;
BA_ "GenSigTimeoutTime_RFHM" SG_ 2651930688 Digit_09_EVCU2 0;
BA_ "GenSigTimeoutTime_MPAD" SG_ 2651930688 Digit_09_EVCU2 0;
BA_ "GenSigTimeoutTime_IPC" SG_ 2651930688 Digit_09_EVCU2 0;
BA_ "GenSigTimeoutTime_GNMM" SG_ 2651930688 Digit_09_EVCU2 0;
BA_ "GenSigTimeoutTime_EVCU2" SG_ 2651930688 Digit_09_EVCU2 0;
BA_ "GenSigTimeoutTime_ESL" SG_ 2651930688 Digit_09_EVCU2 0;
BA_ "GenSigTimeoutTime_ECM" SG_ 2651930688 Digit_09_EVCU2 0;
BA_ "GenSigTimeoutTime_DTCM" SG_ 2651930688 Digit_09_EVCU2 0;
BA_ "GenSigTimeoutTime_DMSM" SG_ 2651930688 Digit_09_EVCU2 0;
BA_ "GenSigTimeoutTime_BSM" SG_ 2651930688 Digit_09_EVCU2 0;
BA_ "GenSigTimeoutTime_AGSM" SG_ 2651930688 Digit_09_EVCU2 0;
BA_ "GenSigTimeoutTime_ADCAM" SG_ 2651930688 Digit_09_EVCU2 0;
BA_ "GenSigTimeoutTime_GNMM" SG_ 2651930688 Digit_10_EVCU2 0;
BA_ "GenSigTimeoutTime_EVCU2" SG_ 2651930688 Digit_10_EVCU2 0;
BA_ "GenSigTimeoutTime_ESL" SG_ 2651930688 Digit_10_EVCU2 0;
BA_ "GenSigTimeoutTime_ECM" SG_ 2651930688 Digit_10_EVCU2 0;
BA_ "GenSigTimeoutTime_DTCM" SG_ 2651930688 Digit_10_EVCU2 0;
BA_ "GenSigTimeoutTime_DMSM" SG_ 2651930688 Digit_10_EVCU2 0;
BA_ "GenSigTimeoutTime_BSM" SG_ 2651930688 Digit_10_EVCU2 0;
BA_ "GenSigTimeoutTime_AGSM" SG_ 2651930688 Digit_10_EVCU2 0;
BA_ "GenSigTimeoutTime_ADCAM" SG_ 2651930688 Digit_10_EVCU2 0;
BA_ "GenSigTimeoutTime_SGW" SG_ 2651930688 Digit_10_EVCU2 0;
BA_ "GenSigTimeoutTime_RFHM" SG_ 2651930688 Digit_10_EVCU2 0;
BA_ "GenSigTimeoutTime_MPAD" SG_ 2651930688 Digit_10_EVCU2 0;
BA_ "GenSigTimeoutTime_IPC" SG_ 2651930688 Digit_10_EVCU2 0;
BA_ "GenSigTimeoutTime_SGW" SG_ 2651930688 Digit_11_EVCU2 0;
BA_ "GenSigTimeoutTime_RFHM" SG_ 2651930688 Digit_11_EVCU2 0;
BA_ "GenSigTimeoutTime_MPAD" SG_ 2651930688 Digit_11_EVCU2 0;
BA_ "GenSigTimeoutTime_IPC" SG_ 2651930688 Digit_11_EVCU2 0;
BA_ "GenSigTimeoutTime_GNMM" SG_ 2651930688 Digit_11_EVCU2 0;
BA_ "GenSigTimeoutTime_EVCU2" SG_ 2651930688 Digit_11_EVCU2 0;
BA_ "GenSigTimeoutTime_ESL" SG_ 2651930688 Digit_11_EVCU2 0;
BA_ "GenSigTimeoutTime_ECM" SG_ 2651930688 Digit_11_EVCU2 0;
BA_ "GenSigTimeoutTime_DTCM" SG_ 2651930688 Digit_11_EVCU2 0;
BA_ "GenSigTimeoutTime_DMSM" SG_ 2651930688 Digit_11_EVCU2 0;
BA_ "GenSigTimeoutTime_BSM" SG_ 2651930688 Digit_11_EVCU2 0;
BA_ "GenSigTimeoutTime_AGSM" SG_ 2651930688 Digit_11_EVCU2 0;
BA_ "GenSigTimeoutTime_ADCAM" SG_ 2651930688 Digit_11_EVCU2 0;
BA_ "GenSigTimeoutTime_ADCAM" SG_ 2651930688 Digit_08_EVCU2 0;
BA_ "GenSigTimeoutTime_SGW" SG_ 2651930688 Digit_03_EVCU2 0;
BA_ "GenSigTimeoutTime_RFHM" SG_ 2651930688 Digit_03_EVCU2 0;
BA_ "GenSigTimeoutTime_MPAD" SG_ 2651930688 Digit_03_EVCU2 0;
BA_ "GenSigTimeoutTime_IPC" SG_ 2651930688 Digit_03_EVCU2 0;
BA_ "GenSigTimeoutTime_GNMM" SG_ 2651930688 Digit_03_EVCU2 0;
BA_ "GenSigTimeoutTime_EVCU2" SG_ 2651930688 Digit_03_EVCU2 0;
BA_ "GenSigTimeoutTime_ESL" SG_ 2651930688 Digit_03_EVCU2 0;
BA_ "GenSigTimeoutTime_ECM" SG_ 2651930688 Digit_03_EVCU2 0;
BA_ "GenSigTimeoutTime_DTCM" SG_ 2651930688 Digit_03_EVCU2 0;
BA_ "GenSigTimeoutTime_DMSM" SG_ 2651930688 Digit_03_EVCU2 0;
BA_ "GenSigTimeoutTime_BSM" SG_ 2651930688 Digit_03_EVCU2 0;
BA_ "GenSigTimeoutTime_AGSM" SG_ 2651930688 Digit_03_EVCU2 0;
BA_ "GenSigTimeoutTime_ADCAM" SG_ 2651930688 Digit_03_EVCU2 0;
BA_ "GenSigTimeoutTime_SGW" SG_ 2651930688 Digit_04_EVCU2 0;
BA_ "GenSigTimeoutTime_RFHM" SG_ 2651930688 Digit_04_EVCU2 0;
BA_ "GenSigTimeoutTime_MPAD" SG_ 2651930688 Digit_04_EVCU2 0;
BA_ "GenSigTimeoutTime_IPC" SG_ 2651930688 Digit_04_EVCU2 0;
BA_ "GenSigTimeoutTime_GNMM" SG_ 2651930688 Digit_04_EVCU2 0;
BA_ "GenSigTimeoutTime_EVCU2" SG_ 2651930688 Digit_04_EVCU2 0;
BA_ "GenSigTimeoutTime_ESL" SG_ 2651930688 Digit_04_EVCU2 0;
BA_ "GenSigTimeoutTime_ECM" SG_ 2651930688 Digit_04_EVCU2 0;
BA_ "GenSigTimeoutTime_DTCM" SG_ 2651930688 Digit_04_EVCU2 0;
BA_ "GenSigTimeoutTime_DMSM" SG_ 2651930688 Digit_04_EVCU2 0;
BA_ "GenSigTimeoutTime_BSM" SG_ 2651930688 Digit_04_EVCU2 0;
BA_ "GenSigTimeoutTime_AGSM" SG_ 2651930688 Digit_04_EVCU2 0;
BA_ "GenSigTimeoutTime_ADCAM" SG_ 2651930688 Digit_04_EVCU2 0;
BA_ "GenSigTimeoutTime_SGW" SG_ 2651930688 Digit_05_EVCU2 0;
BA_ "GenSigTimeoutTime_RFHM" SG_ 2651930688 Digit_05_EVCU2 0;
BA_ "GenSigTimeoutTime_MPAD" SG_ 2651930688 Digit_05_EVCU2 0;
BA_ "GenSigTimeoutTime_IPC" SG_ 2651930688 Digit_05_EVCU2 0;
BA_ "GenSigTimeoutTime_GNMM" SG_ 2651930688 Digit_05_EVCU2 0;
BA_ "GenSigTimeoutTime_EVCU2" SG_ 2651930688 Digit_05_EVCU2 0;
BA_ "GenSigTimeoutTime_ESL" SG_ 2651930688 Digit_05_EVCU2 0;
BA_ "GenSigTimeoutTime_ECM" SG_ 2651930688 Digit_05_EVCU2 0;
BA_ "GenSigTimeoutTime_DTCM" SG_ 2651930688 Digit_05_EVCU2 0;
BA_ "GenSigTimeoutTime_DMSM" SG_ 2651930688 Digit_05_EVCU2 0;
BA_ "GenSigTimeoutTime_BSM" SG_ 2651930688 Digit_05_EVCU2 0;
BA_ "GenSigTimeoutTime_AGSM" SG_ 2651930688 Digit_05_EVCU2 0;
BA_ "GenSigTimeoutTime_ADCAM" SG_ 2651930688 Digit_05_EVCU2 0;
BA_ "GenSigTimeoutTime_SGW" SG_ 2651930688 Digit_06_EVCU2 0;
BA_ "GenSigTimeoutTime_RFHM" SG_ 2651930688 Digit_06_EVCU2 0;
BA_ "GenSigTimeoutTime_MPAD" SG_ 2651930688 Digit_06_EVCU2 0;
BA_ "GenSigTimeoutTime_IPC" SG_ 2651930688 Digit_06_EVCU2 0;
BA_ "GenSigTimeoutTime_GNMM" SG_ 2651930688 Digit_06_EVCU2 0;
BA_ "GenSigTimeoutTime_EVCU2" SG_ 2651930688 Digit_06_EVCU2 0;
BA_ "GenSigTimeoutTime_ESL" SG_ 2651930688 Digit_06_EVCU2 0;
BA_ "GenSigTimeoutTime_ECM" SG_ 2651930688 Digit_06_EVCU2 0;
BA_ "GenSigTimeoutTime_DTCM" SG_ 2651930688 Digit_06_EVCU2 0;
BA_ "GenSigTimeoutTime_DMSM" SG_ 2651930688 Digit_06_EVCU2 0;
BA_ "GenSigTimeoutTime_BSM" SG_ 2651930688 Digit_06_EVCU2 0;
BA_ "GenSigTimeoutTime_AGSM" SG_ 2651930688 Digit_06_EVCU2 0;
BA_ "GenSigTimeoutTime_ADCAM" SG_ 2651930688 Digit_06_EVCU2 0;
BA_ "GenSigTimeoutTime_SGW" SG_ 2651930688 Digit_07_EVCU2 0;
BA_ "GenSigTimeoutTime_RFHM" SG_ 2651930688 Digit_07_EVCU2 0;
BA_ "GenSigTimeoutTime_MPAD" SG_ 2651930688 Digit_07_EVCU2 0;
BA_ "GenSigTimeoutTime_IPC" SG_ 2651930688 Digit_07_EVCU2 0;
BA_ "GenSigTimeoutTime_GNMM" SG_ 2651930688 Digit_07_EVCU2 0;
BA_ "GenSigTimeoutTime_EVCU2" SG_ 2651930688 Digit_07_EVCU2 0;
BA_ "GenSigTimeoutTime_ESL" SG_ 2651930688 Digit_07_EVCU2 0;
BA_ "GenSigTimeoutTime_ECM" SG_ 2651930688 Digit_07_EVCU2 0;
BA_ "GenSigTimeoutTime_DTCM" SG_ 2651930688 Digit_07_EVCU2 0;
BA_ "GenSigTimeoutTime_DMSM" SG_ 2651930688 Digit_07_EVCU2 0;
BA_ "GenSigTimeoutTime_BSM" SG_ 2651930688 Digit_07_EVCU2 0;
BA_ "GenSigTimeoutTime_AGSM" SG_ 2651930688 Digit_07_EVCU2 0;
BA_ "GenSigTimeoutTime_ADCAM" SG_ 2651930688 Digit_07_EVCU2 0;
BA_ "GenSigTimeoutTime_SGW" SG_ 2651930688 Digit_01_EVCU2 0;
BA_ "GenSigTimeoutTime_RFHM" SG_ 2651930688 Digit_01_EVCU2 0;
BA_ "GenSigTimeoutTime_MPAD" SG_ 2651930688 Digit_01_EVCU2 0;
BA_ "GenSigTimeoutTime_IPC" SG_ 2651930688 Digit_01_EVCU2 0;
BA_ "GenSigTimeoutTime_GNMM" SG_ 2651930688 Digit_01_EVCU2 0;
BA_ "GenSigTimeoutTime_EVCU2" SG_ 2651930688 Digit_01_EVCU2 0;
BA_ "GenSigTimeoutTime_ESL" SG_ 2651930688 Digit_01_EVCU2 0;
BA_ "GenSigTimeoutTime_ECM" SG_ 2651930688 Digit_01_EVCU2 0;
BA_ "GenSigTimeoutTime_DTCM" SG_ 2651930688 Digit_01_EVCU2 0;
BA_ "GenSigTimeoutTime_DMSM" SG_ 2651930688 Digit_01_EVCU2 0;
BA_ "GenSigTimeoutTime_BSM" SG_ 2651930688 Digit_01_EVCU2 0;
BA_ "GenSigTimeoutTime_AGSM" SG_ 2651930688 Digit_01_EVCU2 0;
BA_ "GenSigTimeoutTime_ADCAM" SG_ 2651930688 Digit_01_EVCU2 0;
BA_ "GenSigSendType" SG_ 2651930688 Digit_01_EVCU2 1;
BA_ "GenSigTimeoutTime_SGW" SG_ 2651930688 Digit_02_EVCU2 0;
BA_ "GenSigTimeoutTime_RFHM" SG_ 2651930688 Digit_02_EVCU2 0;
BA_ "GenSigTimeoutTime_MPAD" SG_ 2651930688 Digit_02_EVCU2 0;
BA_ "GenSigTimeoutTime_IPC" SG_ 2651930688 Digit_02_EVCU2 0;
BA_ "GenSigTimeoutTime_GNMM" SG_ 2651930688 Digit_02_EVCU2 0;
BA_ "GenSigTimeoutTime_EVCU2" SG_ 2651930688 Digit_02_EVCU2 0;
BA_ "GenSigTimeoutTime_ESL" SG_ 2651930688 Digit_02_EVCU2 0;
BA_ "GenSigTimeoutTime_ECM" SG_ 2651930688 Digit_02_EVCU2 0;
BA_ "GenSigTimeoutTime_DTCM" SG_ 2651930688 Digit_02_EVCU2 0;
BA_ "GenSigTimeoutTime_DMSM" SG_ 2651930688 Digit_02_EVCU2 0;
BA_ "GenSigTimeoutTime_BSM" SG_ 2651930688 Digit_02_EVCU2 0;
BA_ "GenSigTimeoutTime_AGSM" SG_ 2651930688 Digit_02_EVCU2 0;
BA_ "GenSigTimeoutTime_ADCAM" SG_ 2651930688 Digit_02_EVCU2 0;
BA_ "GenSigTimeoutTime_SGW" SG_ 145 EmergencyCorridorAssist_Req 0;
BA_ "GenSigTimeoutTime_RFHM" SG_ 145 EmergencyCorridorAssist_Req 0;
BA_ "GenSigTimeoutTime_MPAD" SG_ 145 EmergencyCorridorAssist_Req 0;
BA_ "GenSigTimeoutTime_GNMM" SG_ 145 EmergencyCorridorAssist_Req 0;
BA_ "GenSigTimeoutTime_EVCU2" SG_ 145 EmergencyCorridorAssist_Req 0;
BA_ "GenSigTimeoutTime_ESL" SG_ 145 EmergencyCorridorAssist_Req 0;
BA_ "GenSigTimeoutTime_ECM" SG_ 145 EmergencyCorridorAssist_Req 0;
BA_ "GenSigTimeoutTime_DTCM" SG_ 145 EmergencyCorridorAssist_Req 0;
BA_ "GenSigTimeoutTime_DMSM" SG_ 145 EmergencyCorridorAssist_Req 0;
BA_ "GenSigTimeoutTime_BSM" SG_ 145 EmergencyCorridorAssist_Req 0;
BA_ "GenSigTimeoutTime_BCM" SG_ 145 EmergencyCorridorAssist_Req 0;
BA_ "GenSigTimeoutTime_AGSM" SG_ 145 EmergencyCorridorAssist_Req 0;
BA_ "GenSigTimeoutTime_ADCAM" SG_ 145 EmergencyCorridorAssist_Req 0;
BA_ "GenSigSendType" SG_ 145 EmergencyCorridorAssist_Req 3;
BA_ "GenSigStartValue" SG_ 145 EmergencyCorridorAssist_Req 1;
BA_ "GenSigTimeoutTime_SGW" SG_ 145 PlugAndChargeReq 0;
BA_ "GenSigTimeoutTime_RFHM" SG_ 145 PlugAndChargeReq 0;
BA_ "GenSigTimeoutTime_MPAD" SG_ 145 PlugAndChargeReq 0;
BA_ "GenSigTimeoutTime_IPC" SG_ 145 PlugAndChargeReq 0;
BA_ "GenSigTimeoutTime_GNMM" SG_ 145 PlugAndChargeReq 0;
BA_ "GenSigTimeoutTime_ESL" SG_ 145 PlugAndChargeReq 0;
BA_ "GenSigTimeoutTime_ECM" SG_ 145 PlugAndChargeReq 0;
BA_ "GenSigTimeoutTime_DTCM" SG_ 145 PlugAndChargeReq 0;
BA_ "GenSigTimeoutTime_DMSM" SG_ 145 PlugAndChargeReq 0;
BA_ "GenSigTimeoutTime_BSM" SG_ 145 PlugAndChargeReq 0;
BA_ "GenSigTimeoutTime_BCM" SG_ 145 PlugAndChargeReq 0;
BA_ "GenSigTimeoutTime_AGSM" SG_ 145 PlugAndChargeReq 0;
BA_ "GenSigTimeoutTime_ADCAM" SG_ 145 PlugAndChargeReq 0;
BA_ "GenSigSendType" SG_ 145 PlugAndChargeReq 3;
BA_ "GenSigTimeoutTime_SGW" SG_ 145 StopOnTraffic_Req 0;
BA_ "GenSigTimeoutTime_RFHM" SG_ 145 StopOnTraffic_Req 0;
BA_ "GenSigTimeoutTime_MPAD" SG_ 145 StopOnTraffic_Req 0;
BA_ "GenSigTimeoutTime_GNMM" SG_ 145 StopOnTraffic_Req 0;
BA_ "GenSigTimeoutTime_EVCU2" SG_ 145 StopOnTraffic_Req 0;
BA_ "GenSigTimeoutTime_ESL" SG_ 145 StopOnTraffic_Req 0;
BA_ "GenSigTimeoutTime_ECM" SG_ 145 StopOnTraffic_Req 0;
BA_ "GenSigTimeoutTime_DTCM" SG_ 145 StopOnTraffic_Req 0;
BA_ "GenSigTimeoutTime_DMSM" SG_ 145 StopOnTraffic_Req 0;
BA_ "GenSigTimeoutTime_BSM" SG_ 145 StopOnTraffic_Req 0;
BA_ "GenSigTimeoutTime_BCM" SG_ 145 StopOnTraffic_Req 0;
BA_ "GenSigTimeoutTime_AGSM" SG_ 145 StopOnTraffic_Req 0;
BA_ "GenSigTimeoutTime_ADCAM" SG_ 145 StopOnTraffic_Req 0;
BA_ "GenSigSendType" SG_ 145 StopOnTraffic_Req 3;
BA_ "GenSigStartValue" SG_ 145 StopOnTraffic_Req 2;
BA_ "GenSigTimeoutTime_SGW" SG_ 145 RouteGuidance_Req 0;
BA_ "GenSigTimeoutTime_RFHM" SG_ 145 RouteGuidance_Req 0;
BA_ "GenSigTimeoutTime_MPAD" SG_ 145 RouteGuidance_Req 0;
BA_ "GenSigTimeoutTime_GNMM" SG_ 145 RouteGuidance_Req 0;
BA_ "GenSigTimeoutTime_EVCU2" SG_ 145 RouteGuidance_Req 0;
BA_ "GenSigTimeoutTime_ESL" SG_ 145 RouteGuidance_Req 0;
BA_ "GenSigTimeoutTime_ECM" SG_ 145 RouteGuidance_Req 0;
BA_ "GenSigTimeoutTime_DTCM" SG_ 145 RouteGuidance_Req 0;
BA_ "GenSigTimeoutTime_DMSM" SG_ 145 RouteGuidance_Req 0;
BA_ "GenSigTimeoutTime_BSM" SG_ 145 RouteGuidance_Req 0;
BA_ "GenSigTimeoutTime_BCM" SG_ 145 RouteGuidance_Req 0;
BA_ "GenSigTimeoutTime_AGSM" SG_ 145 RouteGuidance_Req 0;
BA_ "GenSigTimeoutTime_ADCAM" SG_ 145 RouteGuidance_Req 0;
BA_ "GenSigSendType" SG_ 145 RouteGuidance_Req 3;
BA_ "GenSigStartValue" SG_ 145 RouteGuidance_Req 1;
BA_ "GenSigTimeoutTime_SGW" SG_ 145 SpeedAdjust_Req 0;
BA_ "GenSigTimeoutTime_RFHM" SG_ 145 SpeedAdjust_Req 0;
BA_ "GenSigTimeoutTime_MPAD" SG_ 145 SpeedAdjust_Req 0;
BA_ "GenSigTimeoutTime_GNMM" SG_ 145 SpeedAdjust_Req 0;
BA_ "GenSigTimeoutTime_EVCU2" SG_ 145 SpeedAdjust_Req 0;
BA_ "GenSigTimeoutTime_ESL" SG_ 145 SpeedAdjust_Req 0;
BA_ "GenSigTimeoutTime_ECM" SG_ 145 SpeedAdjust_Req 0;
BA_ "GenSigTimeoutTime_DTCM" SG_ 145 SpeedAdjust_Req 0;
BA_ "GenSigTimeoutTime_DMSM" SG_ 145 SpeedAdjust_Req 0;
BA_ "GenSigTimeoutTime_BSM" SG_ 145 SpeedAdjust_Req 0;
BA_ "GenSigTimeoutTime_BCM" SG_ 145 SpeedAdjust_Req 0;
BA_ "GenSigTimeoutTime_AGSM" SG_ 145 SpeedAdjust_Req 0;
BA_ "GenSigTimeoutTime_ADCAM" SG_ 145 SpeedAdjust_Req 0;
BA_ "GenSigSendType" SG_ 145 SpeedAdjust_Req 3;
BA_ "GenSigStartValue" SG_ 145 SpeedAdjust_Req 1;
BA_ "GenSigTimeoutTime_SGW" SG_ 145 E_Coasting_Req 0;
BA_ "GenSigTimeoutTime_RFHM" SG_ 145 E_Coasting_Req 0;
BA_ "GenSigTimeoutTime_IPC" SG_ 145 E_Coasting_Req 0;
BA_ "GenSigTimeoutTime_GNMM" SG_ 145 E_Coasting_Req 0;
BA_ "GenSigTimeoutTime_ESL" SG_ 145 E_Coasting_Req 0;
BA_ "GenSigTimeoutTime_ECM" SG_ 145 E_Coasting_Req 0;
BA_ "GenSigTimeoutTime_DTCM" SG_ 145 E_Coasting_Req 0;
BA_ "GenSigTimeoutTime_DMSM" SG_ 145 E_Coasting_Req 0;
BA_ "GenSigTimeoutTime_BSM" SG_ 145 E_Coasting_Req 0;
BA_ "GenSigTimeoutTime_BCM" SG_ 145 E_Coasting_Req 0;
BA_ "GenSigTimeoutTime_AGSM" SG_ 145 E_Coasting_Req 0;
BA_ "GenSigTimeoutTime_ADCAM" SG_ 145 E_Coasting_Req 0;
BA_ "GenSigSendType" SG_ 145 E_Coasting_Req 3;
BA_ "GenSigStartValue" SG_ 145 E_Coasting_Req 1;
BA_ "GenSigTimeoutTime_SGW" SG_ 145 Creep_Req 0;
BA_ "GenSigTimeoutTime_RFHM" SG_ 145 Creep_Req 0;
BA_ "GenSigTimeoutTime_MPAD" SG_ 145 Creep_Req 0;
BA_ "GenSigTimeoutTime_GNMM" SG_ 145 Creep_Req 0;
BA_ "GenSigTimeoutTime_EVCU2" SG_ 145 Creep_Req 0;
BA_ "GenSigTimeoutTime_ESL" SG_ 145 Creep_Req 0;
BA_ "GenSigTimeoutTime_ECM" SG_ 145 Creep_Req 0;
BA_ "GenSigTimeoutTime_DTCM" SG_ 145 Creep_Req 0;
BA_ "GenSigTimeoutTime_DMSM" SG_ 145 Creep_Req 0;
BA_ "GenSigTimeoutTime_BSM" SG_ 145 Creep_Req 0;
BA_ "GenSigTimeoutTime_BCM" SG_ 145 Creep_Req 0;
BA_ "GenSigTimeoutTime_AGSM" SG_ 145 Creep_Req 0;
BA_ "GenSigTimeoutTime_ADCAM" SG_ 145 Creep_Req 0;
BA_ "GenSigSendType" SG_ 145 Creep_Req 3;
BA_ "GenSigStartValue" SG_ 145 Creep_Req 1;
BA_ "GenSigTimeoutTime_SGW" SG_ 2651930785 Digit_04_ADCAM 0;
BA_ "GenSigTimeoutTime_RFHM" SG_ 2651930785 Digit_04_ADCAM 0;
BA_ "GenSigTimeoutTime_MPAD" SG_ 2651930785 Digit_04_ADCAM 0;
BA_ "GenSigTimeoutTime_IPC" SG_ 2651930785 Digit_04_ADCAM 0;
BA_ "GenSigTimeoutTime_GNMM" SG_ 2651930785 Digit_04_ADCAM 0;
BA_ "GenSigTimeoutTime_EVCU2" SG_ 2651930785 Digit_04_ADCAM 0;
BA_ "GenSigTimeoutTime_ESL" SG_ 2651930785 Digit_04_ADCAM 0;
BA_ "GenSigTimeoutTime_ECM" SG_ 2651930785 Digit_04_ADCAM 0;
BA_ "GenSigTimeoutTime_DTCM" SG_ 2651930785 Digit_04_ADCAM 0;
BA_ "GenSigTimeoutTime_DMSM" SG_ 2651930785 Digit_04_ADCAM 0;
BA_ "GenSigTimeoutTime_BSM" SG_ 2651930785 Digit_04_ADCAM 0;
BA_ "GenSigTimeoutTime_AGSM" SG_ 2651930785 Digit_04_ADCAM 0;
BA_ "GenSigTimeoutTime_ADCAM" SG_ 2651930785 Digit_04_ADCAM 0;
BA_ "GenSigTimeoutTime_SGW" SG_ 2651930785 Digit_05_ADCAM 0;
BA_ "GenSigTimeoutTime_RFHM" SG_ 2651930785 Digit_05_ADCAM 0;
BA_ "GenSigTimeoutTime_MPAD" SG_ 2651930785 Digit_05_ADCAM 0;
BA_ "GenSigTimeoutTime_IPC" SG_ 2651930785 Digit_05_ADCAM 0;
BA_ "GenSigTimeoutTime_GNMM" SG_ 2651930785 Digit_05_ADCAM 0;
BA_ "GenSigTimeoutTime_EVCU2" SG_ 2651930785 Digit_05_ADCAM 0;
BA_ "GenSigTimeoutTime_ESL" SG_ 2651930785 Digit_05_ADCAM 0;
BA_ "GenSigTimeoutTime_ECM" SG_ 2651930785 Digit_05_ADCAM 0;
BA_ "GenSigTimeoutTime_DTCM" SG_ 2651930785 Digit_05_ADCAM 0;
BA_ "GenSigTimeoutTime_DMSM" SG_ 2651930785 Digit_05_ADCAM 0;
BA_ "GenSigTimeoutTime_BSM" SG_ 2651930785 Digit_05_ADCAM 0;
BA_ "GenSigTimeoutTime_AGSM" SG_ 2651930785 Digit_05_ADCAM 0;
BA_ "GenSigTimeoutTime_ADCAM" SG_ 2651930785 Digit_05_ADCAM 0;
BA_ "GenSigTimeoutTime_SGW" SG_ 2651930785 Digit_06_ADCAM 0;
BA_ "GenSigTimeoutTime_RFHM" SG_ 2651930785 Digit_06_ADCAM 0;
BA_ "GenSigTimeoutTime_MPAD" SG_ 2651930785 Digit_06_ADCAM 0;
BA_ "GenSigTimeoutTime_IPC" SG_ 2651930785 Digit_06_ADCAM 0;
BA_ "GenSigTimeoutTime_GNMM" SG_ 2651930785 Digit_06_ADCAM 0;
BA_ "GenSigTimeoutTime_EVCU2" SG_ 2651930785 Digit_06_ADCAM 0;
BA_ "GenSigTimeoutTime_ESL" SG_ 2651930785 Digit_06_ADCAM 0;
BA_ "GenSigTimeoutTime_ECM" SG_ 2651930785 Digit_06_ADCAM 0;
BA_ "GenSigTimeoutTime_DTCM" SG_ 2651930785 Digit_06_ADCAM 0;
BA_ "GenSigTimeoutTime_DMSM" SG_ 2651930785 Digit_06_ADCAM 0;
BA_ "GenSigTimeoutTime_BSM" SG_ 2651930785 Digit_06_ADCAM 0;
BA_ "GenSigTimeoutTime_AGSM" SG_ 2651930785 Digit_06_ADCAM 0;
BA_ "GenSigTimeoutTime_ADCAM" SG_ 2651930785 Digit_06_ADCAM 0;
BA_ "GenSigTimeoutTime_SGW" SG_ 2651930785 Digit_07_ADCAM 0;
BA_ "GenSigTimeoutTime_RFHM" SG_ 2651930785 Digit_07_ADCAM 0;
BA_ "GenSigTimeoutTime_MPAD" SG_ 2651930785 Digit_07_ADCAM 0;
BA_ "GenSigTimeoutTime_IPC" SG_ 2651930785 Digit_07_ADCAM 0;
BA_ "GenSigTimeoutTime_GNMM" SG_ 2651930785 Digit_07_ADCAM 0;
BA_ "GenSigTimeoutTime_EVCU2" SG_ 2651930785 Digit_07_ADCAM 0;
BA_ "GenSigTimeoutTime_ESL" SG_ 2651930785 Digit_07_ADCAM 0;
BA_ "GenSigTimeoutTime_ECM" SG_ 2651930785 Digit_07_ADCAM 0;
BA_ "GenSigTimeoutTime_DTCM" SG_ 2651930785 Digit_07_ADCAM 0;
BA_ "GenSigTimeoutTime_DMSM" SG_ 2651930785 Digit_07_ADCAM 0;
BA_ "GenSigTimeoutTime_BSM" SG_ 2651930785 Digit_07_ADCAM 0;
BA_ "GenSigTimeoutTime_AGSM" SG_ 2651930785 Digit_07_ADCAM 0;
BA_ "GenSigTimeoutTime_ADCAM" SG_ 2651930785 Digit_07_ADCAM 0;
BA_ "GenSigTimeoutTime_SGW" SG_ 2651930785 Digit_08_ADCAM 0;
BA_ "GenSigTimeoutTime_RFHM" SG_ 2651930785 Digit_08_ADCAM 0;
BA_ "GenSigTimeoutTime_MPAD" SG_ 2651930785 Digit_08_ADCAM 0;
BA_ "GenSigTimeoutTime_IPC" SG_ 2651930785 Digit_08_ADCAM 0;
BA_ "GenSigTimeoutTime_GNMM" SG_ 2651930785 Digit_08_ADCAM 0;
BA_ "GenSigTimeoutTime_EVCU2" SG_ 2651930785 Digit_08_ADCAM 0;
BA_ "GenSigTimeoutTime_ESL" SG_ 2651930785 Digit_08_ADCAM 0;
BA_ "GenSigTimeoutTime_ECM" SG_ 2651930785 Digit_08_ADCAM 0;
BA_ "GenSigTimeoutTime_DTCM" SG_ 2651930785 Digit_08_ADCAM 0;
BA_ "GenSigTimeoutTime_DMSM" SG_ 2651930785 Digit_08_ADCAM 0;
BA_ "GenSigTimeoutTime_BSM" SG_ 2651930785 Digit_08_ADCAM 0;
BA_ "GenSigTimeoutTime_AGSM" SG_ 2651930785 Digit_08_ADCAM 0;
BA_ "GenSigTimeoutTime_ADCAM" SG_ 2651930785 Digit_08_ADCAM 0;
BA_ "GenSigTimeoutTime_SGW" SG_ 2651930785 Digit_09_ADCAM 0;
BA_ "GenSigTimeoutTime_RFHM" SG_ 2651930785 Digit_09_ADCAM 0;
BA_ "GenSigTimeoutTime_MPAD" SG_ 2651930785 Digit_09_ADCAM 0;
BA_ "GenSigTimeoutTime_IPC" SG_ 2651930785 Digit_09_ADCAM 0;
BA_ "GenSigTimeoutTime_GNMM" SG_ 2651930785 Digit_09_ADCAM 0;
BA_ "GenSigTimeoutTime_EVCU2" SG_ 2651930785 Digit_09_ADCAM 0;
BA_ "GenSigTimeoutTime_ESL" SG_ 2651930785 Digit_09_ADCAM 0;
BA_ "GenSigTimeoutTime_ECM" SG_ 2651930785 Digit_09_ADCAM 0;
BA_ "GenSigTimeoutTime_DTCM" SG_ 2651930785 Digit_09_ADCAM 0;
BA_ "GenSigTimeoutTime_DMSM" SG_ 2651930785 Digit_09_ADCAM 0;
BA_ "GenSigTimeoutTime_BSM" SG_ 2651930785 Digit_09_ADCAM 0;
BA_ "GenSigTimeoutTime_AGSM" SG_ 2651930785 Digit_09_ADCAM 0;
BA_ "GenSigTimeoutTime_ADCAM" SG_ 2651930785 Digit_09_ADCAM 0;
BA_ "GenSigTimeoutTime_SGW" SG_ 2651930785 Digit_10_ADCAM 0;
BA_ "GenSigTimeoutTime_RFHM" SG_ 2651930785 Digit_10_ADCAM 0;
BA_ "GenSigTimeoutTime_MPAD" SG_ 2651930785 Digit_10_ADCAM 0;
BA_ "GenSigTimeoutTime_IPC" SG_ 2651930785 Digit_10_ADCAM 0;
BA_ "GenSigTimeoutTime_GNMM" SG_ 2651930785 Digit_10_ADCAM 0;
BA_ "GenSigTimeoutTime_EVCU2" SG_ 2651930785 Digit_10_ADCAM 0;
BA_ "GenSigTimeoutTime_ESL" SG_ 2651930785 Digit_10_ADCAM 0;
BA_ "GenSigTimeoutTime_ECM" SG_ 2651930785 Digit_10_ADCAM 0;
BA_ "GenSigTimeoutTime_DTCM" SG_ 2651930785 Digit_10_ADCAM 0;
BA_ "GenSigTimeoutTime_DMSM" SG_ 2651930785 Digit_10_ADCAM 0;
BA_ "GenSigTimeoutTime_BSM" SG_ 2651930785 Digit_10_ADCAM 0;
BA_ "GenSigTimeoutTime_AGSM" SG_ 2651930785 Digit_10_ADCAM 0;
BA_ "GenSigTimeoutTime_ADCAM" SG_ 2651930785 Digit_10_ADCAM 0;
BA_ "GenSigTimeoutTime_SGW" SG_ 2651930785 Digit_11_ADCAM 0;
BA_ "GenSigTimeoutTime_RFHM" SG_ 2651930785 Digit_11_ADCAM 0;
BA_ "GenSigTimeoutTime_MPAD" SG_ 2651930785 Digit_11_ADCAM 0;
BA_ "GenSigTimeoutTime_IPC" SG_ 2651930785 Digit_11_ADCAM 0;
BA_ "GenSigTimeoutTime_GNMM" SG_ 2651930785 Digit_11_ADCAM 0;
BA_ "GenSigTimeoutTime_EVCU2" SG_ 2651930785 Digit_11_ADCAM 0;
BA_ "GenSigTimeoutTime_ESL" SG_ 2651930785 Digit_11_ADCAM 0;
BA_ "GenSigTimeoutTime_ECM" SG_ 2651930785 Digit_11_ADCAM 0;
BA_ "GenSigTimeoutTime_DTCM" SG_ 2651930785 Digit_11_ADCAM 0;
BA_ "GenSigTimeoutTime_DMSM" SG_ 2651930785 Digit_11_ADCAM 0;
BA_ "GenSigTimeoutTime_BSM" SG_ 2651930785 Digit_11_ADCAM 0;
BA_ "GenSigTimeoutTime_AGSM" SG_ 2651930785 Digit_11_ADCAM 0;
BA_ "GenSigTimeoutTime_ADCAM" SG_ 2651930785 Digit_11_ADCAM 0;
BA_ "GenSigTimeoutTime_SGW" SG_ 2651930785 Digit_01_ADCAM 0;
BA_ "GenSigTimeoutTime_RFHM" SG_ 2651930785 Digit_01_ADCAM 0;
BA_ "GenSigTimeoutTime_MPAD" SG_ 2651930785 Digit_01_ADCAM 0;
BA_ "GenSigTimeoutTime_IPC" SG_ 2651930785 Digit_01_ADCAM 0;
BA_ "GenSigTimeoutTime_GNMM" SG_ 2651930785 Digit_01_ADCAM 0;
BA_ "GenSigTimeoutTime_EVCU2" SG_ 2651930785 Digit_01_ADCAM 0;
BA_ "GenSigTimeoutTime_ESL" SG_ 2651930785 Digit_01_ADCAM 0;
BA_ "GenSigTimeoutTime_ECM" SG_ 2651930785 Digit_01_ADCAM 0;
BA_ "GenSigTimeoutTime_DTCM" SG_ 2651930785 Digit_01_ADCAM 0;
BA_ "GenSigTimeoutTime_DMSM" SG_ 2651930785 Digit_01_ADCAM 0;
BA_ "GenSigTimeoutTime_BSM" SG_ 2651930785 Digit_01_ADCAM 0;
BA_ "GenSigTimeoutTime_AGSM" SG_ 2651930785 Digit_01_ADCAM 0;
BA_ "GenSigTimeoutTime_ADCAM" SG_ 2651930785 Digit_01_ADCAM 0;
BA_ "GenSigSendType" SG_ 2651930785 Digit_01_ADCAM 1;
BA_ "GenSigTimeoutTime_ADCAM" SG_ 2651930785 Digit_02_ADCAM 0;
BA_ "GenSigTimeoutTime_SGW" SG_ 2651930785 Digit_02_ADCAM 0;
BA_ "GenSigTimeoutTime_RFHM" SG_ 2651930785 Digit_02_ADCAM 0;
BA_ "GenSigTimeoutTime_MPAD" SG_ 2651930785 Digit_02_ADCAM 0;
BA_ "GenSigTimeoutTime_IPC" SG_ 2651930785 Digit_02_ADCAM 0;
BA_ "GenSigTimeoutTime_GNMM" SG_ 2651930785 Digit_02_ADCAM 0;
BA_ "GenSigTimeoutTime_EVCU2" SG_ 2651930785 Digit_02_ADCAM 0;
BA_ "GenSigTimeoutTime_ESL" SG_ 2651930785 Digit_02_ADCAM 0;
BA_ "GenSigTimeoutTime_ECM" SG_ 2651930785 Digit_02_ADCAM 0;
BA_ "GenSigTimeoutTime_DTCM" SG_ 2651930785 Digit_02_ADCAM 0;
BA_ "GenSigTimeoutTime_DMSM" SG_ 2651930785 Digit_02_ADCAM 0;
BA_ "GenSigTimeoutTime_BSM" SG_ 2651930785 Digit_02_ADCAM 0;
BA_ "GenSigTimeoutTime_AGSM" SG_ 2651930785 Digit_02_ADCAM 0;
BA_ "GenSigTimeoutTime_SGW" SG_ 2651930785 Digit_03_ADCAM 0;
BA_ "GenSigTimeoutTime_RFHM" SG_ 2651930785 Digit_03_ADCAM 0;
BA_ "GenSigTimeoutTime_MPAD" SG_ 2651930785 Digit_03_ADCAM 0;
BA_ "GenSigTimeoutTime_IPC" SG_ 2651930785 Digit_03_ADCAM 0;
BA_ "GenSigTimeoutTime_GNMM" SG_ 2651930785 Digit_03_ADCAM 0;
BA_ "GenSigTimeoutTime_EVCU2" SG_ 2651930785 Digit_03_ADCAM 0;
BA_ "GenSigTimeoutTime_ESL" SG_ 2651930785 Digit_03_ADCAM 0;
BA_ "GenSigTimeoutTime_ECM" SG_ 2651930785 Digit_03_ADCAM 0;
BA_ "GenSigTimeoutTime_DTCM" SG_ 2651930785 Digit_03_ADCAM 0;
BA_ "GenSigTimeoutTime_DMSM" SG_ 2651930785 Digit_03_ADCAM 0;
BA_ "GenSigTimeoutTime_BSM" SG_ 2651930785 Digit_03_ADCAM 0;
BA_ "GenSigTimeoutTime_AGSM" SG_ 2651930785 Digit_03_ADCAM 0;
BA_ "GenSigTimeoutTime_ADCAM" SG_ 2651930785 Digit_03_ADCAM 0;
BA_ "GenSigTimeoutTime_RFHM" SG_ 2654339160 StayActiveSource_FD05_MCPA 0;
BA_ "GenSigTimeoutTime_MPAD" SG_ 2654339160 StayActiveSource_FD05_MCPA 0;
BA_ "GenSigTimeoutTime_IPC" SG_ 2654339160 StayActiveSource_FD05_MCPA 0;
BA_ "GenSigTimeoutTime_GNMM" SG_ 2654339160 StayActiveSource_FD05_MCPA 0;
BA_ "GenSigTimeoutTime_EVCU2" SG_ 2654339160 StayActiveSource_FD05_MCPA 0;
BA_ "GenSigTimeoutTime_ESL" SG_ 2654339160 StayActiveSource_FD05_MCPA 0;
BA_ "GenSigTimeoutTime_ECM" SG_ 2654339160 StayActiveSource_FD05_MCPA 0;
BA_ "GenSigTimeoutTime_DTCM" SG_ 2654339160 StayActiveSource_FD05_MCPA 0;
BA_ "GenSigTimeoutTime_DMSM" SG_ 2654339160 StayActiveSource_FD05_MCPA 0;
BA_ "GenSigTimeoutTime_BSM" SG_ 2654339160 StayActiveSource_FD05_MCPA 0;
BA_ "GenSigTimeoutTime_BCM" SG_ 2654339160 StayActiveSource_FD05_MCPA 0;
BA_ "GenSigTimeoutTime_AGSM" SG_ 2654339160 StayActiveSource_FD05_MCPA 0;
BA_ "GenSigTimeoutTime_ADCAM" SG_ 2654339160 StayActiveSource_FD05_MCPA 0;
BA_ "GenSigTimeoutTime_RFHM" SG_ 2654339161 WakeupSource_FD05_MCPB 0;
BA_ "GenSigTimeoutTime_MPAD" SG_ 2654339161 WakeupSource_FD05_MCPB 0;
BA_ "GenSigTimeoutTime_IPC" SG_ 2654339161 WakeupSource_FD05_MCPB 0;
BA_ "GenSigTimeoutTime_GNMM" SG_ 2654339161 WakeupSource_FD05_MCPB 0;
BA_ "GenSigTimeoutTime_EVCU2" SG_ 2654339161 WakeupSource_FD05_MCPB 0;
BA_ "GenSigTimeoutTime_ESL" SG_ 2654339161 WakeupSource_FD05_MCPB 0;
BA_ "GenSigTimeoutTime_ECM" SG_ 2654339161 WakeupSource_FD05_MCPB 0;
BA_ "GenSigTimeoutTime_DTCM" SG_ 2654339161 WakeupSource_FD05_MCPB 0;
BA_ "GenSigTimeoutTime_DMSM" SG_ 2654339161 WakeupSource_FD05_MCPB 0;
BA_ "GenSigTimeoutTime_BSM" SG_ 2654339161 WakeupSource_FD05_MCPB 0;
BA_ "GenSigTimeoutTime_BCM" SG_ 2654339161 WakeupSource_FD05_MCPB 0;
BA_ "GenSigTimeoutTime_AGSM" SG_ 2654339161 WakeupSource_FD05_MCPB 0;
BA_ "GenSigTimeoutTime_RFHM" SG_ 2654339161 WakeupSource_FD16_MCPB 0;
BA_ "GenSigTimeoutTime_MPAD" SG_ 2654339161 WakeupSource_FD16_MCPB 0;
BA_ "GenSigTimeoutTime_IPC" SG_ 2654339161 WakeupSource_FD16_MCPB 0;
BA_ "GenSigTimeoutTime_GNMM" SG_ 2654339161 WakeupSource_FD16_MCPB 0;
BA_ "GenSigTimeoutTime_EVCU2" SG_ 2654339161 WakeupSource_FD16_MCPB 0;
BA_ "GenSigTimeoutTime_ESL" SG_ 2654339161 WakeupSource_FD16_MCPB 0;
BA_ "GenSigTimeoutTime_ECM" SG_ 2654339161 WakeupSource_FD16_MCPB 0;
BA_ "GenSigTimeoutTime_DTCM" SG_ 2654339161 WakeupSource_FD16_MCPB 0;
BA_ "GenSigTimeoutTime_DMSM" SG_ 2654339161 WakeupSource_FD16_MCPB 0;
BA_ "GenSigTimeoutTime_BSM" SG_ 2654339161 WakeupSource_FD16_MCPB 0;
BA_ "GenSigTimeoutTime_BCM" SG_ 2654339161 WakeupSource_FD16_MCPB 0;
BA_ "GenSigTimeoutTime_AGSM" SG_ 2654339161 WakeupSource_FD16_MCPB 0;
BA_ "GenSigTimeoutTime_ADCAM" SG_ 2654339161 WakeupSource_FD16_MCPB 0;
BA_ "GenSigTimeoutTime_ESL" SG_ 2654339283 CurrentCanNMState_FD09_NFCD 0;
BA_ "GenSigTimeoutTime_ECM" SG_ 2654339283 CurrentCanNMState_FD09_NFCD 0;
BA_ "GenSigTimeoutTime_DTCM" SG_ 2654339283 CurrentCanNMState_FD09_NFCD 0;
BA_ "GenSigTimeoutTime_DMSM" SG_ 2654339283 CurrentCanNMState_FD09_NFCD 0;
BA_ "GenSigTimeoutTime_BSM" SG_ 2654339283 CurrentCanNMState_FD09_NFCD 0;
BA_ "GenSigTimeoutTime_BCM" SG_ 2654339283 CurrentCanNMState_FD09_NFCD 0;
BA_ "GenSigTimeoutTime_RFHM" SG_ 2654339245 CurrentCanNMState_FD03_MPAD 0;
BA_ "GenSigTimeoutTime_MPAD" SG_ 2654339245 CurrentCanNMState_FD03_MPAD 0;
BA_ "GenSigTimeoutTime_IPC" SG_ 2654339245 CurrentCanNMState_FD03_MPAD 0;
BA_ "GenSigTimeoutTime_GNMM" SG_ 2654339245 CurrentCanNMState_FD03_MPAD 0;
BA_ "GenSigTimeoutTime_EVCU2" SG_ 2654339245 CurrentCanNMState_FD03_MPAD 0;
BA_ "GenSigTimeoutTime_ESL" SG_ 2654339245 CurrentCanNMState_FD03_MPAD 0;
BA_ "GenSigTimeoutTime_ECM" SG_ 2654339245 CurrentCanNMState_FD03_MPAD 0;
BA_ "GenSigTimeoutTime_DTCM" SG_ 2654339245 CurrentCanNMState_FD03_MPAD 0;
BA_ "GenSigTimeoutTime_DMSM" SG_ 2654339245 CurrentCanNMState_FD03_MPAD 0;
BA_ "GenSigTimeoutTime_BSM" SG_ 2654339245 CurrentCanNMState_FD03_MPAD 0;
BA_ "GenSigTimeoutTime_BCM" SG_ 2654339245 CurrentCanNMState_FD03_MPAD 0;
BA_ "GenSigTimeoutTime_AGSM" SG_ 2654339245 CurrentCanNMState_FD03_MPAD 0;
BA_ "GenSigTimeoutTime_ADCAM" SG_ 2654339245 CurrentCanNMState_FD03_MPAD 0;
BA_ "GenSigTimeoutTime_RFHM" SG_ 2654339283 WakeupSource_FD09_NFCD 0;
BA_ "GenSigTimeoutTime_MPAD" SG_ 2654339283 WakeupSource_FD09_NFCD 0;
BA_ "GenSigTimeoutTime_IPC" SG_ 2654339283 WakeupSource_FD09_NFCD 0;
BA_ "GenSigTimeoutTime_GNMM" SG_ 2654339283 WakeupSource_FD09_NFCD 0;
BA_ "GenSigTimeoutTime_EVCU2" SG_ 2654339283 WakeupSource_FD09_NFCD 0;
BA_ "GenSigTimeoutTime_ESL" SG_ 2654339283 WakeupSource_FD09_NFCD 0;
BA_ "GenSigTimeoutTime_ECM" SG_ 2654339283 WakeupSource_FD09_NFCD 0;
BA_ "GenSigTimeoutTime_DTCM" SG_ 2654339283 WakeupSource_FD09_NFCD 0;
BA_ "GenSigTimeoutTime_DMSM" SG_ 2654339283 WakeupSource_FD09_NFCD 0;
BA_ "GenSigTimeoutTime_BSM" SG_ 2654339283 WakeupSource_FD09_NFCD 0;
BA_ "GenSigTimeoutTime_BCM" SG_ 2654339283 WakeupSource_FD09_NFCD 0;
BA_ "GenSigTimeoutTime_AGSM" SG_ 2654339283 WakeupSource_FD09_NFCD 0;
BA_ "GenSigTimeoutTime_ADCAM" SG_ 2654339283 WakeupSource_FD09_NFCD 0;
BA_ "GenSigTimeoutTime_RFHM" SG_ 2654339283 StayActiveSource_FD09_NFCD 0;
BA_ "GenSigTimeoutTime_MPAD" SG_ 2654339283 StayActiveSource_FD09_NFCD 0;
BA_ "GenSigTimeoutTime_IPC" SG_ 2654339283 StayActiveSource_FD09_NFCD 0;
BA_ "GenSigTimeoutTime_GNMM" SG_ 2654339283 StayActiveSource_FD09_NFCD 0;
BA_ "GenSigTimeoutTime_EVCU2" SG_ 2654339283 StayActiveSource_FD09_NFCD 0;
BA_ "GenSigTimeoutTime_ESL" SG_ 2654339283 StayActiveSource_FD09_NFCD 0;
BA_ "GenSigTimeoutTime_ECM" SG_ 2654339283 StayActiveSource_FD09_NFCD 0;
BA_ "GenSigTimeoutTime_DTCM" SG_ 2654339283 StayActiveSource_FD09_NFCD 0;
BA_ "GenSigTimeoutTime_DMSM" SG_ 2654339283 StayActiveSource_FD09_NFCD 0;
BA_ "GenSigTimeoutTime_BSM" SG_ 2654339283 StayActiveSource_FD09_NFCD 0;
BA_ "GenSigTimeoutTime_BCM" SG_ 2654339283 StayActiveSource_FD09_NFCD 0;
BA_ "GenSigTimeoutTime_AGSM" SG_ 2654339283 StayActiveSource_FD09_NFCD 0;
BA_ "GenSigTimeoutTime_ADCAM" SG_ 2654339283 StayActiveSource_FD09_NFCD 0;
BA_ "GenSigTimeoutTime_RFHM" SG_ 2654339283 PreviousCanNMState_FD09_NFCD 0;
BA_ "GenSigTimeoutTime_MPAD" SG_ 2654339283 PreviousCanNMState_FD09_NFCD 0;
BA_ "GenSigTimeoutTime_IPC" SG_ 2654339283 PreviousCanNMState_FD09_NFCD 0;
BA_ "GenSigTimeoutTime_GNMM" SG_ 2654339283 PreviousCanNMState_FD09_NFCD 0;
BA_ "GenSigTimeoutTime_EVCU2" SG_ 2654339283 PreviousCanNMState_FD09_NFCD 0;
BA_ "GenSigTimeoutTime_ESL" SG_ 2654339283 PreviousCanNMState_FD09_NFCD 0;
BA_ "GenSigTimeoutTime_ECM" SG_ 2654339283 PreviousCanNMState_FD09_NFCD 0;
BA_ "GenSigTimeoutTime_DTCM" SG_ 2654339283 PreviousCanNMState_FD09_NFCD 0;
BA_ "GenSigTimeoutTime_DMSM" SG_ 2654339283 PreviousCanNMState_FD09_NFCD 0;
BA_ "GenSigTimeoutTime_BSM" SG_ 2654339283 PreviousCanNMState_FD09_NFCD 0;
BA_ "GenSigTimeoutTime_BCM" SG_ 2654339283 PreviousCanNMState_FD09_NFCD 0;
BA_ "GenSigTimeoutTime_AGSM" SG_ 2654339283 PreviousCanNMState_FD09_NFCD 0;
BA_ "GenSigTimeoutTime_ADCAM" SG_ 2654339283 PreviousCanNMState_FD09_NFCD 0;
BA_ "GenSigTimeoutTime_RFHM" SG_ 2654339283 GenericFailSts_FD09_NFCD 0;
BA_ "GenSigTimeoutTime_MPAD" SG_ 2654339283 GenericFailSts_FD09_NFCD 0;
BA_ "GenSigTimeoutTime_IPC" SG_ 2654339283 GenericFailSts_FD09_NFCD 0;
BA_ "GenSigTimeoutTime_GNMM" SG_ 2654339283 GenericFailSts_FD09_NFCD 0;
BA_ "GenSigTimeoutTime_EVCU2" SG_ 2654339283 GenericFailSts_FD09_NFCD 0;
BA_ "GenSigTimeoutTime_ESL" SG_ 2654339283 GenericFailSts_FD09_NFCD 0;
BA_ "GenSigTimeoutTime_ECM" SG_ 2654339283 GenericFailSts_FD09_NFCD 0;
BA_ "GenSigTimeoutTime_DTCM" SG_ 2654339283 GenericFailSts_FD09_NFCD 0;
BA_ "GenSigTimeoutTime_DMSM" SG_ 2654339283 GenericFailSts_FD09_NFCD 0;
BA_ "GenSigTimeoutTime_BSM" SG_ 2654339283 GenericFailSts_FD09_NFCD 0;
BA_ "GenSigTimeoutTime_AGSM" SG_ 2654339283 GenericFailSts_FD09_NFCD 0;
BA_ "GenSigTimeoutTime_ADCAM" SG_ 2654339283 GenericFailSts_FD09_NFCD 0;
BA_ "GenSigTimeoutTime_ADCAM" SG_ 2654339283 EOL_FD09_NFCD 0;
BA_ "GenSigTimeoutTime_RFHM" SG_ 2654339283 EOL_FD09_NFCD 0;
BA_ "GenSigTimeoutTime_MPAD" SG_ 2654339283 EOL_FD09_NFCD 0;
BA_ "GenSigTimeoutTime_IPC" SG_ 2654339283 EOL_FD09_NFCD 0;
BA_ "GenSigTimeoutTime_GNMM" SG_ 2654339283 EOL_FD09_NFCD 0;
BA_ "GenSigTimeoutTime_EVCU2" SG_ 2654339283 EOL_FD09_NFCD 0;
BA_ "GenSigTimeoutTime_ESL" SG_ 2654339283 EOL_FD09_NFCD 0;
BA_ "GenSigTimeoutTime_ECM" SG_ 2654339283 EOL_FD09_NFCD 0;
BA_ "GenSigTimeoutTime_DTCM" SG_ 2654339283 EOL_FD09_NFCD 0;
BA_ "GenSigTimeoutTime_DMSM" SG_ 2654339283 EOL_FD09_NFCD 0;
BA_ "GenSigTimeoutTime_BSM" SG_ 2654339283 EOL_FD09_NFCD 0;
BA_ "GenSigTimeoutTime_AGSM" SG_ 2654339283 EOL_FD09_NFCD 0;
BA_ "GenSigTimeoutTime_RFHM" SG_ 2654339283 CurrentCanNMState_FD09_NFCD 0;
BA_ "GenSigTimeoutTime_MPAD" SG_ 2654339283 CurrentCanNMState_FD09_NFCD 0;
BA_ "GenSigTimeoutTime_IPC" SG_ 2654339283 CurrentCanNMState_FD09_NFCD 0;
BA_ "GenSigTimeoutTime_GNMM" SG_ 2654339283 CurrentCanNMState_FD09_NFCD 0;
BA_ "GenSigTimeoutTime_EVCU2" SG_ 2654339283 CurrentCanNMState_FD09_NFCD 0;
BA_ "GenSigTimeoutTime_RFHM" SG_ 2654339283 DES_FD09_NFCD 0;
BA_ "GenSigTimeoutTime_MPAD" SG_ 2654339283 DES_FD09_NFCD 0;
BA_ "GenSigTimeoutTime_IPC" SG_ 2654339283 DES_FD09_NFCD 0;
BA_ "GenSigTimeoutTime_GNMM" SG_ 2654339283 DES_FD09_NFCD 0;
BA_ "GenSigTimeoutTime_EVCU2" SG_ 2654339283 DES_FD09_NFCD 0;
BA_ "GenSigTimeoutTime_ESL" SG_ 2654339283 DES_FD09_NFCD 0;
BA_ "GenSigTimeoutTime_ECM" SG_ 2654339283 DES_FD09_NFCD 0;
BA_ "GenSigTimeoutTime_DTCM" SG_ 2654339283 DES_FD09_NFCD 0;
BA_ "GenSigTimeoutTime_DMSM" SG_ 2654339283 DES_FD09_NFCD 0;
BA_ "GenSigTimeoutTime_BSM" SG_ 2654339283 DES_FD09_NFCD 0;
BA_ "GenSigTimeoutTime_BCM" SG_ 2654339283 DES_FD09_NFCD 0;
BA_ "GenSigTimeoutTime_AGSM" SG_ 2654339283 DES_FD09_NFCD 0;
BA_ "GenSigTimeoutTime_ADCAM" SG_ 2654339283 DES_FD09_NFCD 0;
BA_ "GenSigTimeoutTime_RFHM" SG_ 2654339283 CurrentFailSts_FD09_NFCD 0;
BA_ "GenSigTimeoutTime_MPAD" SG_ 2654339283 CurrentFailSts_FD09_NFCD 0;
BA_ "GenSigTimeoutTime_IPC" SG_ 2654339283 CurrentFailSts_FD09_NFCD 0;
BA_ "GenSigTimeoutTime_GNMM" SG_ 2654339283 CurrentFailSts_FD09_NFCD 0;
BA_ "GenSigTimeoutTime_EVCU2" SG_ 2654339283 CurrentFailSts_FD09_NFCD 0;
BA_ "GenSigTimeoutTime_ESL" SG_ 2654339283 CurrentFailSts_FD09_NFCD 0;
BA_ "GenSigTimeoutTime_ECM" SG_ 2654339283 CurrentFailSts_FD09_NFCD 0;
BA_ "GenSigTimeoutTime_DTCM" SG_ 2654339283 CurrentFailSts_FD09_NFCD 0;
BA_ "GenSigTimeoutTime_DMSM" SG_ 2654339283 CurrentFailSts_FD09_NFCD 0;
BA_ "GenSigTimeoutTime_BSM" SG_ 2654339283 CurrentFailSts_FD09_NFCD 0;
BA_ "GenSigTimeoutTime_AGSM" SG_ 2654339283 CurrentFailSts_FD09_NFCD 0;
BA_ "GenSigTimeoutTime_ADCAM" SG_ 2654339283 CurrentFailSts_FD09_NFCD 0;
BA_ "GenSigTimeoutTime_RFHM" SG_ 1898 Update_Status_MPAD 0;
BA_ "GenSigTimeoutTime_MPAD" SG_ 1898 Update_Status_MPAD 0;
BA_ "GenSigTimeoutTime_IPC" SG_ 1898 Update_Status_MPAD 0;
BA_ "GenSigTimeoutTime_GNMM" SG_ 1898 Update_Status_MPAD 0;
BA_ "GenSigTimeoutTime_EVCU2" SG_ 1898 Update_Status_MPAD 0;
BA_ "GenSigTimeoutTime_ESL" SG_ 1898 Update_Status_MPAD 0;
BA_ "GenSigTimeoutTime_ECM" SG_ 1898 Update_Status_MPAD 0;
BA_ "GenSigTimeoutTime_DTCM" SG_ 1898 Update_Status_MPAD 0;
BA_ "GenSigTimeoutTime_DMSM" SG_ 1898 Update_Status_MPAD 0;
BA_ "GenSigTimeoutTime_BSM" SG_ 1898 Update_Status_MPAD 0;
BA_ "GenSigTimeoutTime_BCM" SG_ 1898 Update_Status_MPAD 0;
BA_ "GenSigTimeoutTime_AGSM" SG_ 1898 Update_Status_MPAD 0;
BA_ "GenSigTimeoutTime_ADCAM" SG_ 1898 Update_Status_MPAD 0;
BA_ "GenSigTimeoutTime_RFHM" SG_ 1898 Download_Status_MPAD 0;
BA_ "GenSigTimeoutTime_MPAD" SG_ 1898 Download_Status_MPAD 0;
BA_ "GenSigTimeoutTime_IPC" SG_ 1898 Download_Status_MPAD 0;
BA_ "GenSigTimeoutTime_GNMM" SG_ 1898 Download_Status_MPAD 0;
BA_ "GenSigTimeoutTime_EVCU2" SG_ 1898 Download_Status_MPAD 0;
BA_ "GenSigTimeoutTime_ESL" SG_ 1898 Download_Status_MPAD 0;
BA_ "GenSigTimeoutTime_ECM" SG_ 1898 Download_Status_MPAD 0;
BA_ "GenSigTimeoutTime_DTCM" SG_ 1898 Download_Status_MPAD 0;
BA_ "GenSigTimeoutTime_DMSM" SG_ 1898 Download_Status_MPAD 0;
BA_ "GenSigTimeoutTime_BSM" SG_ 1898 Download_Status_MPAD 0;
BA_ "GenSigTimeoutTime_BCM" SG_ 1898 Download_Status_MPAD 0;
BA_ "GenSigTimeoutTime_AGSM" SG_ 1898 Download_Status_MPAD 0;
BA_ "GenSigTimeoutTime_ADCAM" SG_ 1898 Download_Status_MPAD 0;
BA_ "GenSigTimeoutTime_RFHM" SG_ 1898 Big_ECU_Ready_MPAD 0;
BA_ "GenSigTimeoutTime_MPAD" SG_ 1898 Big_ECU_Ready_MPAD 0;
BA_ "GenSigTimeoutTime_IPC" SG_ 1898 Big_ECU_Ready_MPAD 0;
BA_ "GenSigTimeoutTime_GNMM" SG_ 1898 Big_ECU_Ready_MPAD 0;
BA_ "GenSigTimeoutTime_EVCU2" SG_ 1898 Big_ECU_Ready_MPAD 0;
BA_ "GenSigTimeoutTime_ESL" SG_ 1898 Big_ECU_Ready_MPAD 0;
BA_ "GenSigTimeoutTime_ECM" SG_ 1898 Big_ECU_Ready_MPAD 0;
BA_ "GenSigTimeoutTime_DTCM" SG_ 1898 Big_ECU_Ready_MPAD 0;
BA_ "GenSigTimeoutTime_DMSM" SG_ 1898 Big_ECU_Ready_MPAD 0;
BA_ "GenSigTimeoutTime_BSM" SG_ 1898 Big_ECU_Ready_MPAD 0;
BA_ "GenSigTimeoutTime_BCM" SG_ 1898 Big_ECU_Ready_MPAD 0;
BA_ "GenSigTimeoutTime_AGSM" SG_ 1898 Big_ECU_Ready_MPAD 0;
BA_ "GenSigTimeoutTime_ADCAM" SG_ 1898 Big_ECU_Ready_MPAD 0;
BA_ "GenSigTimeoutTime_RFHM" SG_ 1900 Update_Status_ADCAM 0;
BA_ "GenSigTimeoutTime_MPAD" SG_ 1900 Update_Status_ADCAM 0;
BA_ "GenSigTimeoutTime_IPC" SG_ 1900 Update_Status_ADCAM 0;
BA_ "GenSigTimeoutTime_GNMM" SG_ 1900 Update_Status_ADCAM 0;
BA_ "GenSigTimeoutTime_EVCU2" SG_ 1900 Update_Status_ADCAM 0;
BA_ "GenSigTimeoutTime_ESL" SG_ 1900 Update_Status_ADCAM 0;
BA_ "GenSigTimeoutTime_ECM" SG_ 1900 Update_Status_ADCAM 0;
BA_ "GenSigTimeoutTime_DTCM" SG_ 1900 Update_Status_ADCAM 0;
BA_ "GenSigTimeoutTime_DMSM" SG_ 1900 Update_Status_ADCAM 0;
BA_ "GenSigTimeoutTime_BSM" SG_ 1900 Update_Status_ADCAM 0;
BA_ "GenSigTimeoutTime_BCM" SG_ 1900 Update_Status_ADCAM 0;
BA_ "GenSigTimeoutTime_AGSM" SG_ 1900 Update_Status_ADCAM 0;
BA_ "GenSigTimeoutTime_ADCAM" SG_ 1900 Update_Status_ADCAM 0;
BA_ "GenSigTimeoutTime_RFHM" SG_ 1900 Download_Status_ADCAM 0;
BA_ "GenSigTimeoutTime_MPAD" SG_ 1900 Download_Status_ADCAM 0;
BA_ "GenSigTimeoutTime_IPC" SG_ 1900 Download_Status_ADCAM 0;
BA_ "GenSigTimeoutTime_GNMM" SG_ 1900 Download_Status_ADCAM 0;
BA_ "GenSigTimeoutTime_EVCU2" SG_ 1900 Download_Status_ADCAM 0;
BA_ "GenSigTimeoutTime_ESL" SG_ 1900 Download_Status_ADCAM 0;
BA_ "GenSigTimeoutTime_ECM" SG_ 1900 Download_Status_ADCAM 0;
BA_ "GenSigTimeoutTime_DTCM" SG_ 1900 Download_Status_ADCAM 0;
BA_ "GenSigTimeoutTime_DMSM" SG_ 1900 Download_Status_ADCAM 0;
BA_ "GenSigTimeoutTime_BSM" SG_ 1900 Download_Status_ADCAM 0;
BA_ "GenSigTimeoutTime_BCM" SG_ 1900 Download_Status_ADCAM 0;
BA_ "GenSigTimeoutTime_AGSM" SG_ 1900 Download_Status_ADCAM 0;
BA_ "GenSigTimeoutTime_ADCAM" SG_ 1900 Download_Status_ADCAM 0;
BA_ "GenSigTimeoutTime_RFHM" SG_ 1900 Big_ECU_Ready_ADCAM 0;
BA_ "GenSigTimeoutTime_MPAD" SG_ 1900 Big_ECU_Ready_ADCAM 0;
BA_ "GenSigTimeoutTime_IPC" SG_ 1900 Big_ECU_Ready_ADCAM 0;
BA_ "GenSigTimeoutTime_GNMM" SG_ 1900 Big_ECU_Ready_ADCAM 0;
BA_ "GenSigTimeoutTime_EVCU2" SG_ 1900 Big_ECU_Ready_ADCAM 0;
BA_ "GenSigTimeoutTime_ESL" SG_ 1900 Big_ECU_Ready_ADCAM 0;
BA_ "GenSigTimeoutTime_ECM" SG_ 1900 Big_ECU_Ready_ADCAM 0;
BA_ "GenSigTimeoutTime_DTCM" SG_ 1900 Big_ECU_Ready_ADCAM 0;
BA_ "GenSigTimeoutTime_DMSM" SG_ 1900 Big_ECU_Ready_ADCAM 0;
BA_ "GenSigTimeoutTime_BSM" SG_ 1900 Big_ECU_Ready_ADCAM 0;
BA_ "GenSigTimeoutTime_BCM" SG_ 1900 Big_ECU_Ready_ADCAM 0;
BA_ "GenSigTimeoutTime_AGSM" SG_ 1900 Big_ECU_Ready_ADCAM 0;
BA_ "GenSigTimeoutTime_ADCAM" SG_ 1900 Big_ECU_Ready_ADCAM 0;
BA_ "GenSigTimeoutTime_AGSM" SG_ 2654339283 CurrentCanNMState_FD09_NFCD 0;
BA_ "GenSigTimeoutTime_ADCAM" SG_ 2654339283 CurrentCanNMState_FD09_NFCD 0;
BA_ "GenSigTimeoutTime_RFHM" SG_ 2654339245 WakeupSource_FD03_MPAD 0;
BA_ "GenSigTimeoutTime_MPAD" SG_ 2654339245 WakeupSource_FD03_MPAD 0;
BA_ "GenSigTimeoutTime_IPC" SG_ 2654339245 WakeupSource_FD03_MPAD 0;
BA_ "GenSigTimeoutTime_GNMM" SG_ 2654339245 WakeupSource_FD03_MPAD 0;
BA_ "GenSigTimeoutTime_EVCU2" SG_ 2654339245 WakeupSource_FD03_MPAD 0;
BA_ "GenSigTimeoutTime_ESL" SG_ 2654339245 WakeupSource_FD03_MPAD 0;
BA_ "GenSigTimeoutTime_ECM" SG_ 2654339245 WakeupSource_FD03_MPAD 0;
BA_ "GenSigTimeoutTime_DTCM" SG_ 2654339245 WakeupSource_FD03_MPAD 0;
BA_ "GenSigTimeoutTime_DMSM" SG_ 2654339245 WakeupSource_FD03_MPAD 0;
BA_ "GenSigTimeoutTime_BSM" SG_ 2654339245 WakeupSource_FD03_MPAD 0;
BA_ "GenSigTimeoutTime_BCM" SG_ 2654339245 WakeupSource_FD03_MPAD 0;
BA_ "GenSigTimeoutTime_AGSM" SG_ 2654339245 WakeupSource_FD03_MPAD 0;
BA_ "GenSigTimeoutTime_ADCAM" SG_ 2654339245 WakeupSource_FD03_MPAD 0;
BA_ "GenSigTimeoutTime_RFHM" SG_ 2654339245 EOL_FD03_MPAD 0;
BA_ "GenSigTimeoutTime_MPAD" SG_ 2654339245 EOL_FD03_MPAD 0;
BA_ "GenSigTimeoutTime_IPC" SG_ 2654339245 EOL_FD03_MPAD 0;
BA_ "GenSigTimeoutTime_GNMM" SG_ 2654339245 EOL_FD03_MPAD 0;
BA_ "GenSigTimeoutTime_EVCU2" SG_ 2654339245 EOL_FD03_MPAD 0;
BA_ "GenSigTimeoutTime_ESL" SG_ 2654339245 EOL_FD03_MPAD 0;
BA_ "GenSigTimeoutTime_ECM" SG_ 2654339245 EOL_FD03_MPAD 0;
BA_ "GenSigTimeoutTime_DTCM" SG_ 2654339245 EOL_FD03_MPAD 0;
BA_ "GenSigTimeoutTime_DMSM" SG_ 2654339245 EOL_FD03_MPAD 0;
BA_ "GenSigTimeoutTime_BSM" SG_ 2654339245 EOL_FD03_MPAD 0;
BA_ "GenSigTimeoutTime_AGSM" SG_ 2654339245 EOL_FD03_MPAD 0;
BA_ "GenSigTimeoutTime_ADCAM" SG_ 2654339245 EOL_FD03_MPAD 0;
BA_ "GenSigTimeoutTime_RFHM" SG_ 2654339245 GenericFailSts_FD03_MPAD 0;
BA_ "GenSigTimeoutTime_MPAD" SG_ 2654339245 GenericFailSts_FD03_MPAD 0;
BA_ "GenSigTimeoutTime_IPC" SG_ 2654339245 GenericFailSts_FD03_MPAD 0;
BA_ "GenSigTimeoutTime_GNMM" SG_ 2654339245 GenericFailSts_FD03_MPAD 0;
BA_ "GenSigTimeoutTime_EVCU2" SG_ 2654339245 GenericFailSts_FD03_MPAD 0;
BA_ "GenSigTimeoutTime_ESL" SG_ 2654339245 GenericFailSts_FD03_MPAD 0;
BA_ "GenSigTimeoutTime_ECM" SG_ 2654339245 GenericFailSts_FD03_MPAD 0;
BA_ "GenSigTimeoutTime_DTCM" SG_ 2654339245 GenericFailSts_FD03_MPAD 0;
BA_ "GenSigTimeoutTime_DMSM" SG_ 2654339245 GenericFailSts_FD03_MPAD 0;
BA_ "GenSigTimeoutTime_BSM" SG_ 2654339245 GenericFailSts_FD03_MPAD 0;
BA_ "GenSigTimeoutTime_AGSM" SG_ 2654339245 GenericFailSts_FD03_MPAD 0;
BA_ "GenSigTimeoutTime_ADCAM" SG_ 2654339245 GenericFailSts_FD03_MPAD 0;
BA_ "GenSigTimeoutTime_RFHM" SG_ 2654339245 PreviousCanNMState_FD03_MPAD 0;
BA_ "GenSigTimeoutTime_MPAD" SG_ 2654339245 PreviousCanNMState_FD03_MPAD 0;
BA_ "GenSigTimeoutTime_IPC" SG_ 2654339245 PreviousCanNMState_FD03_MPAD 0;
BA_ "GenSigTimeoutTime_GNMM" SG_ 2654339245 PreviousCanNMState_FD03_MPAD 0;
BA_ "GenSigTimeoutTime_EVCU2" SG_ 2654339245 PreviousCanNMState_FD03_MPAD 0;
BA_ "GenSigTimeoutTime_ESL" SG_ 2654339245 PreviousCanNMState_FD03_MPAD 0;
BA_ "GenSigTimeoutTime_ECM" SG_ 2654339245 PreviousCanNMState_FD03_MPAD 0;
BA_ "GenSigTimeoutTime_DTCM" SG_ 2654339245 PreviousCanNMState_FD03_MPAD 0;
BA_ "GenSigTimeoutTime_DMSM" SG_ 2654339245 PreviousCanNMState_FD03_MPAD 0;
BA_ "GenSigTimeoutTime_BSM" SG_ 2654339245 PreviousCanNMState_FD03_MPAD 0;
BA_ "GenSigTimeoutTime_BCM" SG_ 2654339245 PreviousCanNMState_FD03_MPAD 0;
BA_ "GenSigTimeoutTime_AGSM" SG_ 2654339245 PreviousCanNMState_FD03_MPAD 0;
BA_ "GenSigTimeoutTime_ADCAM" SG_ 2654339245 PreviousCanNMState_FD03_MPAD 0;
BA_ "GenSigTimeoutTime_RFHM" SG_ 2654339245 StayActiveSource_FD03_MPAD 0;
BA_ "GenSigTimeoutTime_MPAD" SG_ 2654339245 StayActiveSource_FD03_MPAD 0;
BA_ "GenSigTimeoutTime_IPC" SG_ 2654339245 StayActiveSource_FD03_MPAD 0;
BA_ "GenSigTimeoutTime_GNMM" SG_ 2654339245 StayActiveSource_FD03_MPAD 0;
BA_ "GenSigTimeoutTime_EVCU2" SG_ 2654339245 StayActiveSource_FD03_MPAD 0;
BA_ "GenSigTimeoutTime_ESL" SG_ 2654339245 StayActiveSource_FD03_MPAD 0;
BA_ "GenSigTimeoutTime_ECM" SG_ 2654339245 StayActiveSource_FD03_MPAD 0;
BA_ "GenSigTimeoutTime_DTCM" SG_ 2654339245 StayActiveSource_FD03_MPAD 0;
BA_ "GenSigTimeoutTime_DMSM" SG_ 2654339245 StayActiveSource_FD03_MPAD 0;
BA_ "GenSigTimeoutTime_BSM" SG_ 2654339245 StayActiveSource_FD03_MPAD 0;
BA_ "GenSigTimeoutTime_BCM" SG_ 2654339245 StayActiveSource_FD03_MPAD 0;
BA_ "GenSigTimeoutTime_AGSM" SG_ 2654339245 StayActiveSource_FD03_MPAD 0;
BA_ "GenSigTimeoutTime_ADCAM" SG_ 2654339245 StayActiveSource_FD03_MPAD 0;
BA_ "GenSigTimeoutTime_RFHM" SG_ 2654339245 CurrentFailSts_FD03_MPAD 0;
BA_ "GenSigTimeoutTime_MPAD" SG_ 2654339245 CurrentFailSts_FD03_MPAD 0;
BA_ "GenSigTimeoutTime_IPC" SG_ 2654339245 CurrentFailSts_FD03_MPAD 0;
BA_ "GenSigTimeoutTime_GNMM" SG_ 2654339245 CurrentFailSts_FD03_MPAD 0;
BA_ "GenSigTimeoutTime_EVCU2" SG_ 2654339245 CurrentFailSts_FD03_MPAD 0;
BA_ "GenSigTimeoutTime_ESL" SG_ 2654339245 CurrentFailSts_FD03_MPAD 0;
BA_ "GenSigTimeoutTime_ECM" SG_ 2654339245 CurrentFailSts_FD03_MPAD 0;
BA_ "GenSigTimeoutTime_DTCM" SG_ 2654339245 CurrentFailSts_FD03_MPAD 0;
BA_ "GenSigTimeoutTime_DMSM" SG_ 2654339245 CurrentFailSts_FD03_MPAD 0;
BA_ "GenSigTimeoutTime_BSM" SG_ 2654339245 CurrentFailSts_FD03_MPAD 0;
BA_ "GenSigTimeoutTime_AGSM" SG_ 2654339245 CurrentFailSts_FD03_MPAD 0;
BA_ "GenSigTimeoutTime_ADCAM" SG_ 2654339245 CurrentFailSts_FD03_MPAD 0;
BA_ "GenSigTimeoutTime_RFHM" SG_ 2654339245 DES_FD03_MPAD 0;
BA_ "GenSigTimeoutTime_MPAD" SG_ 2654339245 DES_FD03_MPAD 0;
BA_ "GenSigTimeoutTime_IPC" SG_ 2654339245 DES_FD03_MPAD 0;
BA_ "GenSigTimeoutTime_GNMM" SG_ 2654339245 DES_FD03_MPAD 0;
BA_ "GenSigTimeoutTime_EVCU2" SG_ 2654339245 DES_FD03_MPAD 0;
BA_ "GenSigTimeoutTime_ESL" SG_ 2654339245 DES_FD03_MPAD 0;
BA_ "GenSigTimeoutTime_ECM" SG_ 2654339245 DES_FD03_MPAD 0;
BA_ "GenSigTimeoutTime_DTCM" SG_ 2654339245 DES_FD03_MPAD 0;
BA_ "GenSigTimeoutTime_DMSM" SG_ 2654339245 DES_FD03_MPAD 0;
BA_ "GenSigTimeoutTime_BSM" SG_ 2654339245 DES_FD03_MPAD 0;
BA_ "GenSigTimeoutTime_BCM" SG_ 2654339245 DES_FD03_MPAD 0;
BA_ "GenSigTimeoutTime_AGSM" SG_ 2654339245 DES_FD03_MPAD 0;
BA_ "GenSigTimeoutTime_ADCAM" SG_ 2654339245 DES_FD03_MPAD 0;
BA_ "GenSigTimeoutTime_SGW" SG_ 2651930835 Digit_05_NFCD 0;
BA_ "GenSigTimeoutTime_RFHM" SG_ 2651930835 Digit_05_NFCD 0;
BA_ "GenSigTimeoutTime_MPAD" SG_ 2651930835 Digit_05_NFCD 0;
BA_ "GenSigTimeoutTime_IPC" SG_ 2651930835 Digit_05_NFCD 0;
BA_ "GenSigTimeoutTime_GNMM" SG_ 2651930835 Digit_05_NFCD 0;
BA_ "GenSigTimeoutTime_EVCU2" SG_ 2651930835 Digit_05_NFCD 0;
BA_ "GenSigTimeoutTime_ESL" SG_ 2651930835 Digit_05_NFCD 0;
BA_ "GenSigTimeoutTime_ECM" SG_ 2651930835 Digit_05_NFCD 0;
BA_ "GenSigTimeoutTime_DTCM" SG_ 2651930835 Digit_05_NFCD 0;
BA_ "GenSigTimeoutTime_DMSM" SG_ 2651930835 Digit_05_NFCD 0;
BA_ "GenSigTimeoutTime_BSM" SG_ 2651930835 Digit_05_NFCD 0;
BA_ "GenSigTimeoutTime_AGSM" SG_ 2651930835 Digit_05_NFCD 0;
BA_ "GenSigTimeoutTime_SGW" SG_ 2651930835 Digit_06_NFCD 0;
BA_ "GenSigTimeoutTime_RFHM" SG_ 2651930835 Digit_06_NFCD 0;
BA_ "GenSigTimeoutTime_MPAD" SG_ 2651930835 Digit_06_NFCD 0;
BA_ "GenSigTimeoutTime_IPC" SG_ 2651930835 Digit_06_NFCD 0;
BA_ "GenSigTimeoutTime_GNMM" SG_ 2651930835 Digit_06_NFCD 0;
BA_ "GenSigTimeoutTime_EVCU2" SG_ 2651930835 Digit_06_NFCD 0;
BA_ "GenSigTimeoutTime_ESL" SG_ 2651930835 Digit_06_NFCD 0;
BA_ "GenSigTimeoutTime_ECM" SG_ 2651930835 Digit_06_NFCD 0;
BA_ "GenSigTimeoutTime_DTCM" SG_ 2651930835 Digit_06_NFCD 0;
BA_ "GenSigTimeoutTime_DMSM" SG_ 2651930835 Digit_06_NFCD 0;
BA_ "GenSigTimeoutTime_BSM" SG_ 2651930835 Digit_06_NFCD 0;
BA_ "GenSigTimeoutTime_AGSM" SG_ 2651930835 Digit_06_NFCD 0;
BA_ "GenSigTimeoutTime_ADCAM" SG_ 2651930835 Digit_06_NFCD 0;
BA_ "GenSigTimeoutTime_GNMM" SG_ 2651930835 Digit_07_NFCD 0;
BA_ "GenSigTimeoutTime_EVCU2" SG_ 2651930835 Digit_07_NFCD 0;
BA_ "GenSigTimeoutTime_ESL" SG_ 2651930835 Digit_07_NFCD 0;
BA_ "GenSigTimeoutTime_ECM" SG_ 2651930835 Digit_07_NFCD 0;
BA_ "GenSigTimeoutTime_DTCM" SG_ 2651930835 Digit_07_NFCD 0;
BA_ "GenSigTimeoutTime_DMSM" SG_ 2651930835 Digit_07_NFCD 0;
BA_ "GenSigTimeoutTime_BSM" SG_ 2651930835 Digit_07_NFCD 0;
BA_ "GenSigTimeoutTime_AGSM" SG_ 2651930835 Digit_07_NFCD 0;
BA_ "GenSigTimeoutTime_ADCAM" SG_ 2651930835 Digit_07_NFCD 0;
BA_ "GenSigTimeoutTime_SGW" SG_ 2651930835 Digit_07_NFCD 0;
BA_ "GenSigTimeoutTime_RFHM" SG_ 2651930835 Digit_07_NFCD 0;
BA_ "GenSigTimeoutTime_MPAD" SG_ 2651930835 Digit_07_NFCD 0;
BA_ "GenSigTimeoutTime_IPC" SG_ 2651930835 Digit_07_NFCD 0;
BA_ "GenSigTimeoutTime_SGW" SG_ 2651930835 Digit_08_NFCD 0;
BA_ "GenSigTimeoutTime_RFHM" SG_ 2651930835 Digit_08_NFCD 0;
BA_ "GenSigTimeoutTime_MPAD" SG_ 2651930835 Digit_08_NFCD 0;
BA_ "GenSigTimeoutTime_IPC" SG_ 2651930835 Digit_08_NFCD 0;
BA_ "GenSigTimeoutTime_GNMM" SG_ 2651930835 Digit_08_NFCD 0;
BA_ "GenSigTimeoutTime_EVCU2" SG_ 2651930835 Digit_08_NFCD 0;
BA_ "GenSigTimeoutTime_ESL" SG_ 2651930835 Digit_08_NFCD 0;
BA_ "GenSigTimeoutTime_ECM" SG_ 2651930835 Digit_08_NFCD 0;
BA_ "GenSigTimeoutTime_DTCM" SG_ 2651930835 Digit_08_NFCD 0;
BA_ "GenSigTimeoutTime_DMSM" SG_ 2651930835 Digit_08_NFCD 0;
BA_ "GenSigTimeoutTime_BSM" SG_ 2651930835 Digit_08_NFCD 0;
BA_ "GenSigTimeoutTime_AGSM" SG_ 2651930835 Digit_08_NFCD 0;
BA_ "GenSigTimeoutTime_ADCAM" SG_ 2651930835 Digit_08_NFCD 0;
BA_ "GenSigTimeoutTime_SGW" SG_ 2651930835 Digit_09_NFCD 0;
BA_ "GenSigTimeoutTime_RFHM" SG_ 2651930835 Digit_09_NFCD 0;
BA_ "GenSigTimeoutTime_MPAD" SG_ 2651930835 Digit_09_NFCD 0;
BA_ "GenSigTimeoutTime_IPC" SG_ 2651930835 Digit_09_NFCD 0;
BA_ "GenSigTimeoutTime_GNMM" SG_ 2651930835 Digit_09_NFCD 0;
BA_ "GenSigTimeoutTime_EVCU2" SG_ 2651930835 Digit_09_NFCD 0;
BA_ "GenSigTimeoutTime_ESL" SG_ 2651930835 Digit_09_NFCD 0;
BA_ "GenSigTimeoutTime_ECM" SG_ 2651930835 Digit_09_NFCD 0;
BA_ "GenSigTimeoutTime_DTCM" SG_ 2651930835 Digit_09_NFCD 0;
BA_ "GenSigTimeoutTime_DMSM" SG_ 2651930835 Digit_09_NFCD 0;
BA_ "GenSigTimeoutTime_BSM" SG_ 2651930835 Digit_09_NFCD 0;
BA_ "GenSigTimeoutTime_AGSM" SG_ 2651930835 Digit_09_NFCD 0;
BA_ "GenSigTimeoutTime_ADCAM" SG_ 2651930835 Digit_09_NFCD 0;
BA_ "GenSigTimeoutTime_SGW" SG_ 2651930835 Digit_10_NFCD 0;
BA_ "GenSigTimeoutTime_RFHM" SG_ 2651930835 Digit_10_NFCD 0;
BA_ "GenSigTimeoutTime_MPAD" SG_ 2651930835 Digit_10_NFCD 0;
BA_ "GenSigTimeoutTime_IPC" SG_ 2651930835 Digit_10_NFCD 0;
BA_ "GenSigTimeoutTime_GNMM" SG_ 2651930835 Digit_10_NFCD 0;
BA_ "GenSigTimeoutTime_EVCU2" SG_ 2651930835 Digit_10_NFCD 0;
BA_ "GenSigTimeoutTime_ESL" SG_ 2651930835 Digit_10_NFCD 0;
BA_ "GenSigTimeoutTime_ECM" SG_ 2651930835 Digit_10_NFCD 0;
BA_ "GenSigTimeoutTime_DTCM" SG_ 2651930835 Digit_10_NFCD 0;
BA_ "GenSigTimeoutTime_DMSM" SG_ 2651930835 Digit_10_NFCD 0;
BA_ "GenSigTimeoutTime_BSM" SG_ 2651930835 Digit_10_NFCD 0;
BA_ "GenSigTimeoutTime_AGSM" SG_ 2651930835 Digit_10_NFCD 0;
BA_ "GenSigTimeoutTime_ADCAM" SG_ 2651930835 Digit_10_NFCD 0;
BA_ "GenSigTimeoutTime_SGW" SG_ 2651930835 Digit_11_NFCD 0;
BA_ "GenSigTimeoutTime_RFHM" SG_ 2651930835 Digit_11_NFCD 0;
BA_ "GenSigTimeoutTime_MPAD" SG_ 2651930835 Digit_11_NFCD 0;
BA_ "GenSigTimeoutTime_IPC" SG_ 2651930835 Digit_11_NFCD 0;
BA_ "GenSigTimeoutTime_GNMM" SG_ 2651930835 Digit_11_NFCD 0;
BA_ "GenSigTimeoutTime_EVCU2" SG_ 2651930835 Digit_11_NFCD 0;
BA_ "GenSigTimeoutTime_ESL" SG_ 2651930835 Digit_11_NFCD 0;
BA_ "GenSigTimeoutTime_ECM" SG_ 2651930835 Digit_11_NFCD 0;
BA_ "GenSigTimeoutTime_DTCM" SG_ 2651930835 Digit_11_NFCD 0;
BA_ "GenSigTimeoutTime_DMSM" SG_ 2651930835 Digit_11_NFCD 0;
BA_ "GenSigTimeoutTime_BSM" SG_ 2651930835 Digit_11_NFCD 0;
BA_ "GenSigTimeoutTime_AGSM" SG_ 2651930835 Digit_11_NFCD 0;
BA_ "GenSigTimeoutTime_ADCAM" SG_ 2651930835 Digit_11_NFCD 0;
BA_ "GenSigTimeoutTime_RFHM" SG_ 2654339233 DES_FD03_ADCAM 0;
BA_ "GenSigTimeoutTime_MPAD" SG_ 2654339233 DES_FD03_ADCAM 0;
BA_ "GenSigTimeoutTime_IPC" SG_ 2654339233 DES_FD03_ADCAM 0;
BA_ "GenSigTimeoutTime_GNMM" SG_ 2654339233 DES_FD03_ADCAM 0;
BA_ "GenSigTimeoutTime_EVCU2" SG_ 2654339233 DES_FD03_ADCAM 0;
BA_ "GenSigTimeoutTime_ESL" SG_ 2654339233 DES_FD03_ADCAM 0;
BA_ "GenSigTimeoutTime_ECM" SG_ 2654339233 DES_FD03_ADCAM 0;
BA_ "GenSigTimeoutTime_DTCM" SG_ 2654339233 DES_FD03_ADCAM 0;
BA_ "GenSigTimeoutTime_DMSM" SG_ 2654339233 DES_FD03_ADCAM 0;
BA_ "GenSigTimeoutTime_BSM" SG_ 2654339233 DES_FD03_ADCAM 0;
BA_ "GenSigTimeoutTime_BCM" SG_ 2654339233 DES_FD03_ADCAM 0;
BA_ "GenSigTimeoutTime_AGSM" SG_ 2654339233 DES_FD03_ADCAM 0;
BA_ "GenSigTimeoutTime_ADCAM" SG_ 2654339233 DES_FD03_ADCAM 0;
BA_ "GenSigTimeoutTime_RFHM" SG_ 2654339233 CurrentFailSts_FD03_ADCAM 0;
BA_ "GenSigTimeoutTime_MPAD" SG_ 2654339233 CurrentFailSts_FD03_ADCAM 0;
BA_ "GenSigTimeoutTime_IPC" SG_ 2654339233 CurrentFailSts_FD03_ADCAM 0;
BA_ "GenSigTimeoutTime_GNMM" SG_ 2654339233 CurrentFailSts_FD03_ADCAM 0;
BA_ "GenSigTimeoutTime_EVCU2" SG_ 2654339233 CurrentFailSts_FD03_ADCAM 0;
BA_ "GenSigTimeoutTime_ESL" SG_ 2654339233 CurrentFailSts_FD03_ADCAM 0;
BA_ "GenSigTimeoutTime_ECM" SG_ 2654339233 CurrentFailSts_FD03_ADCAM 0;
BA_ "GenSigTimeoutTime_DTCM" SG_ 2654339233 CurrentFailSts_FD03_ADCAM 0;
BA_ "GenSigTimeoutTime_DMSM" SG_ 2654339233 CurrentFailSts_FD03_ADCAM 0;
BA_ "GenSigTimeoutTime_BSM" SG_ 2654339233 CurrentFailSts_FD03_ADCAM 0;
BA_ "GenSigTimeoutTime_AGSM" SG_ 2654339233 CurrentFailSts_FD03_ADCAM 0;
BA_ "GenSigTimeoutTime_ADCAM" SG_ 2654339233 CurrentFailSts_FD03_ADCAM 0;
BA_ "GenSigTimeoutTime_RFHM" SG_ 2654339233 CurrentCanNMState_FD03_ADCAM 0;
BA_ "GenSigTimeoutTime_MPAD" SG_ 2654339233 CurrentCanNMState_FD03_ADCAM 0;
BA_ "GenSigTimeoutTime_IPC" SG_ 2654339233 CurrentCanNMState_FD03_ADCAM 0;
BA_ "GenSigTimeoutTime_GNMM" SG_ 2654339233 CurrentCanNMState_FD03_ADCAM 0;
BA_ "GenSigTimeoutTime_EVCU2" SG_ 2654339233 CurrentCanNMState_FD03_ADCAM 0;
BA_ "GenSigTimeoutTime_ESL" SG_ 2654339233 CurrentCanNMState_FD03_ADCAM 0;
BA_ "GenSigTimeoutTime_ECM" SG_ 2654339233 CurrentCanNMState_FD03_ADCAM 0;
BA_ "GenSigTimeoutTime_DTCM" SG_ 2654339233 CurrentCanNMState_FD03_ADCAM 0;
BA_ "GenSigTimeoutTime_DMSM" SG_ 2654339233 CurrentCanNMState_FD03_ADCAM 0;
BA_ "GenSigTimeoutTime_BSM" SG_ 2654339233 CurrentCanNMState_FD03_ADCAM 0;
BA_ "GenSigTimeoutTime_BCM" SG_ 2654339233 CurrentCanNMState_FD03_ADCAM 0;
BA_ "GenSigTimeoutTime_AGSM" SG_ 2654339233 CurrentCanNMState_FD03_ADCAM 0;
BA_ "GenSigTimeoutTime_ADCAM" SG_ 2654339233 CurrentCanNMState_FD03_ADCAM 0;
BA_ "GenSigTimeoutTime_SGW" SG_ 2654486701 CBV_bit2 0;
BA_ "GenSigTimeoutTime_RFHM" SG_ 2654486701 CBV_bit2 0;
BA_ "GenSigTimeoutTime_MPAD" SG_ 2654486701 CBV_bit2 0;
BA_ "GenSigTimeoutTime_IPC" SG_ 2654486701 CBV_bit2 0;
BA_ "GenSigTimeoutTime_GNMM" SG_ 2654486701 CBV_bit2 0;
BA_ "GenSigTimeoutTime_EVCU2" SG_ 2654486701 CBV_bit2 0;
BA_ "GenSigTimeoutTime_ESL" SG_ 2654486701 CBV_bit2 0;
BA_ "GenSigTimeoutTime_ECM" SG_ 2654486701 CBV_bit2 0;
BA_ "GenSigTimeoutTime_DTCM" SG_ 2654486701 CBV_bit2 0;
BA_ "GenSigTimeoutTime_DMSM" SG_ 2654486701 CBV_bit2 0;
BA_ "GenSigTimeoutTime_BSM" SG_ 2654486701 CBV_bit2 0;
BA_ "GenSigTimeoutTime_BCM" SG_ 2654486701 CBV_bit2 0;
BA_ "GenSigTimeoutTime_AGSM" SG_ 2654486701 CBV_bit2 0;
BA_ "GenSigTimeoutTime_ADCAM" SG_ 2654486701 CBV_bit2 0;
BA_ "GenSigTimeoutTime_SGW" SG_ 2654486701 CBV_bit1 0;
BA_ "GenSigTimeoutTime_RFHM" SG_ 2654486701 CBV_bit1 0;
BA_ "GenSigTimeoutTime_MPAD" SG_ 2654486701 CBV_bit1 0;
BA_ "GenSigTimeoutTime_IPC" SG_ 2654486701 CBV_bit1 0;
BA_ "GenSigTimeoutTime_GNMM" SG_ 2654486701 CBV_bit1 0;
BA_ "GenSigTimeoutTime_EVCU2" SG_ 2654486701 CBV_bit1 0;
BA_ "GenSigTimeoutTime_ESL" SG_ 2654486701 CBV_bit1 0;
BA_ "GenSigTimeoutTime_ECM" SG_ 2654486701 CBV_bit1 0;
BA_ "GenSigTimeoutTime_DTCM" SG_ 2654486701 CBV_bit1 0;
BA_ "GenSigTimeoutTime_DMSM" SG_ 2654486701 CBV_bit1 0;
BA_ "GenSigTimeoutTime_BSM" SG_ 2654486701 CBV_bit1 0;
BA_ "GenSigTimeoutTime_BCM" SG_ 2654486701 CBV_bit1 0;
BA_ "GenSigTimeoutTime_AGSM" SG_ 2654486701 CBV_bit1 0;
BA_ "GenSigTimeoutTime_ADCAM" SG_ 2654486701 CBV_bit1 0;
BA_ "GenSigTimeoutTime_SGW" SG_ 2654486701 CBV_bit5 0;
BA_ "GenSigTimeoutTime_RFHM" SG_ 2654486701 CBV_bit5 0;
BA_ "GenSigTimeoutTime_MPAD" SG_ 2654486701 CBV_bit5 0;
BA_ "GenSigTimeoutTime_IPC" SG_ 2654486701 CBV_bit5 0;
BA_ "GenSigTimeoutTime_GNMM" SG_ 2654486701 CBV_bit5 0;
BA_ "GenSigTimeoutTime_EVCU2" SG_ 2654486701 CBV_bit5 0;
BA_ "GenSigTimeoutTime_ESL" SG_ 2654486701 CBV_bit5 0;
BA_ "GenSigTimeoutTime_ECM" SG_ 2654486701 CBV_bit5 0;
BA_ "GenSigTimeoutTime_DTCM" SG_ 2654486701 CBV_bit5 0;
BA_ "GenSigTimeoutTime_DMSM" SG_ 2654486701 CBV_bit5 0;
BA_ "GenSigTimeoutTime_BSM" SG_ 2654486701 CBV_bit5 0;
BA_ "GenSigTimeoutTime_BCM" SG_ 2654486701 CBV_bit5 0;
BA_ "GenSigTimeoutTime_AGSM" SG_ 2654486701 CBV_bit5 0;
BA_ "GenSigTimeoutTime_ADCAM" SG_ 2654486701 CBV_bit5 0;
BA_ "GenSigTimeoutTime_SGW" SG_ 2654486701 CBV_bit7 0;
BA_ "GenSigTimeoutTime_RFHM" SG_ 2654486701 CBV_bit7 0;
BA_ "GenSigTimeoutTime_MPAD" SG_ 2654486701 CBV_bit7 0;
BA_ "GenSigTimeoutTime_IPC" SG_ 2654486701 CBV_bit7 0;
BA_ "GenSigTimeoutTime_GNMM" SG_ 2654486701 CBV_bit7 0;
BA_ "GenSigTimeoutTime_EVCU2" SG_ 2654486701 CBV_bit7 0;
BA_ "GenSigTimeoutTime_ESL" SG_ 2654486701 CBV_bit7 0;
BA_ "GenSigTimeoutTime_ECM" SG_ 2654486701 CBV_bit7 0;
BA_ "GenSigTimeoutTime_DTCM" SG_ 2654486701 CBV_bit7 0;
BA_ "GenSigTimeoutTime_DMSM" SG_ 2654486701 CBV_bit7 0;
BA_ "GenSigTimeoutTime_BSM" SG_ 2654486701 CBV_bit7 0;
BA_ "GenSigTimeoutTime_BCM" SG_ 2654486701 CBV_bit7 0;
BA_ "GenSigTimeoutTime_AGSM" SG_ 2654486701 CBV_bit7 0;
BA_ "GenSigTimeoutTime_ADCAM" SG_ 2654486701 CBV_bit7 0;
BA_ "GenSigTimeoutTime_SGW" SG_ 2654486701 SourceNodeIdentifier 0;
BA_ "GenSigTimeoutTime_RFHM" SG_ 2654486701 SourceNodeIdentifier 0;
BA_ "GenSigTimeoutTime_MPAD" SG_ 2654486701 SourceNodeIdentifier 0;
BA_ "GenSigTimeoutTime_IPC" SG_ 2654486701 SourceNodeIdentifier 0;
BA_ "GenSigTimeoutTime_GNMM" SG_ 2654486701 SourceNodeIdentifier 0;
BA_ "GenSigTimeoutTime_EVCU2" SG_ 2654486701 SourceNodeIdentifier 0;
BA_ "GenSigTimeoutTime_ESL" SG_ 2654486701 SourceNodeIdentifier 0;
BA_ "GenSigTimeoutTime_ECM" SG_ 2654486701 SourceNodeIdentifier 0;
BA_ "GenSigTimeoutTime_DTCM" SG_ 2654486701 SourceNodeIdentifier 0;
BA_ "GenSigTimeoutTime_DMSM" SG_ 2654486701 SourceNodeIdentifier 0;
BA_ "GenSigTimeoutTime_BSM" SG_ 2654486701 SourceNodeIdentifier 0;
BA_ "GenSigTimeoutTime_BCM" SG_ 2654486701 SourceNodeIdentifier 0;
BA_ "GenSigTimeoutTime_AGSM" SG_ 2654486701 SourceNodeIdentifier 0;
BA_ "GenSigTimeoutTime_ADCAM" SG_ 2654486701 SourceNodeIdentifier 0;
BA_ "GenSigTimeoutTime_SGW" SG_ 2654486701 CBV_bit6_PartialNtwInfBit 0;
BA_ "GenSigTimeoutTime_RFHM" SG_ 2654486701 CBV_bit6_PartialNtwInfBit 0;
BA_ "GenSigTimeoutTime_MPAD" SG_ 2654486701 CBV_bit6_PartialNtwInfBit 0;
BA_ "GenSigTimeoutTime_IPC" SG_ 2654486701 CBV_bit6_PartialNtwInfBit 0;
BA_ "GenSigTimeoutTime_GNMM" SG_ 2654486701 CBV_bit6_PartialNtwInfBit 0;
BA_ "GenSigTimeoutTime_EVCU2" SG_ 2654486701 CBV_bit6_PartialNtwInfBit 0;
BA_ "GenSigTimeoutTime_ESL" SG_ 2654486701 CBV_bit6_PartialNtwInfBit 0;
BA_ "GenSigTimeoutTime_ECM" SG_ 2654486701 CBV_bit6_PartialNtwInfBit 0;
BA_ "GenSigTimeoutTime_DTCM" SG_ 2654486701 CBV_bit6_PartialNtwInfBit 0;
BA_ "GenSigTimeoutTime_DMSM" SG_ 2654486701 CBV_bit6_PartialNtwInfBit 0;
BA_ "GenSigTimeoutTime_BSM" SG_ 2654486701 CBV_bit6_PartialNtwInfBit 0;
BA_ "GenSigTimeoutTime_BCM" SG_ 2654486701 CBV_bit6_PartialNtwInfBit 0;
BA_ "GenSigTimeoutTime_AGSM" SG_ 2654486701 CBV_bit6_PartialNtwInfBit 0;
BA_ "GenSigTimeoutTime_ADCAM" SG_ 2654486701 CBV_bit6_PartialNtwInfBit 0;
BA_ "GenSigTimeoutTime_SGW" SG_ 2654486701 CBV_bit4_ActiveWakeupBit 0;
BA_ "GenSigTimeoutTime_RFHM" SG_ 2654486701 CBV_bit4_ActiveWakeupBit 0;
BA_ "GenSigTimeoutTime_MPAD" SG_ 2654486701 CBV_bit4_ActiveWakeupBit 0;
BA_ "GenSigTimeoutTime_IPC" SG_ 2654486701 CBV_bit4_ActiveWakeupBit 0;
BA_ "GenSigTimeoutTime_GNMM" SG_ 2654486701 CBV_bit4_ActiveWakeupBit 0;
BA_ "GenSigTimeoutTime_EVCU2" SG_ 2654486701 CBV_bit4_ActiveWakeupBit 0;
BA_ "GenSigTimeoutTime_ESL" SG_ 2654486701 CBV_bit4_ActiveWakeupBit 0;
BA_ "GenSigTimeoutTime_ECM" SG_ 2654486701 CBV_bit4_ActiveWakeupBit 0;
BA_ "GenSigTimeoutTime_DTCM" SG_ 2654486701 CBV_bit4_ActiveWakeupBit 0;
BA_ "GenSigTimeoutTime_DMSM" SG_ 2654486701 CBV_bit4_ActiveWakeupBit 0;
BA_ "GenSigTimeoutTime_BSM" SG_ 2654486701 CBV_bit4_ActiveWakeupBit 0;
BA_ "GenSigTimeoutTime_BCM" SG_ 2654486701 CBV_bit4_ActiveWakeupBit 0;
BA_ "GenSigTimeoutTime_AGSM" SG_ 2654486701 CBV_bit4_ActiveWakeupBit 0;
BA_ "GenSigTimeoutTime_ADCAM" SG_ 2654486701 CBV_bit4_ActiveWakeupBit 0;
BA_ "GenSigTimeoutTime_SGW" SG_ 2654486701 CBV_bit3_NMCoordinatorBit 0;
BA_ "GenSigTimeoutTime_RFHM" SG_ 2654486701 CBV_bit3_NMCoordinatorBit 0;
BA_ "GenSigTimeoutTime_MPAD" SG_ 2654486701 CBV_bit3_NMCoordinatorBit 0;
BA_ "GenSigTimeoutTime_IPC" SG_ 2654486701 CBV_bit3_NMCoordinatorBit 0;
BA_ "GenSigTimeoutTime_GNMM" SG_ 2654486701 CBV_bit3_NMCoordinatorBit 0;
BA_ "GenSigTimeoutTime_EVCU2" SG_ 2654486701 CBV_bit3_NMCoordinatorBit 0;
BA_ "GenSigTimeoutTime_ESL" SG_ 2654486701 CBV_bit3_NMCoordinatorBit 0;
BA_ "GenSigTimeoutTime_ECM" SG_ 2654486701 CBV_bit3_NMCoordinatorBit 0;
BA_ "GenSigTimeoutTime_DTCM" SG_ 2654486701 CBV_bit3_NMCoordinatorBit 0;
BA_ "GenSigTimeoutTime_DMSM" SG_ 2654486701 CBV_bit3_NMCoordinatorBit 0;
BA_ "GenSigTimeoutTime_BSM" SG_ 2654486701 CBV_bit3_NMCoordinatorBit 0;
BA_ "GenSigTimeoutTime_BCM" SG_ 2654486701 CBV_bit3_NMCoordinatorBit 0;
BA_ "GenSigTimeoutTime_AGSM" SG_ 2654486701 CBV_bit3_NMCoordinatorBit 0;
BA_ "GenSigTimeoutTime_ADCAM" SG_ 2654486701 CBV_bit3_NMCoordinatorBit 0;
BA_ "GenSigTimeoutTime_SGW" SG_ 2654486701 CBV_bit0_RepeatMessageRequestBit 0;
BA_ "GenSigTimeoutTime_RFHM" SG_ 2654486701 CBV_bit0_RepeatMessageRequestBit 0;
BA_ "GenSigTimeoutTime_MPAD" SG_ 2654486701 CBV_bit0_RepeatMessageRequestBit 0;
BA_ "GenSigTimeoutTime_IPC" SG_ 2654486701 CBV_bit0_RepeatMessageRequestBit 0;
BA_ "GenSigTimeoutTime_GNMM" SG_ 2654486701 CBV_bit0_RepeatMessageRequestBit 0;
BA_ "GenSigTimeoutTime_EVCU2" SG_ 2654486701 CBV_bit0_RepeatMessageRequestBit 0;
BA_ "GenSigTimeoutTime_ESL" SG_ 2654486701 CBV_bit0_RepeatMessageRequestBit 0;
BA_ "GenSigTimeoutTime_ECM" SG_ 2654486701 CBV_bit0_RepeatMessageRequestBit 0;
BA_ "GenSigTimeoutTime_DTCM" SG_ 2654486701 CBV_bit0_RepeatMessageRequestBit 0;
BA_ "GenSigTimeoutTime_DMSM" SG_ 2654486701 CBV_bit0_RepeatMessageRequestBit 0;
BA_ "GenSigTimeoutTime_BSM" SG_ 2654486701 CBV_bit0_RepeatMessageRequestBit 0;
BA_ "GenSigTimeoutTime_BCM" SG_ 2654486701 CBV_bit0_RepeatMessageRequestBit 0;
BA_ "GenSigTimeoutTime_AGSM" SG_ 2654486701 CBV_bit0_RepeatMessageRequestBit 0;
BA_ "GenSigTimeoutTime_ADCAM" SG_ 2654486701 CBV_bit0_RepeatMessageRequestBit 0;
BA_ "GenSigTimeoutTime_RFHM" SG_ 2654339160 PreviousCanNMState_FD16_MCPA 0;
BA_ "GenSigTimeoutTime_MPAD" SG_ 2654339160 PreviousCanNMState_FD16_MCPA 0;
BA_ "GenSigTimeoutTime_IPC" SG_ 2654339160 PreviousCanNMState_FD16_MCPA 0;
BA_ "GenSigTimeoutTime_GNMM" SG_ 2654339160 PreviousCanNMState_FD16_MCPA 0;
BA_ "GenSigTimeoutTime_EVCU2" SG_ 2654339160 PreviousCanNMState_FD16_MCPA 0;
BA_ "GenSigTimeoutTime_ESL" SG_ 2654339160 PreviousCanNMState_FD16_MCPA 0;
BA_ "GenSigTimeoutTime_ECM" SG_ 2654339160 PreviousCanNMState_FD16_MCPA 0;
BA_ "GenSigTimeoutTime_DTCM" SG_ 2654339160 PreviousCanNMState_FD16_MCPA 0;
BA_ "GenSigTimeoutTime_DMSM" SG_ 2654339160 PreviousCanNMState_FD16_MCPA 0;
BA_ "GenSigTimeoutTime_BSM" SG_ 2654339160 PreviousCanNMState_FD16_MCPA 0;
BA_ "GenSigTimeoutTime_BCM" SG_ 2654339160 PreviousCanNMState_FD16_MCPA 0;
BA_ "GenSigTimeoutTime_AGSM" SG_ 2654339160 PreviousCanNMState_FD16_MCPA 0;
BA_ "GenSigTimeoutTime_ADCAM" SG_ 2654339160 PreviousCanNMState_FD16_MCPA 0;
BA_ "GenSigTimeoutTime_RFHM" SG_ 2654339160 PreviousCanNMState_FD05_MCPA 0;
BA_ "GenSigTimeoutTime_MPAD" SG_ 2654339160 PreviousCanNMState_FD05_MCPA 0;
BA_ "GenSigTimeoutTime_IPC" SG_ 2654339160 PreviousCanNMState_FD05_MCPA 0;
BA_ "GenSigTimeoutTime_GNMM" SG_ 2654339160 PreviousCanNMState_FD05_MCPA 0;
BA_ "GenSigTimeoutTime_EVCU2" SG_ 2654339160 PreviousCanNMState_FD05_MCPA 0;
BA_ "GenSigTimeoutTime_ESL" SG_ 2654339160 PreviousCanNMState_FD05_MCPA 0;
BA_ "GenSigTimeoutTime_ECM" SG_ 2654339160 PreviousCanNMState_FD05_MCPA 0;
BA_ "GenSigTimeoutTime_DTCM" SG_ 2654339160 PreviousCanNMState_FD05_MCPA 0;
BA_ "GenSigTimeoutTime_DMSM" SG_ 2654339160 PreviousCanNMState_FD05_MCPA 0;
BA_ "GenSigTimeoutTime_BSM" SG_ 2654339160 PreviousCanNMState_FD05_MCPA 0;
BA_ "GenSigTimeoutTime_BCM" SG_ 2654339160 PreviousCanNMState_FD05_MCPA 0;
BA_ "GenSigTimeoutTime_AGSM" SG_ 2654339160 PreviousCanNMState_FD05_MCPA 0;
BA_ "GenSigTimeoutTime_ADCAM" SG_ 2654339160 PreviousCanNMState_FD05_MCPA 0;
BA_ "GenSigTimeoutTime_RFHM" SG_ 2654339160 GenericFailSts_FD16_MCPA 0;
BA_ "GenSigTimeoutTime_MPAD" SG_ 2654339160 GenericFailSts_FD16_MCPA 0;
BA_ "GenSigTimeoutTime_IPC" SG_ 2654339160 GenericFailSts_FD16_MCPA 0;
BA_ "GenSigTimeoutTime_GNMM" SG_ 2654339160 GenericFailSts_FD16_MCPA 0;
BA_ "GenSigTimeoutTime_EVCU2" SG_ 2654339160 GenericFailSts_FD16_MCPA 0;
BA_ "GenSigTimeoutTime_ESL" SG_ 2654339160 GenericFailSts_FD16_MCPA 0;
BA_ "GenSigTimeoutTime_ECM" SG_ 2654339160 GenericFailSts_FD16_MCPA 0;
BA_ "GenSigTimeoutTime_DTCM" SG_ 2654339160 GenericFailSts_FD16_MCPA 0;
BA_ "GenSigTimeoutTime_DMSM" SG_ 2654339160 GenericFailSts_FD16_MCPA 0;
BA_ "GenSigTimeoutTime_BSM" SG_ 2654339160 GenericFailSts_FD16_MCPA 0;
BA_ "GenSigTimeoutTime_BCM" SG_ 2654339160 GenericFailSts_FD16_MCPA 0;
BA_ "GenSigTimeoutTime_AGSM" SG_ 2654339160 GenericFailSts_FD16_MCPA 0;
BA_ "GenSigTimeoutTime_ADCAM" SG_ 2654339160 GenericFailSts_FD16_MCPA 0;
BA_ "GenSigTimeoutTime_RFHM" SG_ 2654339160 GenericFailSts_FD05_MCPA 0;
BA_ "GenSigTimeoutTime_MPAD" SG_ 2654339160 GenericFailSts_FD05_MCPA 0;
BA_ "GenSigTimeoutTime_IPC" SG_ 2654339160 GenericFailSts_FD05_MCPA 0;
BA_ "GenSigTimeoutTime_GNMM" SG_ 2654339160 GenericFailSts_FD05_MCPA 0;
BA_ "GenSigTimeoutTime_EVCU2" SG_ 2654339160 GenericFailSts_FD05_MCPA 0;
BA_ "GenSigTimeoutTime_ESL" SG_ 2654339160 GenericFailSts_FD05_MCPA 0;
BA_ "GenSigTimeoutTime_ECM" SG_ 2654339160 GenericFailSts_FD05_MCPA 0;
BA_ "GenSigTimeoutTime_DTCM" SG_ 2654339160 GenericFailSts_FD05_MCPA 0;
BA_ "GenSigTimeoutTime_DMSM" SG_ 2654339160 GenericFailSts_FD05_MCPA 0;
BA_ "GenSigTimeoutTime_BSM" SG_ 2654339160 GenericFailSts_FD05_MCPA 0;
BA_ "GenSigTimeoutTime_AGSM" SG_ 2654339160 GenericFailSts_FD05_MCPA 0;
BA_ "GenSigTimeoutTime_ADCAM" SG_ 2654339160 GenericFailSts_FD05_MCPA 0;
BA_ "GenSigTimeoutTime_RFHM" SG_ 2654339160 EOL_FD16_MCPA 0;
BA_ "GenSigTimeoutTime_MPAD" SG_ 2654339160 EOL_FD16_MCPA 0;
BA_ "GenSigTimeoutTime_IPC" SG_ 2654339160 EOL_FD16_MCPA 0;
BA_ "GenSigTimeoutTime_GNMM" SG_ 2654339160 EOL_FD16_MCPA 0;
BA_ "GenSigTimeoutTime_EVCU2" SG_ 2654339160 EOL_FD16_MCPA 0;
BA_ "GenSigTimeoutTime_ESL" SG_ 2654339160 EOL_FD16_MCPA 0;
BA_ "GenSigTimeoutTime_ECM" SG_ 2654339160 EOL_FD16_MCPA 0;
BA_ "GenSigTimeoutTime_DTCM" SG_ 2654339160 EOL_FD16_MCPA 0;
BA_ "GenSigTimeoutTime_DMSM" SG_ 2654339160 EOL_FD16_MCPA 0;
BA_ "GenSigTimeoutTime_BSM" SG_ 2654339160 EOL_FD16_MCPA 0;
BA_ "GenSigTimeoutTime_BCM" SG_ 2654339160 EOL_FD16_MCPA 0;
BA_ "GenSigTimeoutTime_AGSM" SG_ 2654339160 EOL_FD16_MCPA 0;
BA_ "GenSigTimeoutTime_ADCAM" SG_ 2654339160 EOL_FD16_MCPA 0;
BA_ "GenSigTimeoutTime_RFHM" SG_ 2654339160 EOL_FD05_MCPA 0;
BA_ "GenSigTimeoutTime_MPAD" SG_ 2654339160 EOL_FD05_MCPA 0;
BA_ "GenSigTimeoutTime_IPC" SG_ 2654339160 EOL_FD05_MCPA 0;
BA_ "GenSigTimeoutTime_GNMM" SG_ 2654339160 EOL_FD05_MCPA 0;
BA_ "GenSigTimeoutTime_EVCU2" SG_ 2654339160 EOL_FD05_MCPA 0;
BA_ "GenSigTimeoutTime_ESL" SG_ 2654339160 EOL_FD05_MCPA 0;
BA_ "GenSigTimeoutTime_ECM" SG_ 2654339160 EOL_FD05_MCPA 0;
BA_ "GenSigTimeoutTime_DTCM" SG_ 2654339160 EOL_FD05_MCPA 0;
BA_ "GenSigTimeoutTime_DMSM" SG_ 2654339160 EOL_FD05_MCPA 0;
BA_ "GenSigTimeoutTime_BSM" SG_ 2654339160 EOL_FD05_MCPA 0;
BA_ "GenSigTimeoutTime_AGSM" SG_ 2654339160 EOL_FD05_MCPA 0;
BA_ "GenSigTimeoutTime_ADCAM" SG_ 2654339160 EOL_FD05_MCPA 0;
BA_ "GenSigTimeoutTime_RFHM" SG_ 2654339160 DES_FD16_MCPA 0;
BA_ "GenSigTimeoutTime_MPAD" SG_ 2654339160 DES_FD16_MCPA 0;
BA_ "GenSigTimeoutTime_IPC" SG_ 2654339160 DES_FD16_MCPA 0;
BA_ "GenSigTimeoutTime_GNMM" SG_ 2654339160 DES_FD16_MCPA 0;
BA_ "GenSigTimeoutTime_EVCU2" SG_ 2654339160 DES_FD16_MCPA 0;
BA_ "GenSigTimeoutTime_ESL" SG_ 2654339160 DES_FD16_MCPA 0;
BA_ "GenSigTimeoutTime_ECM" SG_ 2654339160 DES_FD16_MCPA 0;
BA_ "GenSigTimeoutTime_DTCM" SG_ 2654339160 DES_FD16_MCPA 0;
BA_ "GenSigTimeoutTime_DMSM" SG_ 2654339160 DES_FD16_MCPA 0;
BA_ "GenSigTimeoutTime_BSM" SG_ 2654339160 DES_FD16_MCPA 0;
BA_ "GenSigTimeoutTime_BCM" SG_ 2654339160 DES_FD16_MCPA 0;
BA_ "GenSigTimeoutTime_AGSM" SG_ 2654339160 DES_FD16_MCPA 0;
BA_ "GenSigTimeoutTime_ADCAM" SG_ 2654339160 DES_FD16_MCPA 0;
BA_ "GenSigTimeoutTime_RFHM" SG_ 2654339160 DES_FD05_MCPA 0;
BA_ "GenSigTimeoutTime_MPAD" SG_ 2654339160 DES_FD05_MCPA 0;
BA_ "GenSigTimeoutTime_IPC" SG_ 2654339160 DES_FD05_MCPA 0;
BA_ "GenSigTimeoutTime_GNMM" SG_ 2654339160 DES_FD05_MCPA 0;
BA_ "GenSigTimeoutTime_EVCU2" SG_ 2654339160 DES_FD05_MCPA 0;
BA_ "GenSigTimeoutTime_ESL" SG_ 2654339160 DES_FD05_MCPA 0;
BA_ "GenSigTimeoutTime_ECM" SG_ 2654339160 DES_FD05_MCPA 0;
BA_ "GenSigTimeoutTime_DTCM" SG_ 2654339160 DES_FD05_MCPA 0;
BA_ "GenSigTimeoutTime_DMSM" SG_ 2654339160 DES_FD05_MCPA 0;
BA_ "GenSigTimeoutTime_BSM" SG_ 2654339160 DES_FD05_MCPA 0;
BA_ "GenSigTimeoutTime_BCM" SG_ 2654339160 DES_FD05_MCPA 0;
BA_ "GenSigTimeoutTime_AGSM" SG_ 2654339160 DES_FD05_MCPA 0;
BA_ "GenSigTimeoutTime_ADCAM" SG_ 2654339160 DES_FD05_MCPA 0;
BA_ "GenSigTimeoutTime_RFHM" SG_ 2654339160 CurrentFailSts_FD16_MCPA 0;
BA_ "GenSigTimeoutTime_MPAD" SG_ 2654339160 CurrentFailSts_FD16_MCPA 0;
BA_ "GenSigTimeoutTime_IPC" SG_ 2654339160 CurrentFailSts_FD16_MCPA 0;
BA_ "GenSigTimeoutTime_GNMM" SG_ 2654339160 CurrentFailSts_FD16_MCPA 0;
BA_ "GenSigTimeoutTime_EVCU2" SG_ 2654339160 CurrentFailSts_FD16_MCPA 0;
BA_ "GenSigTimeoutTime_ESL" SG_ 2654339160 CurrentFailSts_FD16_MCPA 0;
BA_ "GenSigTimeoutTime_ECM" SG_ 2654339160 CurrentFailSts_FD16_MCPA 0;
BA_ "GenSigTimeoutTime_DTCM" SG_ 2654339160 CurrentFailSts_FD16_MCPA 0;
BA_ "GenSigTimeoutTime_DMSM" SG_ 2654339160 CurrentFailSts_FD16_MCPA 0;
BA_ "GenSigTimeoutTime_BSM" SG_ 2654339160 CurrentFailSts_FD16_MCPA 0;
BA_ "GenSigTimeoutTime_BCM" SG_ 2654339160 CurrentFailSts_FD16_MCPA 0;
BA_ "GenSigTimeoutTime_AGSM" SG_ 2654339160 CurrentFailSts_FD16_MCPA 0;
BA_ "GenSigTimeoutTime_ADCAM" SG_ 2654339160 CurrentFailSts_FD16_MCPA 0;
BA_ "GenSigTimeoutTime_RFHM" SG_ 2654339160 CurrentFailSts_FD05_MCPA 0;
BA_ "GenSigTimeoutTime_MPAD" SG_ 2654339160 CurrentFailSts_FD05_MCPA 0;
BA_ "GenSigTimeoutTime_IPC" SG_ 2654339160 CurrentFailSts_FD05_MCPA 0;
BA_ "GenSigTimeoutTime_GNMM" SG_ 2654339160 CurrentFailSts_FD05_MCPA 0;
BA_ "GenSigTimeoutTime_EVCU2" SG_ 2654339160 CurrentFailSts_FD05_MCPA 0;
BA_ "GenSigTimeoutTime_ESL" SG_ 2654339160 CurrentFailSts_FD05_MCPA 0;
BA_ "GenSigTimeoutTime_ECM" SG_ 2654339160 CurrentFailSts_FD05_MCPA 0;
BA_ "GenSigTimeoutTime_DTCM" SG_ 2654339160 CurrentFailSts_FD05_MCPA 0;
BA_ "GenSigTimeoutTime_DMSM" SG_ 2654339160 CurrentFailSts_FD05_MCPA 0;
BA_ "GenSigTimeoutTime_BSM" SG_ 2654339160 CurrentFailSts_FD05_MCPA 0;
BA_ "GenSigTimeoutTime_AGSM" SG_ 2654339160 CurrentFailSts_FD05_MCPA 0;
BA_ "GenSigTimeoutTime_ADCAM" SG_ 2654339160 CurrentFailSts_FD05_MCPA 0;
BA_ "GenSigTimeoutTime_RFHM" SG_ 2654339160 CurrentCanNMState_FD16_MCPA 0;
BA_ "GenSigTimeoutTime_MPAD" SG_ 2654339160 CurrentCanNMState_FD16_MCPA 0;
BA_ "GenSigTimeoutTime_IPC" SG_ 2654339160 CurrentCanNMState_FD16_MCPA 0;
BA_ "GenSigTimeoutTime_GNMM" SG_ 2654339160 CurrentCanNMState_FD16_MCPA 0;
BA_ "GenSigTimeoutTime_EVCU2" SG_ 2654339160 CurrentCanNMState_FD16_MCPA 0;
BA_ "GenSigTimeoutTime_ESL" SG_ 2654339160 CurrentCanNMState_FD16_MCPA 0;
BA_ "GenSigTimeoutTime_ECM" SG_ 2654339160 CurrentCanNMState_FD16_MCPA 0;
BA_ "GenSigTimeoutTime_DTCM" SG_ 2654339160 CurrentCanNMState_FD16_MCPA 0;
BA_ "GenSigTimeoutTime_DMSM" SG_ 2654339160 CurrentCanNMState_FD16_MCPA 0;
BA_ "GenSigTimeoutTime_BSM" SG_ 2654339160 CurrentCanNMState_FD16_MCPA 0;
BA_ "GenSigTimeoutTime_BCM" SG_ 2654339160 CurrentCanNMState_FD16_MCPA 0;
BA_ "GenSigTimeoutTime_AGSM" SG_ 2654339160 CurrentCanNMState_FD16_MCPA 0;
BA_ "GenSigTimeoutTime_ADCAM" SG_ 2654339160 CurrentCanNMState_FD16_MCPA 0;
BA_ "GenSigTimeoutTime_RFHM" SG_ 2654339160 CurrentCanNMState_FD05_MCPA 0;
BA_ "GenSigTimeoutTime_MPAD" SG_ 2654339160 CurrentCanNMState_FD05_MCPA 0;
BA_ "GenSigTimeoutTime_IPC" SG_ 2654339160 CurrentCanNMState_FD05_MCPA 0;
BA_ "GenSigTimeoutTime_GNMM" SG_ 2654339160 CurrentCanNMState_FD05_MCPA 0;
BA_ "GenSigTimeoutTime_EVCU2" SG_ 2654339160 CurrentCanNMState_FD05_MCPA 0;
BA_ "GenSigTimeoutTime_ESL" SG_ 2654339160 CurrentCanNMState_FD05_MCPA 0;
BA_ "GenSigTimeoutTime_ECM" SG_ 2654339160 CurrentCanNMState_FD05_MCPA 0;
BA_ "GenSigTimeoutTime_DTCM" SG_ 2654339160 CurrentCanNMState_FD05_MCPA 0;
BA_ "GenSigTimeoutTime_DMSM" SG_ 2654339160 CurrentCanNMState_FD05_MCPA 0;
BA_ "GenSigTimeoutTime_BSM" SG_ 2654339160 CurrentCanNMState_FD05_MCPA 0;
BA_ "GenSigTimeoutTime_BCM" SG_ 2654339160 CurrentCanNMState_FD05_MCPA 0;
BA_ "GenSigTimeoutTime_AGSM" SG_ 2654339160 CurrentCanNMState_FD05_MCPA 0;
BA_ "GenSigTimeoutTime_ADCAM" SG_ 2654339160 CurrentCanNMState_FD05_MCPA 0;
VAL_ 145 E_Coasting_Req 1 "Level_1" 2 "Level_2" 3 "Level_3" 4 "Level_4" 5 "Level_5" 7 "SNA";
VAL_ 145 Creep_Req 0 "Off" 1 "On";
VAL_ 2654339283 WakeupSource_FD09_NFCD 0 "No_Wakeup" 1 "IGN_ON" 129 "FD1_Psv_WU" 130 "FD2_Psv_WU" 131 "FD3_Psv_WU" 132 "FD4_Psv_WU" 133 "FD5_Psv_WU" 134 "FD6_Psv_WU" 135 "FD7_Psv_WU" 136 "FD8_Psv_WU" 137 "FD9_Psv_WU" 138 "FD10_Psv_WU" 139 "FD11_Psv_WU" 140 "FD12_Psv_WU" 141 "FD13_Psv_WU" 142 "FD14_Psv_WU" 143 "FD15_Psv_WU" 144 "FD16_Psv_WU" 145 "FD17_Psv_WU" 146 "FD18_Psv_WU" 147 "FD19_Psv_WU" 148 "FD20_Psv_WU" 149 "FD21_Psv_WU" 150 "FD22_Psv_WU" 151 "FD23_Psv_WU" 152 "FD24_Psv_WU" 153 "FD25_Psv_WU" 154 "FD26_Psv_WU" 155 "FD27_Psv_WU" 156 "FD28_Psv_WU" 157 "FD29_Psv_WU" 158 "BHCAN_Psv_WU" 159 "CCAN_Psv_WU" 254 "WUSource_Not_Listed";
VAL_ 2654339283 StayActiveSource_FD09_NFCD 0 "CANNM_Ready_Sleep" 1 "IGN_ON" 2 "NonDefault_Diag" 4 "ING_OFF_NormSt_RptSt" 1073741824 "SASource_Not_Listed";
VAL_ 2654339283 PreviousCanNMState_FD09_NFCD 0 "Uninitialized State" 1 "Bus-Sleep State" 2 "Prepare-Bus State" 3 "Ready-Sleep State" 4 "Normal Operation State" 5 "Repeat Message State" 6 "Synchronize State" 7 "Offline State";
VAL_ 2654339283 GenericFailSts_FD09_NFCD 0 "No_Fail_Present" 1 "Fail_Present";
VAL_ 2654339283 EOL_FD09_NFCD 0 "No_EOL_Programming" 1 "EOL_Programming";
VAL_ 2654339283 DES_FD09_NFCD 0 "Error_Active_state" 1 "Error_passive_warning_state" 2 "Bus_off_state" 3 "Not_used";
VAL_ 2654339283 CurrentFailSts_FD09_NFCD 0 "No_Fail_Present" 1 "Fail_Present";
VAL_ 2654339283 CurrentCanNMState_FD09_NFCD 0 "Uninitialized State" 1 "Bus-Sleep State" 2 "Prepare-Bus State" 3 "Ready-Sleep State" 4 "Normal Operation State" 5 "Repeat Message State" 6 "Synchronize State" 7 "Offline State";
VAL_ 2654339245 WakeupSource_FD03_MPAD 0 "No_Wakeup" 1 "IGN_ON" 129 "FD1_Psv_WU" 130 "FD2_Psv_WU" 131 "FD3_Psv_WU" 132 "FD4_Psv_WU" 133 "FD5_Psv_WU" 134 "FD6_Psv_WU" 135 "FD7_Psv_WU" 136 "FD8_Psv_WU" 137 "FD9_Psv_WU" 138 "FD10_Psv_WU" 139 "FD11_Psv_WU" 140 "FD12_Psv_WU" 141 "FD13_Psv_WU" 142 "FD14_Psv_WU" 143 "FD15_Psv_WU" 144 "FD16_Psv_WU" 145 "FD17_Psv_WU" 146 "FD18_Psv_WU" 147 "FD19_Psv_WU" 148 "FD20_Psv_WU" 149 "FD21_Psv_WU" 150 "FD22_Psv_WU" 151 "FD23_Psv_WU" 152 "FD24_Psv_WU" 153 "FD25_Psv_WU" 154 "FD26_Psv_WU" 155 "FD27_Psv_WU" 156 "FD28_Psv_WU" 157 "FD29_Psv_WU" 158 "BHCAN_Psv_WU" 159 "CCAN_Psv_WU" 254 "WUSource_Not_Listed";
VAL_ 2654339245 StayActiveSource_FD03_MPAD 0 "CANNM_Ready_Sleep" 1 "IGN_ON" 2 "NonDefault_Diag" 4 "ING_OFF_NormSt_RptSt" 1073741824 "SASource_Not_Listed";
VAL_ 2654339245 PreviousCanNMState_FD03_MPAD 0 "Uninitialized_State" 1 "Bus_Sleep_State" 2 "Prepare_Bus_State" 3 "Ready_Sleep_State" 4 "Normal_Operation_State" 5 "Repeat_Message_State" 6 "Synchronize_State" 7 "Offline_State";
VAL_ 2654339245 GenericFailSts_FD03_MPAD 0 "No_Fail_Present" 1 "Fail_Present";
VAL_ 2654339245 EOL_FD03_MPAD 0 "No_EOL_Programming" 1 "EOL_Programming";
VAL_ 2654339245 DES_FD03_MPAD 0 "Error_Active_state" 1 "Error_passive_warning_state" 2 "Bus_off_state" 3 "Not_used";
VAL_ 2654339245 CurrentFailSts_FD03_MPAD 0 "No_Fail_Present" 1 "Fail_Present";
VAL_ 2654339245 CurrentCanNMState_FD03_MPAD 0 "Uninitialized_State" 1 "Bus_Sleep_State" 2 "Prepare_Bus_State" 3 "Ready_Sleep_State" 4 "Normal_Operation_State" 5 "Repeat_Message_State" 6 "Synchronize_State" 7 "Offline_State";
VAL_ 2654339233 WakeupSource_FD03_ADCAM 0 "No_Wakeup" 1 "IGN_ON" 129 "FD1_Psv_WU" 130 "FD2_Psv_WU" 131 "FD3_Psv_WU" 132 "FD4_Psv_WU" 133 "FD5_Psv_WU" 134 "FD6_Psv_WU" 135 "FD7_Psv_WU" 136 "FD8_Psv_WU" 137 "FD9_Psv_WU" 138 "FD10_Psv_WU" 139 "FD11_Psv_WU" 140 "FD12_Psv_WU" 141 "FD13_Psv_WU" 142 "FD14_Psv_WU" 143 "FD15_Psv_WU" 144 "FD16_Psv_WU" 145 "FD17_Psv_WU" 146 "FD18_Psv_WU" 147 "FD19_Psv_WU" 148 "FD20_Psv_WU" 149 "FD21_Psv_WU" 150 "FD22_Psv_WU" 151 "FD23_Psv_WU" 152 "FD24_Psv_WU" 153 "FD25_Psv_WU" 154 "FD26_Psv_WU" 155 "FD27_Psv_WU" 156 "FD28_Psv_WU" 157 "FD29_Psv_WU" 158 "BHCAN_Psv_WU" 159 "CCAN_Psv_WU" 254 "WUSource_Not_Listed";
VAL_ 2654339233 StayActiveSource_FD03_ADCAM 0 "CANNM_Ready_Sleep" 1 "IGN_ON" 2 "NonDefault_Diag" 4 "ING_OFF_NormSt_RptSt" 1073741824 "SASource_Not_Listed";
VAL_ 2654339233 PreviousCanNMState_FD03_ADCAM 0 "Uninitialized_State" 1 "Bus_Sleep_State" 2 "Prepare_Bus_State" 3 "Ready_Sleep_State" 4 "Normal_Operation_State" 5 "Repeat_Message_State" 6 "Synchronize_State" 7 "Offline_State";
VAL_ 2654339233 GenericFailSts_FD03_ADCAM 0 "No_Fail_Present" 1 "Fail_Present";
VAL_ 2654339233 EOL_FD03_ADCAM 0 "No_EOL_Programming" 1 "EOL_Programming";
VAL_ 2654339233 DES_FD03_ADCAM 0 "Error_Active_state" 1 "Error_passive_warning_state" 2 "Bus_off_state" 3 "Not_used";
VAL_ 2654339233 CurrentFailSts_FD03_ADCAM 0 "No_Fail_Present" 1 "Fail_Present";
VAL_ 2654339233 CurrentCanNMState_FD03_ADCAM 0 "Uninitialized_State" 1 "Bus_Sleep_State" 2 "Prepare_Bus_State" 3 "Ready_Sleep_State" 4 "Normal_Operation_State" 5 "Repeat_Message_State" 6 "Synchronize_State" 7 "Offline_State";
VAL_ 2654486689 CBV_bit6_PartialNtwInfBit 0 "Partial_Network_info_contained" 1 "No_Partial_Network_info_contained";
VAL_ 2654486701 CBV_bit6_PartialNtwInfBit 0 "Partial_Network_info_contained" 1 "No_Partial_Network_info_contained";
VAL_ 2654486701 CBV_bit4_ActiveWakeupBit 0 "PassiveWakeup" 1 "ActiveWakeup";
VAL_ 2654486689 CBV_bit4_ActiveWakeupBit 0 "PassiveWakeup" 1 "ActiveWakeup";
VAL_ 2654486701 CBV_bit3_NMCoordinatorBit 0 "Synch_shutdown_not_requested" 1 "Synch_shutdown_requested";
VAL_ 2654486689 CBV_bit3_NMCoordinatorBit 0 "Synch_shutdown_not_requested" 1 "Synch_shutdown_requested";
VAL_ 2654486689 CBV_bit0_RepeatMessageRequestBit 0 "Repeat_Msg_State_not_requested" 1 "Repeat_Msg_State_requested";
VAL_ 2654486701 CBV_bit0_RepeatMessageRequestBit 0 "Repeat_Msg_State_not_requested" 1 "Repeat_Msg_State_requested";
VAL_ 1898 Update_Status_MPAD 0 "Not Updating" 1 "Update in Progress" 2 "Update Completed" 3 "Fault Update Failed";
VAL_ 1898 Download_Status_MPAD 0 "Not Downloading" 1 "Download in Progress" 2 "Download Completed" 3 "Fault Download Failed";
VAL_ 1898 Big_ECU_Ready_MPAD 0 "Not Ready" 1 "Ready for Transfer" 2 "ECU ID not Downloaded" 3 "Ready for Install";
VAL_ 1900 Update_Status_ADCAM 0 "Not Updating" 1 "Update in Progress" 2 "Update Completed" 3 "Fault Update Failed";
VAL_ 1900 Download_Status_ADCAM 0 "Not Downloading" 1 "Download in Progress" 2 "Download Completed" 3 "Fault Download Failed";
VAL_ 1900 Big_ECU_Ready_ADCAM 0 "Not Ready" 1 "Ready for Transfer" 2 "ECU ID not Downloaded" 3 "Ready for Install";
VAL_ 2654339161 WakeupSource_FD16_MCPB 0 "No_Wakeup";
VAL_ 2654339161 WakeupSource_FD05_MCPB 0 "No_Wakeup";
VAL_ 2654339161 PreviousCanNMState_FD16_MCPB 0 "Uninitialized State" 1 "Bus-Sleep State" 2 "Prepare-Bus State" 3 "Ready-Sleep State" 4 "Normal Operation State" 5 "Repeat Message State" 6 "Synchronize State" 7 "Offline State";
VAL_ 2654339161 PreviousCanNMState_FD05_MCPB 0 "Uninitialized State" 1 "Bus-Sleep State" 2 "Prepare-Bus State" 3 "Ready-Sleep State" 4 "Normal Operation State" 5 "Repeat Message State" 6 "Synchronize State" 7 "Offline State";
VAL_ 2654339161 GenericFailSts_FD05_MCPB 0 "No_Fail_Present" 1 "Fail_Present";
VAL_ 2654339161 EOL_FD16_MCPB 0 "No_EOL_Programming" 1 "EOL_Programming";
VAL_ 2654339161 EOL_FD05_MCPB 0 "No_EOL_Programming" 1 "EOL_Programming";
VAL_ 2654339161 DES_FD05_MCPB 0 "Error_Active_state" 1 "Error_passive_warning_state" 2 "Bus_off_state" 3 "Not_used";
VAL_ 2654339161 CurrentFailSts_FD05_MCPB 0 "No_Fail_Present" 1 "Fail_Present";
VAL_ 2654339161 CurrentCanNMState_FD16_MCPB 0 "Uninitialized State" 1 "Bus-Sleep State" 2 "Prepare-Bus State" 3 "Ready-Sleep State" 4 "Normal Operation State" 5 "Repeat Message State" 6 "Synchronize State" 7 "Offline State";
VAL_ 2654339161 CurrentCanNMState_FD05_MCPB 0 "Uninitialized State" 1 "Bus-Sleep State" 2 "Prepare-Bus State" 3 "Ready-Sleep State" 4 "Normal Operation State" 5 "Repeat Message State" 6 "Synchronize State" 7 "Offline State";
VAL_ 2654339160 WakeupSource_FD16_MCPA 0 "No_Wakeup";
VAL_ 2654339160 WakeupSource_FD05_MCPA 0 "No_Wakeup";
VAL_ 2654339160 PreviousCanNMState_FD16_MCPA 0 "Uninitialized State" 1 "Bus-Sleep State" 2 "Prepare-Bus State" 3 "Ready-Sleep State" 4 "Normal Operation State" 5 "Repeat Message State" 6 "Synchronize State" 7 "Offline State";
VAL_ 2654339160 PreviousCanNMState_FD05_MCPA 0 "Uninitialized State" 1 "Bus-Sleep State" 2 "Prepare-Bus State" 3 "Ready-Sleep State" 4 "Normal Operation State" 5 "Repeat Message State" 6 "Synchronize State" 7 "Offline State";
VAL_ 2654339160 GenericFailSts_FD05_MCPA 0 "No_Fail_Present" 1 "Fail_Present";
VAL_ 2654339160 EOL_FD16_MCPA 0 "No_EOL_Programming" 1 "EOL_Programming";
VAL_ 2654339160 EOL_FD05_MCPA 0 "No_EOL_Programming" 1 "EOL_Programming";
VAL_ 2654339160 DES_FD05_MCPA 0 "Error_Active_state" 1 "Error_passive_warning_state" 2 "Bus_off_state" 3 "Not_used";
VAL_ 2654339160 CurrentFailSts_FD05_MCPA 0 "No_Fail_Present" 1 "Fail_Present";
VAL_ 2654339160 CurrentCanNMState_FD16_MCPA 0 "Uninitialized State" 1 "Bus-Sleep State" 2 "Prepare-Bus State" 3 "Ready-Sleep State" 4 "Normal Operation State" 5 "Repeat Message State" 6 "Synchronize State" 7 "Offline State";
VAL_ 2654339160 CurrentCanNMState_FD05_MCPA 0 "Uninitialized State" 1 "Bus-Sleep State" 2 "Prepare-Bus State" 3 "Ready-Sleep State" 4 "Normal Operation State" 5 "Repeat Message State" 6 "Synchronize State" 7 "Offline State";
VAL_ 2654339161 GenericFailSts_FD16_MCPB 0 "No_Fail_Present" 1 "Fail_Present";
VAL_ 2654339161 DES_FD16_MCPB 0 "Error_Active_state" 1 "Error_passive_warning_state" 2 "Bus_off_state" 3 "Not_used";
VAL_ 2654339161 CurrentFailSts_FD16_MCPB 0 "No_Fail_Present" 1 "Fail_Present";
VAL_ 2654339160 GenericFailSts_FD16_MCPA 0 "No_Fail_Present" 1 "Fail_Present";
VAL_ 2654339160 DES_FD16_MCPA 0 "Error_Active_state" 1 "Error_passive_warning_state" 2 "Bus_off_state" 3 "Not_used";
VAL_ 2654339160 CurrentFailSts_FD16_MCPA 0 "No_Fail_Present" 1 "Fail_Present";
VAL_ 145 PlugAndChargeReq 0 "Inactive" 1 "Active";
VAL_ 145 StopOnTraffic_Req 0 "Off" 1 "Warning" 2 "Warning_and_Auto_Stop";
VAL_ 145 SpeedAdjust_Req 0 "Warning_only" 1 "Warning_and_Speed_adjust";
VAL_ 145 RouteGuidance_Req 0 "Off" 1 "On";
VAL_ 145 EmergencyCorridorAssist_Req 0 "Off" 1 "On";
